[part 6 of 10: package /E40_Platform_System_SystemPackage/Components]
AUTOSAR XML (schema 4-2-1)
package /E40_Platform_System_SystemPackage/Components  (continued)
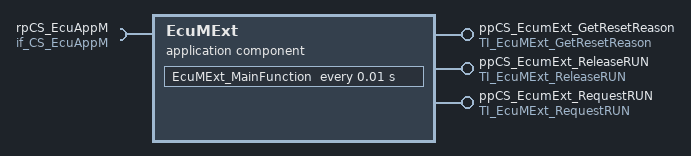
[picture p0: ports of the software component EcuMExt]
  application sw component type EcuMExt
    provide port ppCS_EcumExt_GetResetReason: server-com-spec{operation=GetResetReason, queue-length=1}, provided-interface=TI_EcuMExt_GetResetReason
    provide port ppCS_EcumExt_ReleaseRUN: server-com-spec{operation=ReleaseRUN, queue-length=1}, provided-interface=TI_EcuMExt_ReleaseRUN
    provide port ppCS_EcumExt_RequestRUN: server-com-spec{operation=RequestRUN, queue-length=1}, provided-interface=TI_EcuMExt_RequestRUN
    require port rpCS_EcuAppM: required-interface=if_CS_EcuAppM
    behavior IB_EcuMExt
      operation invoked event OIE_ppCS_EcumExt_GetResetReason_EcuMExt_GetResetReasonTrigByGetResetReason: start-on-event=EcuMExt_GetResetReason, operation=ppCS_EcumExt_GetResetReason.GetResetReason
      timing event TEEcuMExt_MainFunction: start-on-event=EcuMExt_MainFunction, period=0.01
      operation invoked event OIE_ppCS_EcumExt_ReleaseRUN_EcuMExt_ReleaseRUNTrigByReleaseRUN: start-on-event=EcuMExt_ReleaseRUN, operation=ppCS_EcumExt_ReleaseRUN.ReleaseRUN
      operation invoked event OIE_ppCS_EcumExt_RequestRUN_EcuMExt_RequestRUNTrigByRequestRUN: start-on-event=EcuMExt_RequestRUN, operation=ppCS_EcumExt_RequestRUN.RequestRUN
      port-api-options:
        enable-take-address=false, indirect-api=false, port=ppCS_EcumExt_GetResetReason
        enable-take-address=false, indirect-api=false, port=ppCS_EcumExt_ReleaseRUN
        enable-take-address=false, indirect-api=false, port=ppCS_EcumExt_RequestRUN
        enable-take-address=false, indirect-api=false, port=rpCS_EcuAppM
      4 x runnable, all with can-be-invoked-concurrently=true:
        EcuMExt_GetResetReason
          sync call OA_rpCS_EcuAppM_Init: operation=rpCS_EcuAppM.Init, timeout=0.0
          sync call OA_rpCS_EcuAppM_EcuAppM_SetWakeupSources: operation=rpCS_EcuAppM.EcuAppM_SetWakeupSources, timeout=0.0
        EcuMExt_MainFunction
          sync call OA_rpCS_EcuAppM_Init: operation=rpCS_EcuAppM.Init, timeout=0.0
          sync call OA_rpCS_EcuAppM_EcuAppM_SetWakeupSources: operation=rpCS_EcuAppM.EcuAppM_SetWakeupSources, timeout=0.0
        EcuMExt_ReleaseRUN
          sync call OA_rpCS_EcuAppM_Init: operation=rpCS_EcuAppM.Init, timeout=0.0
          sync call OA_rpCS_EcuAppM_EcuAppM_SetWakeupSources: operation=rpCS_EcuAppM.EcuAppM_SetWakeupSources, timeout=0.0
        EcuMExt_RequestRUN
          sync call OA_rpCS_EcuAppM_Init: operation=rpCS_EcuAppM.Init, timeout=0.0
          sync call OA_rpCS_EcuAppM_EcuAppM_SetWakeupSources: operation=rpCS_EcuAppM.EcuAppM_SetWakeupSources, timeout=0.0
  swc implementation IMPL_EcuMExt: programming-language=C, behavior=IB_EcuMExt
    code-descriptors:
      code CodeDescriptor
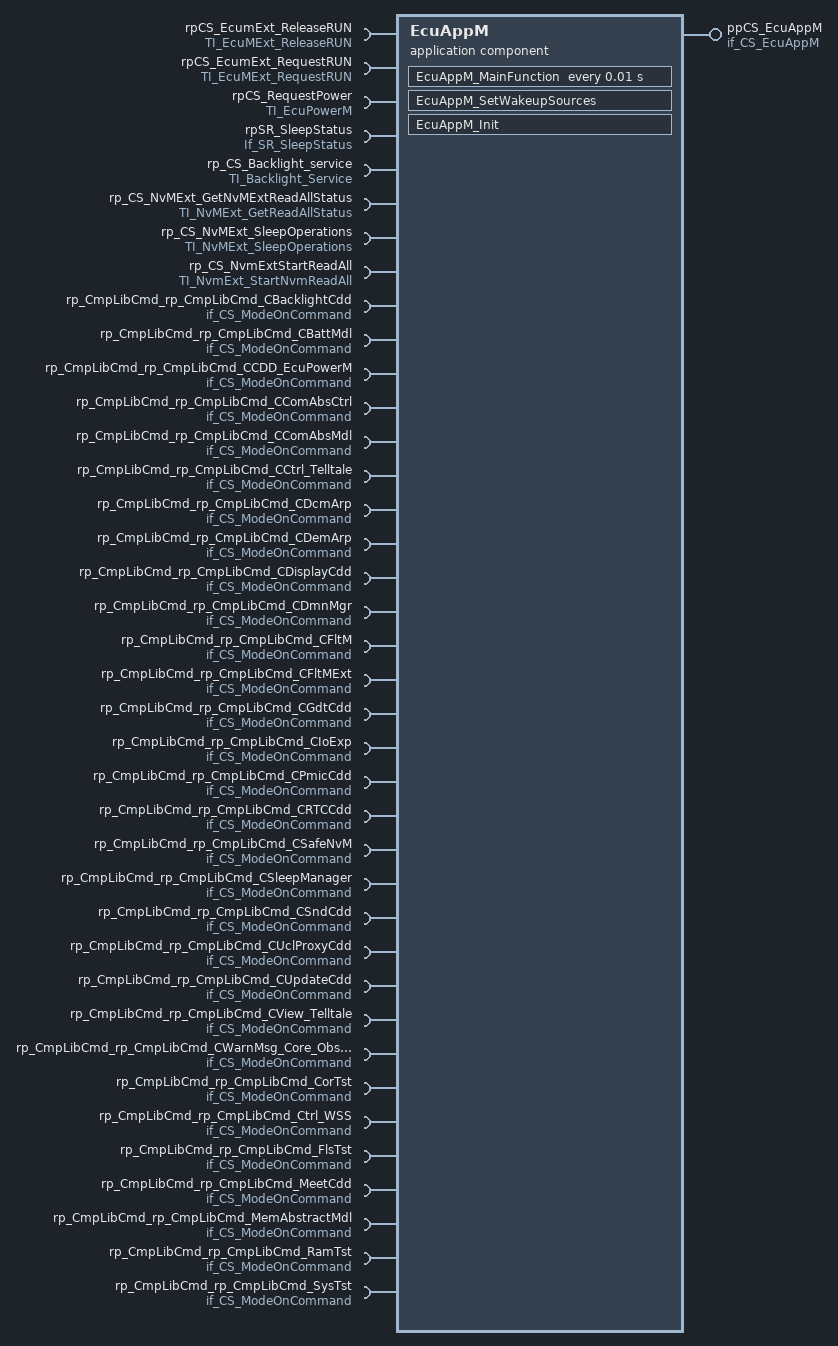
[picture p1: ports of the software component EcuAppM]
  application sw component type EcuAppM
    provide port ppCS_EcuAppM: provided-com-specs=[{operation=EcuAppM_SetWakeupSources, queue-length=1}, {operation=if_CS_EcuAppM/Init, queue-length=1}], provided-interface=if_CS_EcuAppM
    38 x require port:
      rpCS_EcumExt_ReleaseRUN: required-interface=TI_EcuMExt_ReleaseRUN
      rpCS_EcumExt_RequestRUN: required-interface=TI_EcuMExt_RequestRUN
      rpCS_RequestPower: required-interface=TI_EcuPowerM
      rpSR_SleepStatus: nonqueued-receiver-com-spec{data-element=SleepManager_SleepStatus, init-value=constant-reference=EcuAppMSleepManager_SleepStatusValue0}, required-interface=If_SR_SleepStatus
      rp_CS_Backlight_service: required-interface=TI_Backlight_Service
      rp_CS_NvMExt_GetNvMExtReadAllStatus: required-interface=TI_NvMExt_GetReadAllStatus
      rp_CS_NvMExt_SleepOperations: required-interface=TI_NvMExt_SleepOperations
      rp_CS_NvmExtStartReadAll: required-interface=TI_NvmExt_StartNvmReadAll
      rp_CmpLibCmd_rp_CmpLibCmd_CBacklightCdd: required-interface=if_CS_ModeOnCommand
      rp_CmpLibCmd_rp_CmpLibCmd_CBattMdl: required-interface=if_CS_ModeOnCommand
      rp_CmpLibCmd_rp_CmpLibCmd_CCDD_EcuPowerM: required-interface=if_CS_ModeOnCommand
      rp_CmpLibCmd_rp_CmpLibCmd_CComAbsCtrl: required-interface=if_CS_ModeOnCommand
      rp_CmpLibCmd_rp_CmpLibCmd_CComAbsMdl: required-interface=if_CS_ModeOnCommand
      rp_CmpLibCmd_rp_CmpLibCmd_CCtrl_Telltale: required-interface=if_CS_ModeOnCommand
      rp_CmpLibCmd_rp_CmpLibCmd_CDcmArp: required-interface=if_CS_ModeOnCommand
      rp_CmpLibCmd_rp_CmpLibCmd_CDemArp: required-interface=if_CS_ModeOnCommand
      rp_CmpLibCmd_rp_CmpLibCmd_CDisplayCdd: required-interface=if_CS_ModeOnCommand
      rp_CmpLibCmd_rp_CmpLibCmd_CDmnMgr: required-interface=if_CS_ModeOnCommand
      rp_CmpLibCmd_rp_CmpLibCmd_CFltM: required-interface=if_CS_ModeOnCommand
      rp_CmpLibCmd_rp_CmpLibCmd_CFltMExt: required-interface=if_CS_ModeOnCommand
      rp_CmpLibCmd_rp_CmpLibCmd_CGdtCdd: required-interface=if_CS_ModeOnCommand
      rp_CmpLibCmd_rp_CmpLibCmd_CIoExp: required-interface=if_CS_ModeOnCommand
      rp_CmpLibCmd_rp_CmpLibCmd_CPmicCdd: required-interface=if_CS_ModeOnCommand
      rp_CmpLibCmd_rp_CmpLibCmd_CRTCCdd: required-interface=if_CS_ModeOnCommand
      rp_CmpLibCmd_rp_CmpLibCmd_CSafeNvM: required-interface=if_CS_ModeOnCommand
      rp_CmpLibCmd_rp_CmpLibCmd_CSleepManager: required-interface=if_CS_ModeOnCommand
      rp_CmpLibCmd_rp_CmpLibCmd_CSndCdd: required-interface=if_CS_ModeOnCommand
      rp_CmpLibCmd_rp_CmpLibCmd_CUclProxyCdd: required-interface=if_CS_ModeOnCommand
      rp_CmpLibCmd_rp_CmpLibCmd_CUpdateCdd: required-interface=if_CS_ModeOnCommand
      rp_CmpLibCmd_rp_CmpLibCmd_CView_Telltale: required-interface=if_CS_ModeOnCommand
      rp_CmpLibCmd_rp_CmpLibCmd_CWarnMsg_Core_Observer: required-interface=if_CS_ModeOnCommand
      rp_CmpLibCmd_rp_CmpLibCmd_CorTst: required-interface=if_CS_ModeOnCommand
      rp_CmpLibCmd_rp_CmpLibCmd_Ctrl_WSS: required-interface=if_CS_ModeOnCommand
      rp_CmpLibCmd_rp_CmpLibCmd_FlsTst: required-interface=if_CS_ModeOnCommand
      rp_CmpLibCmd_rp_CmpLibCmd_MeetCdd: required-interface=if_CS_ModeOnCommand
      rp_CmpLibCmd_rp_CmpLibCmd_MemAbstractMdl: required-interface=if_CS_ModeOnCommand
      rp_CmpLibCmd_rp_CmpLibCmd_RamTst: required-interface=if_CS_ModeOnCommand
      rp_CmpLibCmd_rp_CmpLibCmd_SysTst: required-interface=if_CS_ModeOnCommand
    behavior IB_EcuAppM
      operation invoked event OIE_ppCS_EcuAppM_EcuAppM_SetWakeupSourcesTrigByEcuAppM_SetWakeupSources: start-on-event=EcuAppM_SetWakeupSources, operation=ppCS_EcuAppM.EcuAppM_SetWakeupSources
      operation invoked event OIE_ppCS_EcuAppM_EcuAppM_InitTrigByInit: start-on-event=EcuAppM_Init, operation=ppCS_EcuAppM.Init
      timing event TEEcuAppM_MainFunction: start-on-event=EcuAppM_MainFunction, period=0.01
      port-api-options:
        enable-take-address=false, indirect-api=false, port=ppCS_EcuAppM
        enable-take-address=false, indirect-api=false, port=rpCS_EcumExt_ReleaseRUN
        enable-take-address=false, indirect-api=false, port=rpCS_EcumExt_RequestRUN
        enable-take-address=false, indirect-api=false, port=rpCS_RequestPower
        enable-take-address=false, indirect-api=false, port=EcuAppM/rpSR_SleepStatus
        enable-take-address=false, indirect-api=false, port=rp_CS_Backlight_service
        enable-take-address=false, indirect-api=false, port=EcuAppM/rp_CS_NvMExt_GetNvMExtReadAllStatus
        enable-take-address=false, indirect-api=false, port=EcuAppM/rp_CS_NvMExt_SleepOperations
        enable-take-address=false, indirect-api=false, port=rp_CS_NvmExtStartReadAll
        enable-take-address=false, indirect-api=false, port=rp_CmpLibCmd_rp_CmpLibCmd_CBacklightCdd
        enable-take-address=false, indirect-api=false, port=rp_CmpLibCmd_rp_CmpLibCmd_CBattMdl
        enable-take-address=false, indirect-api=false, port=rp_CmpLibCmd_rp_CmpLibCmd_CCDD_EcuPowerM
        enable-take-address=false, indirect-api=false, port=rp_CmpLibCmd_rp_CmpLibCmd_CComAbsCtrl
        enable-take-address=false, indirect-api=false, port=rp_CmpLibCmd_rp_CmpLibCmd_CComAbsMdl
        enable-take-address=false, indirect-api=false, port=rp_CmpLibCmd_rp_CmpLibCmd_CCtrl_Telltale
        enable-take-address=false, indirect-api=false, port=rp_CmpLibCmd_rp_CmpLibCmd_CDcmArp
        enable-take-address=false, indirect-api=false, port=rp_CmpLibCmd_rp_CmpLibCmd_CDemArp
        enable-take-address=false, indirect-api=false, port=rp_CmpLibCmd_rp_CmpLibCmd_CDisplayCdd
        enable-take-address=false, indirect-api=false, port=rp_CmpLibCmd_rp_CmpLibCmd_CDmnMgr
        enable-take-address=false, indirect-api=false, port=rp_CmpLibCmd_rp_CmpLibCmd_CFltM
        enable-take-address=false, indirect-api=false, port=rp_CmpLibCmd_rp_CmpLibCmd_CFltMExt
        enable-take-address=false, indirect-api=false, port=rp_CmpLibCmd_rp_CmpLibCmd_CGdtCdd
        enable-take-address=false, indirect-api=false, port=rp_CmpLibCmd_rp_CmpLibCmd_CIoExp
        enable-take-address=false, indirect-api=false, port=rp_CmpLibCmd_rp_CmpLibCmd_CPmicCdd
        enable-take-address=false, indirect-api=false, port=rp_CmpLibCmd_rp_CmpLibCmd_CRTCCdd
        enable-take-address=false, indirect-api=false, port=rp_CmpLibCmd_rp_CmpLibCmd_CSafeNvM
        enable-take-address=false, indirect-api=false, port=rp_CmpLibCmd_rp_CmpLibCmd_CSleepManager
        enable-take-address=false, indirect-api=false, port=rp_CmpLibCmd_rp_CmpLibCmd_CSndCdd
        enable-take-address=false, indirect-api=false, port=rp_CmpLibCmd_rp_CmpLibCmd_CUclProxyCdd
        enable-take-address=false, indirect-api=false, port=rp_CmpLibCmd_rp_CmpLibCmd_CUpdateCdd
        enable-take-address=false, indirect-api=false, port=rp_CmpLibCmd_rp_CmpLibCmd_CView_Telltale
        enable-take-address=false, indirect-api=false, port=rp_CmpLibCmd_rp_CmpLibCmd_CWarnMsg_Core_Observer
        enable-take-address=false, indirect-api=false, port=rp_CmpLibCmd_rp_CmpLibCmd_CorTst
        enable-take-address=false, indirect-api=false, port=rp_CmpLibCmd_rp_CmpLibCmd_Ctrl_WSS
        enable-take-address=false, indirect-api=false, port=rp_CmpLibCmd_rp_CmpLibCmd_FlsTst
        enable-take-address=false, indirect-api=false, port=rp_CmpLibCmd_rp_CmpLibCmd_MeetCdd
        enable-take-address=false, indirect-api=false, port=rp_CmpLibCmd_rp_CmpLibCmd_MemAbstractMdl
        enable-take-address=false, indirect-api=false, port=rp_CmpLibCmd_rp_CmpLibCmd_RamTst
        enable-take-address=false, indirect-api=false, port=rp_CmpLibCmd_rp_CmpLibCmd_SysTst
      runnable EcuAppM_SetWakeupSources: can-be-invoked-concurrently=true
        data-receive-point-by-arguments:
          access DRA_rpSR_SleepStatus_SleepManager_SleepStatus: accessed-variable=rpSR_SleepStatus.SleepManager_SleepStatus
        42 x sync call, all with timeout=0.0:
          OA_rpCS_EcumExt_ReleaseRUN_ReleaseRUN: operation=rpCS_EcumExt_ReleaseRUN.ReleaseRUN
          OA_rpCS_EcumExt_RequestRUN_RequestRUN: operation=rpCS_EcumExt_RequestRUN.RequestRUN
          OA_rpCS_RequestPower_EcuPowerM_RequestPower: operation=rpCS_RequestPower.EcuPowerM_RequestPower
          OA_rpCS_RequestPower_EcuPowerM_GetDeviceStatus: operation=rpCS_RequestPower.EcuPowerM_GetDeviceStatus
          OA_rp_CS_Backlight_service_SetBrightnessValue: operation=rp_CS_Backlight_service.SetBrightnessValue
          OA_rp_CS_Backlight_service_GetBrightnessValue: operation=rp_CS_Backlight_service.GetBrightnessValue
          OA_rp_CS_Backlight_service_GetThermalValue: operation=rp_CS_Backlight_service.GetThermalValue
          OA_rp_CS_NvMExt_GetNvMExtReadAllStatus_NvmExt_GetNvMReadAllStatus: operation=rp_CS_NvMExt_GetNvMExtReadAllStatus.NvmExt_GetNvMReadAllStatus
          OA_rp_CS_NvMExt_SleepOperations_NvMExt_ReadytoSleep: operation=rp_CS_NvMExt_SleepOperations.NvMExt_ReadytoSleep
          OA_rp_CS_NvMExt_SleepOperations_NvMExt_RequestSleep: operation=rp_CS_NvMExt_SleepOperations.NvMExt_RequestSleep
          OA_rp_CS_NvMExt_SleepOperations_NvMExt_CancelSleep: operation=rp_CS_NvMExt_SleepOperations.NvMExt_CancelSleep
          OA_rp_CS_NvmExtStartReadAll_NvMExt_ReadAll: operation=rp_CS_NvmExtStartReadAll.NvMExt_ReadAll
          OA_rp_CmpLibCmd_rp_CmpLibCmd_CBacklightCdd_Impl_OnCommand: operation=rp_CmpLibCmd_rp_CmpLibCmd_CBacklightCdd.Impl_OnCommand
          OA_rp_CmpLibCmd_rp_CmpLibCmd_CBattMdl_Impl_OnCommand: operation=rp_CmpLibCmd_rp_CmpLibCmd_CBattMdl.Impl_OnCommand
          OA_rp_CmpLibCmd_rp_CmpLibCmd_CCDD_EcuPowerM_Impl_OnCommand: operation=rp_CmpLibCmd_rp_CmpLibCmd_CCDD_EcuPowerM.Impl_OnCommand
          OA_rp_CmpLibCmd_rp_CmpLibCmd_CComAbsCtrl_Impl_OnCommand: operation=rp_CmpLibCmd_rp_CmpLibCmd_CComAbsCtrl.Impl_OnCommand
          OA_rp_CmpLibCmd_rp_CmpLibCmd_CComAbsMdl_Impl_OnCommand: operation=rp_CmpLibCmd_rp_CmpLibCmd_CComAbsMdl.Impl_OnCommand
          OA_rp_CmpLibCmd_rp_CmpLibCmd_CCtrl_Telltale_Impl_OnCommand: operation=rp_CmpLibCmd_rp_CmpLibCmd_CCtrl_Telltale.Impl_OnCommand
          OA_rp_CmpLibCmd_rp_CmpLibCmd_CDcmArp_Impl_OnCommand: operation=rp_CmpLibCmd_rp_CmpLibCmd_CDcmArp.Impl_OnCommand
          OA_rp_CmpLibCmd_rp_CmpLibCmd_CDemArp_Impl_OnCommand: operation=rp_CmpLibCmd_rp_CmpLibCmd_CDemArp.Impl_OnCommand
          OA_rp_CmpLibCmd_rp_CmpLibCmd_CDisplayCdd_Impl_OnCommand: operation=rp_CmpLibCmd_rp_CmpLibCmd_CDisplayCdd.Impl_OnCommand
          OA_rp_CmpLibCmd_rp_CmpLibCmd_CDmnMgr_Impl_OnCommand: operation=rp_CmpLibCmd_rp_CmpLibCmd_CDmnMgr.Impl_OnCommand
          OA_rp_CmpLibCmd_rp_CmpLibCmd_CFltM_Impl_OnCommand: operation=rp_CmpLibCmd_rp_CmpLibCmd_CFltM.Impl_OnCommand
          OA_rp_CmpLibCmd_rp_CmpLibCmd_CFltMExt_Impl_OnCommand: operation=rp_CmpLibCmd_rp_CmpLibCmd_CFltMExt.Impl_OnCommand
          OA_rp_CmpLibCmd_rp_CmpLibCmd_CGdtCdd_Impl_OnCommand: operation=rp_CmpLibCmd_rp_CmpLibCmd_CGdtCdd.Impl_OnCommand
          OA_rp_CmpLibCmd_rp_CmpLibCmd_CIoExp_Impl_OnCommand: operation=rp_CmpLibCmd_rp_CmpLibCmd_CIoExp.Impl_OnCommand
          OA_rp_CmpLibCmd_rp_CmpLibCmd_CPmicCdd_Impl_OnCommand: operation=rp_CmpLibCmd_rp_CmpLibCmd_CPmicCdd.Impl_OnCommand
          OA_rp_CmpLibCmd_rp_CmpLibCmd_CRTCCdd_Impl_OnCommand: operation=rp_CmpLibCmd_rp_CmpLibCmd_CRTCCdd.Impl_OnCommand
          OA_rp_CmpLibCmd_rp_CmpLibCmd_CSafeNvM_Impl_OnCommand: operation=rp_CmpLibCmd_rp_CmpLibCmd_CSafeNvM.Impl_OnCommand
          OA_rp_CmpLibCmd_rp_CmpLibCmd_CSleepManager_Impl_OnCommand: operation=rp_CmpLibCmd_rp_CmpLibCmd_CSleepManager.Impl_OnCommand
          OA_rp_CmpLibCmd_rp_CmpLibCmd_CSndCdd_Impl_OnCommand: operation=rp_CmpLibCmd_rp_CmpLibCmd_CSndCdd.Impl_OnCommand
          OA_rp_CmpLibCmd_rp_CmpLibCmd_CUclProxyCdd_Impl_OnCommand: operation=rp_CmpLibCmd_rp_CmpLibCmd_CUclProxyCdd.Impl_OnCommand
          OA_rp_CmpLibCmd_rp_CmpLibCmd_CUpdateCdd_Impl_OnCommand: operation=rp_CmpLibCmd_rp_CmpLibCmd_CUpdateCdd.Impl_OnCommand
          OA_rp_CmpLibCmd_rp_CmpLibCmd_CView_Telltale_Impl_OnCommand: operation=rp_CmpLibCmd_rp_CmpLibCmd_CView_Telltale.Impl_OnCommand
          OA_rp_CmpLibCmd_rp_CmpLibCmd_CWarnMsg_Core_Observer_Impl_OnCommand: operation=rp_CmpLibCmd_rp_CmpLibCmd_CWarnMsg_Core_Observer.Impl_OnCommand
          OA_rp_CmpLibCmd_rp_CmpLibCmd_CorTst_Impl_OnCommand: operation=rp_CmpLibCmd_rp_CmpLibCmd_CorTst.Impl_OnCommand
          OA_rp_CmpLibCmd_rp_CmpLibCmd_Ctrl_WSS_Impl_OnCommand: operation=rp_CmpLibCmd_rp_CmpLibCmd_Ctrl_WSS.Impl_OnCommand
          OA_rp_CmpLibCmd_rp_CmpLibCmd_FlsTst_Impl_OnCommand: operation=rp_CmpLibCmd_rp_CmpLibCmd_FlsTst.Impl_OnCommand
          OA_rp_CmpLibCmd_rp_CmpLibCmd_MeetCdd_Impl_OnCommand: operation=rp_CmpLibCmd_rp_CmpLibCmd_MeetCdd.Impl_OnCommand
          OA_rp_CmpLibCmd_rp_CmpLibCmd_MemAbstractMdl_Impl_OnCommand: operation=rp_CmpLibCmd_rp_CmpLibCmd_MemAbstractMdl.Impl_OnCommand
          OA_rp_CmpLibCmd_rp_CmpLibCmd_RamTst_Impl_OnCommand: operation=rp_CmpLibCmd_rp_CmpLibCmd_RamTst.Impl_OnCommand
          OA_rp_CmpLibCmd_rp_CmpLibCmd_SysTst_Impl_OnCommand: operation=rp_CmpLibCmd_rp_CmpLibCmd_SysTst.Impl_OnCommand
      runnable EcuAppM_Init: can-be-invoked-concurrently=true
        data-receive-point-by-arguments:
          access DRA_rpSR_SleepStatus_SleepManager_SleepStatus: accessed-variable=rpSR_SleepStatus.SleepManager_SleepStatus
        42 x sync call, all with timeout=0.0:
          OA_rpCS_EcumExt_ReleaseRUN_ReleaseRUN: operation=rpCS_EcumExt_ReleaseRUN.ReleaseRUN
          OA_rpCS_EcumExt_RequestRUN_RequestRUN: operation=rpCS_EcumExt_RequestRUN.RequestRUN
          OA_rpCS_RequestPower_EcuPowerM_RequestPower: operation=rpCS_RequestPower.EcuPowerM_RequestPower
          OA_rpCS_RequestPower_EcuPowerM_GetDeviceStatus: operation=rpCS_RequestPower.EcuPowerM_GetDeviceStatus
          OA_rp_CS_Backlight_service_SetBrightnessValue: operation=rp_CS_Backlight_service.SetBrightnessValue
          OA_rp_CS_Backlight_service_GetBrightnessValue: operation=rp_CS_Backlight_service.GetBrightnessValue
          OA_rp_CS_Backlight_service_GetThermalValue: operation=rp_CS_Backlight_service.GetThermalValue
          OA_rp_CS_NvMExt_GetNvMExtReadAllStatus_NvmExt_GetNvMReadAllStatus: operation=rp_CS_NvMExt_GetNvMExtReadAllStatus.NvmExt_GetNvMReadAllStatus
          OA_rp_CS_NvMExt_SleepOperations_NvMExt_ReadytoSleep: operation=rp_CS_NvMExt_SleepOperations.NvMExt_ReadytoSleep
          OA_rp_CS_NvMExt_SleepOperations_NvMExt_RequestSleep: operation=rp_CS_NvMExt_SleepOperations.NvMExt_RequestSleep
          OA_rp_CS_NvMExt_SleepOperations_NvMExt_CancelSleep: operation=rp_CS_NvMExt_SleepOperations.NvMExt_CancelSleep
          OA_rp_CS_NvmExtStartReadAll_NvMExt_ReadAll: operation=rp_CS_NvmExtStartReadAll.NvMExt_ReadAll
          OA_rp_CmpLibCmd_rp_CmpLibCmd_CBacklightCdd_Impl_OnCommand: operation=rp_CmpLibCmd_rp_CmpLibCmd_CBacklightCdd.Impl_OnCommand
          OA_rp_CmpLibCmd_rp_CmpLibCmd_CBattMdl_Impl_OnCommand: operation=rp_CmpLibCmd_rp_CmpLibCmd_CBattMdl.Impl_OnCommand
          OA_rp_CmpLibCmd_rp_CmpLibCmd_CCDD_EcuPowerM_Impl_OnCommand: operation=rp_CmpLibCmd_rp_CmpLibCmd_CCDD_EcuPowerM.Impl_OnCommand
          OA_rp_CmpLibCmd_rp_CmpLibCmd_CComAbsCtrl_Impl_OnCommand: operation=rp_CmpLibCmd_rp_CmpLibCmd_CComAbsCtrl.Impl_OnCommand
          OA_rp_CmpLibCmd_rp_CmpLibCmd_CComAbsMdl_Impl_OnCommand: operation=rp_CmpLibCmd_rp_CmpLibCmd_CComAbsMdl.Impl_OnCommand
          OA_rp_CmpLibCmd_rp_CmpLibCmd_CCtrl_Telltale_Impl_OnCommand: operation=rp_CmpLibCmd_rp_CmpLibCmd_CCtrl_Telltale.Impl_OnCommand
          OA_rp_CmpLibCmd_rp_CmpLibCmd_CDcmArp_Impl_OnCommand: operation=rp_CmpLibCmd_rp_CmpLibCmd_CDcmArp.Impl_OnCommand
          OA_rp_CmpLibCmd_rp_CmpLibCmd_CDemArp_Impl_OnCommand: operation=rp_CmpLibCmd_rp_CmpLibCmd_CDemArp.Impl_OnCommand
          OA_rp_CmpLibCmd_rp_CmpLibCmd_CDisplayCdd_Impl_OnCommand: operation=rp_CmpLibCmd_rp_CmpLibCmd_CDisplayCdd.Impl_OnCommand
          OA_rp_CmpLibCmd_rp_CmpLibCmd_CDmnMgr_Impl_OnCommand: operation=rp_CmpLibCmd_rp_CmpLibCmd_CDmnMgr.Impl_OnCommand
          OA_rp_CmpLibCmd_rp_CmpLibCmd_CFltM_Impl_OnCommand: operation=rp_CmpLibCmd_rp_CmpLibCmd_CFltM.Impl_OnCommand
          OA_rp_CmpLibCmd_rp_CmpLibCmd_CFltMExt_Impl_OnCommand: operation=rp_CmpLibCmd_rp_CmpLibCmd_CFltMExt.Impl_OnCommand
          OA_rp_CmpLibCmd_rp_CmpLibCmd_CGdtCdd_Impl_OnCommand: operation=rp_CmpLibCmd_rp_CmpLibCmd_CGdtCdd.Impl_OnCommand
          OA_rp_CmpLibCmd_rp_CmpLibCmd_CIoExp_Impl_OnCommand: operation=rp_CmpLibCmd_rp_CmpLibCmd_CIoExp.Impl_OnCommand
          OA_rp_CmpLibCmd_rp_CmpLibCmd_CPmicCdd_Impl_OnCommand: operation=rp_CmpLibCmd_rp_CmpLibCmd_CPmicCdd.Impl_OnCommand
          OA_rp_CmpLibCmd_rp_CmpLibCmd_CRTCCdd_Impl_OnCommand: operation=rp_CmpLibCmd_rp_CmpLibCmd_CRTCCdd.Impl_OnCommand
          OA_rp_CmpLibCmd_rp_CmpLibCmd_CSafeNvM_Impl_OnCommand: operation=rp_CmpLibCmd_rp_CmpLibCmd_CSafeNvM.Impl_OnCommand
          OA_rp_CmpLibCmd_rp_CmpLibCmd_CSleepManager_Impl_OnCommand: operation=rp_CmpLibCmd_rp_CmpLibCmd_CSleepManager.Impl_OnCommand
          OA_rp_CmpLibCmd_rp_CmpLibCmd_CSndCdd_Impl_OnCommand: operation=rp_CmpLibCmd_rp_CmpLibCmd_CSndCdd.Impl_OnCommand
          OA_rp_CmpLibCmd_rp_CmpLibCmd_CUclProxyCdd_Impl_OnCommand: operation=rp_CmpLibCmd_rp_CmpLibCmd_CUclProxyCdd.Impl_OnCommand
          OA_rp_CmpLibCmd_rp_CmpLibCmd_CUpdateCdd_Impl_OnCommand: operation=rp_CmpLibCmd_rp_CmpLibCmd_CUpdateCdd.Impl_OnCommand
          OA_rp_CmpLibCmd_rp_CmpLibCmd_CView_Telltale_Impl_OnCommand: operation=rp_CmpLibCmd_rp_CmpLibCmd_CView_Telltale.Impl_OnCommand
          OA_rp_CmpLibCmd_rp_CmpLibCmd_CWarnMsg_Core_Observer_Impl_OnCommand: operation=rp_CmpLibCmd_rp_CmpLibCmd_CWarnMsg_Core_Observer.Impl_OnCommand
          OA_rp_CmpLibCmd_rp_CmpLibCmd_CorTst_Impl_OnCommand: operation=rp_CmpLibCmd_rp_CmpLibCmd_CorTst.Impl_OnCommand
          OA_rp_CmpLibCmd_rp_CmpLibCmd_Ctrl_WSS_Impl_OnCommand: operation=rp_CmpLibCmd_rp_CmpLibCmd_Ctrl_WSS.Impl_OnCommand
          OA_rp_CmpLibCmd_rp_CmpLibCmd_FlsTst_Impl_OnCommand: operation=rp_CmpLibCmd_rp_CmpLibCmd_FlsTst.Impl_OnCommand
          OA_rp_CmpLibCmd_rp_CmpLibCmd_MeetCdd_Impl_OnCommand: operation=rp_CmpLibCmd_rp_CmpLibCmd_MeetCdd.Impl_OnCommand
          OA_rp_CmpLibCmd_rp_CmpLibCmd_MemAbstractMdl_Impl_OnCommand: operation=rp_CmpLibCmd_rp_CmpLibCmd_MemAbstractMdl.Impl_OnCommand
          OA_rp_CmpLibCmd_rp_CmpLibCmd_RamTst_Impl_OnCommand: operation=rp_CmpLibCmd_rp_CmpLibCmd_RamTst.Impl_OnCommand
          OA_rp_CmpLibCmd_rp_CmpLibCmd_SysTst_Impl_OnCommand: operation=rp_CmpLibCmd_rp_CmpLibCmd_SysTst.Impl_OnCommand
      runnable EcuAppM_MainFunction: can-be-invoked-concurrently=true
        data-receive-point-by-arguments:
          access DRA_rpSR_SleepStatus_SleepManager_SleepStatus: accessed-variable=rpSR_SleepStatus.SleepManager_SleepStatus
        42 x sync call, all with timeout=0.0:
          OA_rpCS_EcumExt_ReleaseRUN_ReleaseRUN: operation=rpCS_EcumExt_ReleaseRUN.ReleaseRUN
          OA_rpCS_EcumExt_RequestRUN_RequestRUN: operation=rpCS_EcumExt_RequestRUN.RequestRUN
          OA_rpCS_RequestPower_EcuPowerM_RequestPower: operation=rpCS_RequestPower.EcuPowerM_RequestPower
          OA_rpCS_RequestPower_EcuPowerM_GetDeviceStatus: operation=rpCS_RequestPower.EcuPowerM_GetDeviceStatus
          OA_rp_CS_Backlight_service_SetBrightnessValue: operation=rp_CS_Backlight_service.SetBrightnessValue
          OA_rp_CS_Backlight_service_GetBrightnessValue: operation=rp_CS_Backlight_service.GetBrightnessValue
          OA_rp_CS_Backlight_service_GetThermalValue: operation=rp_CS_Backlight_service.GetThermalValue
          OA_rp_CS_NvMExt_GetNvMExtReadAllStatus_NvmExt_GetNvMReadAllStatus: operation=rp_CS_NvMExt_GetNvMExtReadAllStatus.NvmExt_GetNvMReadAllStatus
          OA_rp_CS_NvMExt_SleepOperations_NvMExt_ReadytoSleep: operation=rp_CS_NvMExt_SleepOperations.NvMExt_ReadytoSleep
          OA_rp_CS_NvMExt_SleepOperations_NvMExt_RequestSleep: operation=rp_CS_NvMExt_SleepOperations.NvMExt_RequestSleep
          OA_rp_CS_NvMExt_SleepOperations_NvMExt_CancelSleep: operation=rp_CS_NvMExt_SleepOperations.NvMExt_CancelSleep
          OA_rp_CS_NvmExtStartReadAll_NvMExt_ReadAll: operation=rp_CS_NvmExtStartReadAll.NvMExt_ReadAll
          OA_rp_CmpLibCmd_rp_CmpLibCmd_CBacklightCdd_Impl_OnCommand: operation=rp_CmpLibCmd_rp_CmpLibCmd_CBacklightCdd.Impl_OnCommand
          OA_rp_CmpLibCmd_rp_CmpLibCmd_CBattMdl_Impl_OnCommand: operation=rp_CmpLibCmd_rp_CmpLibCmd_CBattMdl.Impl_OnCommand
          OA_rp_CmpLibCmd_rp_CmpLibCmd_CCDD_EcuPowerM_Impl_OnCommand: operation=rp_CmpLibCmd_rp_CmpLibCmd_CCDD_EcuPowerM.Impl_OnCommand
          OA_rp_CmpLibCmd_rp_CmpLibCmd_CComAbsCtrl_Impl_OnCommand: operation=rp_CmpLibCmd_rp_CmpLibCmd_CComAbsCtrl.Impl_OnCommand
          OA_rp_CmpLibCmd_rp_CmpLibCmd_CComAbsMdl_Impl_OnCommand: operation=rp_CmpLibCmd_rp_CmpLibCmd_CComAbsMdl.Impl_OnCommand
          OA_rp_CmpLibCmd_rp_CmpLibCmd_CCtrl_Telltale_Impl_OnCommand: operation=rp_CmpLibCmd_rp_CmpLibCmd_CCtrl_Telltale.Impl_OnCommand
          OA_rp_CmpLibCmd_rp_CmpLibCmd_CDcmArp_Impl_OnCommand: operation=rp_CmpLibCmd_rp_CmpLibCmd_CDcmArp.Impl_OnCommand
          OA_rp_CmpLibCmd_rp_CmpLibCmd_CDemArp_Impl_OnCommand: operation=rp_CmpLibCmd_rp_CmpLibCmd_CDemArp.Impl_OnCommand
          OA_rp_CmpLibCmd_rp_CmpLibCmd_CDisplayCdd_Impl_OnCommand: operation=rp_CmpLibCmd_rp_CmpLibCmd_CDisplayCdd.Impl_OnCommand
          OA_rp_CmpLibCmd_rp_CmpLibCmd_CDmnMgr_Impl_OnCommand: operation=rp_CmpLibCmd_rp_CmpLibCmd_CDmnMgr.Impl_OnCommand
          OA_rp_CmpLibCmd_rp_CmpLibCmd_CFltM_Impl_OnCommand: operation=rp_CmpLibCmd_rp_CmpLibCmd_CFltM.Impl_OnCommand
          OA_rp_CmpLibCmd_rp_CmpLibCmd_CFltMExt_Impl_OnCommand: operation=rp_CmpLibCmd_rp_CmpLibCmd_CFltMExt.Impl_OnCommand
          OA_rp_CmpLibCmd_rp_CmpLibCmd_CGdtCdd_Impl_OnCommand: operation=rp_CmpLibCmd_rp_CmpLibCmd_CGdtCdd.Impl_OnCommand
          OA_rp_CmpLibCmd_rp_CmpLibCmd_CIoExp_Impl_OnCommand: operation=rp_CmpLibCmd_rp_CmpLibCmd_CIoExp.Impl_OnCommand
          OA_rp_CmpLibCmd_rp_CmpLibCmd_CPmicCdd_Impl_OnCommand: operation=rp_CmpLibCmd_rp_CmpLibCmd_CPmicCdd.Impl_OnCommand
          OA_rp_CmpLibCmd_rp_CmpLibCmd_CRTCCdd_Impl_OnCommand: operation=rp_CmpLibCmd_rp_CmpLibCmd_CRTCCdd.Impl_OnCommand
          OA_rp_CmpLibCmd_rp_CmpLibCmd_CSafeNvM_Impl_OnCommand: operation=rp_CmpLibCmd_rp_CmpLibCmd_CSafeNvM.Impl_OnCommand
          OA_rp_CmpLibCmd_rp_CmpLibCmd_CSleepManager_Impl_OnCommand: operation=rp_CmpLibCmd_rp_CmpLibCmd_CSleepManager.Impl_OnCommand
          OA_rp_CmpLibCmd_rp_CmpLibCmd_CSndCdd_Impl_OnCommand: operation=rp_CmpLibCmd_rp_CmpLibCmd_CSndCdd.Impl_OnCommand
          OA_rp_CmpLibCmd_rp_CmpLibCmd_CUclProxyCdd_Impl_OnCommand: operation=rp_CmpLibCmd_rp_CmpLibCmd_CUclProxyCdd.Impl_OnCommand
          OA_rp_CmpLibCmd_rp_CmpLibCmd_CUpdateCdd_Impl_OnCommand: operation=rp_CmpLibCmd_rp_CmpLibCmd_CUpdateCdd.Impl_OnCommand
          OA_rp_CmpLibCmd_rp_CmpLibCmd_CView_Telltale_Impl_OnCommand: operation=rp_CmpLibCmd_rp_CmpLibCmd_CView_Telltale.Impl_OnCommand
          OA_rp_CmpLibCmd_rp_CmpLibCmd_CWarnMsg_Core_Observer_Impl_OnCommand: operation=rp_CmpLibCmd_rp_CmpLibCmd_CWarnMsg_Core_Observer.Impl_OnCommand
          OA_rp_CmpLibCmd_rp_CmpLibCmd_CorTst_Impl_OnCommand: operation=rp_CmpLibCmd_rp_CmpLibCmd_CorTst.Impl_OnCommand
          OA_rp_CmpLibCmd_rp_CmpLibCmd_Ctrl_WSS_Impl_OnCommand: operation=rp_CmpLibCmd_rp_CmpLibCmd_Ctrl_WSS.Impl_OnCommand
          OA_rp_CmpLibCmd_rp_CmpLibCmd_FlsTst_Impl_OnCommand: operation=rp_CmpLibCmd_rp_CmpLibCmd_FlsTst.Impl_OnCommand
          OA_rp_CmpLibCmd_rp_CmpLibCmd_MeetCdd_Impl_OnCommand: operation=rp_CmpLibCmd_rp_CmpLibCmd_MeetCdd.Impl_OnCommand
          OA_rp_CmpLibCmd_rp_CmpLibCmd_MemAbstractMdl_Impl_OnCommand: operation=rp_CmpLibCmd_rp_CmpLibCmd_MemAbstractMdl.Impl_OnCommand
          OA_rp_CmpLibCmd_rp_CmpLibCmd_RamTst_Impl_OnCommand: operation=rp_CmpLibCmd_rp_CmpLibCmd_RamTst.Impl_OnCommand
          OA_rp_CmpLibCmd_rp_CmpLibCmd_SysTst_Impl_OnCommand: operation=rp_CmpLibCmd_rp_CmpLibCmd_SysTst.Impl_OnCommand
  constant specification EcuAppMSleepManager_SleepStatusValue0: value-spec=EcuAppMSleepManager_SleepStatusValue0:0
  swc implementation IMPL_EcuAppM: programming-language=C, behavior=IB_EcuAppM
    code-descriptors:
      code CodeDescriptor
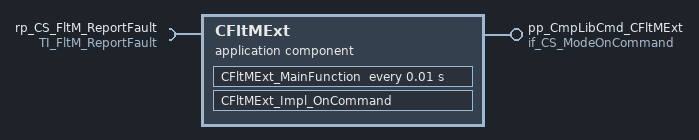
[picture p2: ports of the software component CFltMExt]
  application sw component type CFltMExt
    provide port pp_CmpLibCmd_CFltMExt: server-com-spec{operation=Impl_OnCommand, queue-length=1}, provided-interface=if_CS_ModeOnCommand
    require port rp_CS_FltM_ReportFault: required-interface=TI_FltM_ReportFault
    behavior IB_CFltMExt
      operation invoked event OIE_pp_CmpLibCmd_CFltMExt_CFltMExt_Impl_OnCommandTrigByImpl_OnCommand: start-on-event=CFltMExt_Impl_OnCommand, operation=pp_CmpLibCmd_CFltMExt.Impl_OnCommand
      timing event TECFltMExt_MainFunction: start-on-event=CFltMExt_MainFunction, period=0.01
      port-api-options:
        enable-take-address=false, indirect-api=false, port=pp_CmpLibCmd_CFltMExt
        enable-take-address=false, indirect-api=false, port=rp_CS_FltM_ReportFault
      runnable CFltMExt_Impl_OnCommand: can-be-invoked-concurrently=true
        sync call OA_rp_CS_FltM_ReportFault_FltM_ReportFault: operation=rp_CS_FltM_ReportFault.FltM_ReportFault, timeout=0.0
      runnable CFltMExt_MainFunction: can-be-invoked-concurrently=true
        sync call OA_rp_CS_FltM_ReportFault_FltM_ReportFault: operation=rp_CS_FltM_ReportFault.FltM_ReportFault, timeout=0.0
  swc implementation IMPL_CFltMExt: programming-language=C, behavior=IB_CFltMExt
    code-descriptors:
      code CodeDescriptor
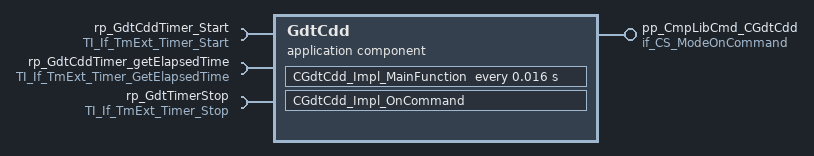
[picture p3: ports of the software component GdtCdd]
  application sw component type GdtCdd
    provide port pp_CmpLibCmd_CGdtCdd: server-com-spec{operation=Impl_OnCommand, queue-length=1}, provided-interface=if_CS_ModeOnCommand
    require port rp_GdtCddTimer_Start: required-interface=TI_If_TmExt_Timer_Start
    require port rp_GdtCddTimer_getElapsedTime: required-interface=TI_If_TmExt_Timer_GetElapsedTime
    require port rp_GdtTimerStop: required-interface=TI_If_TmExt_Timer_Stop
    behavior IB_GdtCdd
      timing event TECGdtCdd_Impl_MainFunction: start-on-event=CGdtCdd_Impl_MainFunction, period=0.016
      operation invoked event OIE_pp_CmpLibCmd_CGdtCdd_CGdtCdd_Impl_OnCommandTrigByImpl_OnCommand: start-on-event=CGdtCdd_Impl_OnCommand, operation=pp_CmpLibCmd_CGdtCdd.Impl_OnCommand
      port-api-options:
        enable-take-address=false, indirect-api=false, port=pp_CmpLibCmd_CGdtCdd
        enable-take-address=false, indirect-api=false, port=rp_GdtCddTimer_Start
        enable-take-address=false, indirect-api=false, port=rp_GdtCddTimer_getElapsedTime
        enable-take-address=false, indirect-api=false, port=rp_GdtTimerStop
      runnable CGdtCdd_Impl_MainFunction: can-be-invoked-concurrently=true
        sync call OA_rp_GdtCddTimer_Start_Timer_Start: operation=rp_GdtCddTimer_Start.Timer_Start, timeout=0.0
        sync call OA_rp_GdtCddTimer_getElapsedTime_Timer_GetElapsedTime: operation=rp_GdtCddTimer_getElapsedTime.Timer_GetElapsedTime, timeout=0.0
        sync call OA_rp_GdtTimerStop_Timer_Stop: operation=rp_GdtTimerStop.Timer_Stop, timeout=0.0
      runnable CGdtCdd_Impl_OnCommand: can-be-invoked-concurrently=true
  swc implementation IMPL_GdtCdd: programming-language=C, behavior=IB_GdtCdd
    code-descriptors:
      code CodeDescriptor
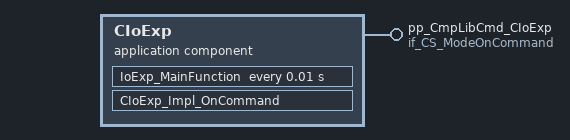
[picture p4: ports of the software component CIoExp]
  application sw component type CIoExp
    provide port pp_CmpLibCmd_CIoExp: server-com-spec{operation=Impl_OnCommand, queue-length=1}, provided-interface=if_CS_ModeOnCommand
    behavior IB_CIoExp: port-api-option{enable-take-address=false, indirect-api=false, port=pp_CmpLibCmd_CIoExp}
      operation invoked event OIE_pp_CmpLibCmd_CIoExp_CIoExp_Impl_OnCommandTrigByImpl_OnCommand: start-on-event=CIoExp_Impl_OnCommand, operation=pp_CmpLibCmd_CIoExp.Impl_OnCommand
      timing event TEIoExp_MainFunction: start-on-event=IoExp_MainFunction, period=0.01
      runnable CIoExp_Impl_OnCommand: can-be-invoked-concurrently=true
      runnable IoExp_MainFunction: can-be-invoked-concurrently=true
  swc implementation IMPL_CIoExp: programming-language=C, behavior=IB_CIoExp
    code-descriptors:
      code CodeDescriptor
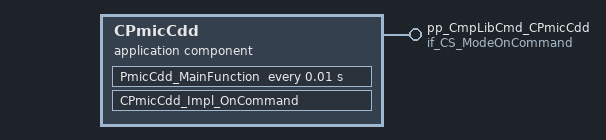
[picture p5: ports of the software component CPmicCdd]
  application sw component type CPmicCdd
    provide port pp_CmpLibCmd_CPmicCdd: server-com-spec{operation=Impl_OnCommand, queue-length=1}, provided-interface=if_CS_ModeOnCommand
    behavior IB_CPmicCdd: port-api-option{enable-take-address=false, indirect-api=false, port=pp_CmpLibCmd_CPmicCdd}
      operation invoked event OIE_pp_CmpLibCmd_CPmicCdd_CPmicCdd_Impl_OnCommandTrigByImpl_OnCommand: start-on-event=CPmicCdd_Impl_OnCommand, operation=pp_CmpLibCmd_CPmicCdd.Impl_OnCommand
      timing event TEPmicCdd_MainFunction: start-on-event=PmicCdd_MainFunction, period=0.01
      runnable CPmicCdd_Impl_OnCommand: can-be-invoked-concurrently=true
      runnable PmicCdd_MainFunction: can-be-invoked-concurrently=true
  swc implementation IMPL_CPmicCdd: programming-language=C, behavior=IB_CPmicCdd
    code-descriptors:
      code CodeDescriptor
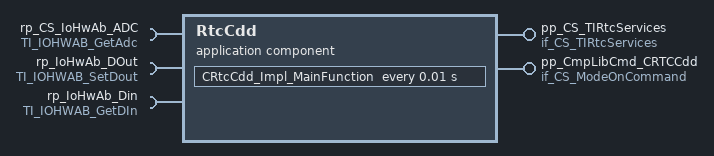
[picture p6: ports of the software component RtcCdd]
  application sw component type RtcCdd
    provide port pp_CS_TIRtcServices: provided-interface=if_CS_TIRtcServices
      provided-com-specs:
        operation=RtcCdd_ClearAlarm, queue-length=1
        operation=RtcCdd_GetTime, queue-length=1
        operation=RtcCdd_SetAlarm, queue-length=1
        operation=RtcCdd_SetTime, queue-length=1
    provide port pp_CmpLibCmd_CRTCCdd: server-com-spec{operation=Impl_OnCommand, queue-length=1}, provided-interface=if_CS_ModeOnCommand
    require port rp_CS_IoHwAb_ADC: required-interface=TI_IOHWAB_GetAdc
    require port rp_IoHwAb_DOut: required-interface=TI_IOHWAB_SetDout
    require port rp_IoHwAb_Din: required-interface=TI_IOHWAB_GetDIn
    behavior IB_RtcCdd
      timing event TECRtcCdd_Impl_MainFunction: start-on-event=CRtcCdd_Impl_MainFunction, period=0.01
      5 x operation invoked event:
        OIE_pp_CmpLibCmd_CRTCCdd_CRtcCdd_Impl_OnCommandTrigByImpl_OnCommand: start-on-event=CRtcCdd_Impl_OnCommand, operation=pp_CmpLibCmd_CRTCCdd.Impl_OnCommand
        OIE_pp_CS_TIRtcServices_RtcCdd_ClearAlarmTrigByRtcCdd_ClearAlarm: start-on-event=RtcCdd_ClearAlarm, operation=pp_CS_TIRtcServices.RtcCdd_ClearAlarm
        OIE_pp_CS_TIRtcServices_RtcCdd_GetTimeTrigByRtcCdd_GetTime: start-on-event=RtcCdd_GetTime, operation=pp_CS_TIRtcServices.RtcCdd_GetTime
        OIE_pp_CS_TIRtcServices_RtcCdd_SetAlarmTrigByRtcCdd_SetAlarm: start-on-event=RtcCdd_SetAlarm, operation=pp_CS_TIRtcServices.RtcCdd_SetAlarm
        OIE_pp_CS_TIRtcServices_RtcCdd_SetTimeTrigByRtcCdd_SetTime: start-on-event=RtcCdd_SetTime, operation=pp_CS_TIRtcServices.RtcCdd_SetTime
      port-api-options:
        enable-take-address=false, indirect-api=false, port=pp_CS_TIRtcServices
        enable-take-address=false, indirect-api=false, port=pp_CmpLibCmd_CRTCCdd
        enable-take-address=false, indirect-api=false, port=rp_CS_IoHwAb_ADC
        enable-take-address=false, indirect-api=false, port=rp_IoHwAb_DOut
        enable-take-address=false, indirect-api=false, port=rp_IoHwAb_Din
      6 x runnable, all with can-be-invoked-concurrently=true:
        CRtcCdd_Impl_MainFunction
          9 x sync call, all with timeout=0.0:
            OA_rp_CS_IoHwAb_ADC_GetAsyncRawAdc: operation=rp_CS_IoHwAb_ADC.GetAsyncRawAdc
            OA_rp_CS_IoHwAb_ADC_GetSyncRawAdc: operation=rp_CS_IoHwAb_ADC.GetSyncRawAdc
            OA_rp_CS_IoHwAb_ADC_GetProcessedAdc: operation=rp_CS_IoHwAb_ADC.GetProcessedAdc
            OA_rp_IoHwAb_DOut_SetOutputGroup: operation=rp_IoHwAb_DOut.SetOutputGroup
            OA_rp_IoHwAb_DOut_SetOutputPin: operation=rp_IoHwAb_DOut.SetOutputPin
            OA_rp_IoHwAb_Din_GetAsyncRawInput: operation=rp_IoHwAb_Din.GetAsyncRawInput
            OA_rp_IoHwAb_Din_GetProcessedInput: operation=rp_IoHwAb_Din.GetProcessedInput
            OA_rp_IoHwAb_Din_GetSyncRawInput: operation=rp_IoHwAb_Din.GetSyncRawInput
            OA_rp_IoHwAb_Din_GetInputGroup: operation=rp_IoHwAb_Din.GetInputGroup
        CRtcCdd_Impl_OnCommand
        RtcCdd_ClearAlarm
        RtcCdd_GetTime
        RtcCdd_SetAlarm
        RtcCdd_SetTime
  swc implementation IMPL_RtcCdd: programming-language=C, behavior=IB_RtcCdd
    code-descriptors:
      code CodeDescriptor
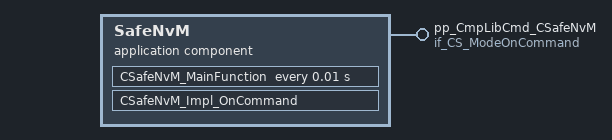
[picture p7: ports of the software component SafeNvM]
  application sw component type SafeNvM
    provide port pp_CmpLibCmd_CSafeNvM: server-com-spec{operation=Impl_OnCommand, queue-length=1}, provided-interface=if_CS_ModeOnCommand
    behavior IB_SafeNvM: port-api-option{enable-take-address=false, indirect-api=false, port=pp_CmpLibCmd_CSafeNvM}
      operation invoked event OIE_pp_CmpLibCmd_CSafeNvM_CSafeNvM_Impl_OnCommandTrigByImpl_OnCommand: start-on-event=CSafeNvM_Impl_OnCommand, operation=pp_CmpLibCmd_CSafeNvM.Impl_OnCommand
      timing event TECSafeNvM_MainFunction: start-on-event=CSafeNvM_MainFunction, period=0.01
      runnable CSafeNvM_Impl_OnCommand: can-be-invoked-concurrently=true
      runnable CSafeNvM_MainFunction: can-be-invoked-concurrently=true
  swc implementation IMPL_SafeNvM: programming-language=C, behavior=IB_SafeNvM
    code-descriptors:
      code CodeDescriptor
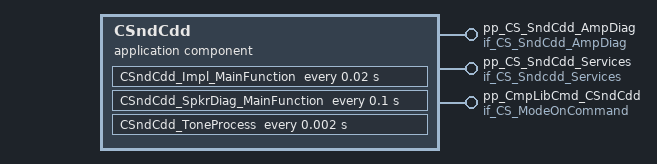
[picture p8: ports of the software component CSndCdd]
  application sw component type CSndCdd
    provide port pp_CS_SndCdd_AmpDiag: provided-com-specs=[{operation=GetSpeaker_status, queue-length=1}, {operation=SpkrAmp_Recovery, queue-length=1}], provided-interface=if_CS_SndCdd_AmpDiag
    provide port pp_CS_SndCdd_Services: provided-interface=if_CS_Sndcdd_Services
      provided-com-specs:
        operation=CheckChimeStatus, queue-length=1
        operation=CheckLastToneStatus, queue-length=1
        operation=ClearChimeResumeInfoBuffer, queue-length=1
        operation=GetChimeResumeInfoBuffer, queue-length=1
        operation=RequestCustomChime, queue-length=1
        operation=RequestToClear_SafetyChimeErrorStatus, queue-length=1
        operation=RequestToStart, queue-length=1
        operation=RequestToStop, queue-length=1
        operation=SetChimeResumeInfoBuffer, queue-length=1
        operation=SetDynamicDeadTime, queue-length=1
        operation=SetUserPersonalizationVolume, queue-length=1
        operation=StopCustomChime, queue-length=1
        operation=UpdateChannelVolume, queue-length=1
        operation=UpdateChimeInfoBuffer, queue-length=1
        operation=UpdateChimeVolume, queue-length=1
        operation=ischannelavailable, queue-length=1
    provide port pp_CmpLibCmd_CSndCdd: server-com-spec{operation=Impl_OnCommand, queue-length=1}, provided-interface=if_CS_ModeOnCommand
    behavior IB_CSndCdd
      5 x operation invoked event:
        OIE_pp_CS_SndCdd_Services_CSndCdd_CheckChimeStatusTrigByCheckChimeStatus: start-on-event=CSndCdd_CheckChimeStatus, operation=pp_CS_SndCdd_Services.CheckChimeStatus
        OIE_pp_CS_SndCdd_Services_CSndCdd_CheckLastToneStatusTrigByCheckLastToneStatus: start-on-event=CSndCdd_CheckLastToneStatus, operation=pp_CS_SndCdd_Services.CheckLastToneStatus
        OIE_pp_CS_SndCdd_Services_CSndCdd_ClearChimeResumeInfoBufferTrigByClearChimeResumeInfoBuffer: start-on-event=CSndCdd_ClearChimeResumeInfoBuffer, operation=pp_CS_SndCdd_Services.ClearChimeResumeInfoBuffer
        OIE_pp_CS_SndCdd_Services_CSndCdd_GetChimeResumeInfoBufferTrigByGetChimeResumeInfoBuffer: start-on-event=CSndCdd_GetChimeResumeInfoBuffer, operation=pp_CS_SndCdd_Services.GetChimeResumeInfoBuffer
        OIE_pp_CS_SndCdd_AmpDiag_CSndCdd_GetSpeaker_statusTrigByGetSpeaker_status: start-on-event=CSndCdd_GetSpeaker_status, operation=pp_CS_SndCdd_AmpDiag.GetSpeaker_status
      timing event TECSndCdd_Impl_MainFunction: start-on-event=CSndCdd_Impl_MainFunction, period=0.02
      9 x operation invoked event:
        OIE_pp_CmpLibCmd_CSndCdd_CSndCdd_Impl_OnCommandTrigByImpl_OnCommand: start-on-event=CSndCdd_Impl_OnCommand, operation=pp_CmpLibCmd_CSndCdd.Impl_OnCommand
        OIE_pp_CS_SndCdd_Services_CSndCdd_RequestCustomChimeTrigByRequestCustomChime: start-on-event=CSndCdd_RequestCustomChime, operation=pp_CS_SndCdd_Services.RequestCustomChime
        OIE_pp_CS_SndCdd_Services_CSndCdd_RequestToClear_SafetyChimeErrorStatusTrigByRequestToClear_SafetyChimeErrorStatus: start-on-event=CSndCdd_RequestToClear_SafetyChimeErrorStatus, operation=pp_CS_SndCdd_Services.RequestToClear_SafetyChimeErrorStatus
        OIE_pp_CS_SndCdd_Services_CSndCdd_RequestToStartTrigByRequestToStart: start-on-event=CSndCdd_RequestToStart, operation=pp_CS_SndCdd_Services.RequestToStart
        OIE_pp_CS_SndCdd_Services_CSndCdd_RequestToStopTrigByRequestToStop: start-on-event=CSndCdd_RequestToStop, operation=pp_CS_SndCdd_Services.RequestToStop
        OIE_pp_CS_SndCdd_Services_CSndCdd_SetChimeResumeInfoBufferTrigBySetChimeResumeInfoBuffer: start-on-event=CSndCdd_SetChimeResumeInfoBuffer, operation=pp_CS_SndCdd_Services.SetChimeResumeInfoBuffer
        OIE_pp_CS_SndCdd_Services_CSndCdd_SetDynamicDeadTimeTrigBySetDynamicDeadTime: start-on-event=CSndCdd_SetDynamicDeadTime, operation=pp_CS_SndCdd_Services.SetDynamicDeadTime
        OIE_pp_CS_SndCdd_Services_CSndCdd_SetUserPersonalizationVolumeTrigBySetUserPersonalizationVolume: start-on-event=CSndCdd_SetUserPersonalizationVolume, operation=pp_CS_SndCdd_Services.SetUserPersonalizationVolume
        OIE_pp_CS_SndCdd_AmpDiag_CSndCdd_SpkrAmp_RecoveryTrigBySpkrAmp_Recovery: start-on-event=CSndCdd_SpkrAmp_Recovery, operation=pp_CS_SndCdd_AmpDiag.SpkrAmp_Recovery
      timing event TECSndCdd_SpkrDiag_MainFunction: start-on-event=CSndCdd_SpkrDiag_MainFunction, period=0.1
      operation invoked event OIE_pp_CS_SndCdd_Services_CSndCdd_StopCustomChimeTrigByStopCustomChime: start-on-event=CSndCdd_StopCustomChime, operation=pp_CS_SndCdd_Services.StopCustomChime
      timing event TECSndCdd_ToneProcess: start-on-event=CSndCdd_ToneProcess, period=0.002
      4 x operation invoked event:
        OIE_pp_CS_SndCdd_Services_CSndCdd_UpdateChannelVolumeTrigByUpdateChannelVolume: start-on-event=CSndCdd_UpdateChannelVolume, operation=pp_CS_SndCdd_Services.UpdateChannelVolume
        OIE_pp_CS_SndCdd_Services_CSndCdd_UpdateChimeInfoBufferTrigByUpdateChimeInfoBuffer: start-on-event=CSndCdd_UpdateChimeInfoBuffer, operation=pp_CS_SndCdd_Services.UpdateChimeInfoBuffer
        OIE_pp_CS_SndCdd_Services_CSndCdd_UpdateChimeVolumeTrigByUpdateChimeVolume: start-on-event=CSndCdd_UpdateChimeVolume, operation=pp_CS_SndCdd_Services.UpdateChimeVolume
        OIE_pp_CS_SndCdd_Services_CSndCdd_ischannelavailableTrigByischannelavailable: start-on-event=CSndCdd_ischannelavailable, operation=pp_CS_SndCdd_Services.ischannelavailable
      port-api-options:
        enable-take-address=false, indirect-api=false, port=pp_CS_SndCdd_AmpDiag
        enable-take-address=false, indirect-api=false, port=pp_CS_SndCdd_Services
        enable-take-address=false, indirect-api=false, port=pp_CmpLibCmd_CSndCdd
      22 x runnable, all with can-be-invoked-concurrently=true:
        CSndCdd_CheckChimeStatus
        CSndCdd_CheckLastToneStatus
        CSndCdd_ClearChimeResumeInfoBuffer
        CSndCdd_GetChimeResumeInfoBuffer
        CSndCdd_GetSpeaker_status
        CSndCdd_Impl_MainFunction
        CSndCdd_Impl_OnCommand
        CSndCdd_RequestCustomChime
        CSndCdd_RequestToClear_SafetyChimeErrorStatus
        CSndCdd_RequestToStart
        CSndCdd_RequestToStop
        CSndCdd_SetChimeResumeInfoBuffer
        CSndCdd_SetDynamicDeadTime
        CSndCdd_SetUserPersonalizationVolume
        CSndCdd_SpkrAmp_Recovery
        CSndCdd_SpkrDiag_MainFunction
        CSndCdd_StopCustomChime
        CSndCdd_ToneProcess
        CSndCdd_UpdateChannelVolume
        CSndCdd_UpdateChimeInfoBuffer
        CSndCdd_UpdateChimeVolume
        CSndCdd_ischannelavailable
  swc implementation IMPL_CSndCdd: programming-language=C, behavior=IB_CSndCdd
    code-descriptors:
      code CodeDescriptor
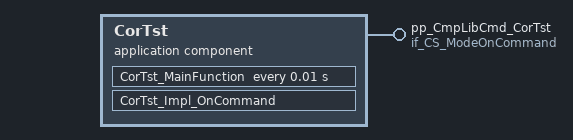
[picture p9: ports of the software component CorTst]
  application sw component type CorTst
    provide port pp_CmpLibCmd_CorTst: server-com-spec{operation=Impl_OnCommand, queue-length=1}, provided-interface=if_CS_ModeOnCommand
    behavior IB_CorTst: port-api-option{enable-take-address=false, indirect-api=false, port=pp_CmpLibCmd_CorTst}
      operation invoked event OIE_pp_CmpLibCmd_CorTst_CorTst_Impl_OnCommandTrigByImpl_OnCommand: start-on-event=CorTst_Impl_OnCommand, operation=pp_CmpLibCmd_CorTst.Impl_OnCommand
      timing event TECorTst_MainFunction: start-on-event=CorTst_MainFunction, period=0.01
      runnable CorTst_Impl_OnCommand: can-be-invoked-concurrently=true
      runnable CorTst_MainFunction: can-be-invoked-concurrently=true
  swc implementation IMPL_CorTst: programming-language=C, behavior=IB_CorTst
    code-descriptors:
      code CodeDescriptor
  application sw component type FlsTst
    provide port pp_CmpLibCmd_FlsTst: server-com-spec{operation=Impl_OnCommand, queue-length=1}, provided-interface=if_CS_ModeOnCommand
    behavior IB_FlsTst: port-api-option{enable-take-address=false, indirect-api=false, port=pp_CmpLibCmd_FlsTst}
      operation invoked event OIE_pp_CmpLibCmd_FlsTst_FlsTst_Impl_OnCommandTrigByImpl_OnCommand: start-on-event=FlsTst_Impl_OnCommand, operation=pp_CmpLibCmd_FlsTst.Impl_OnCommand
      timing event TEFlsTst_MainFunction: start-on-event=FlsTst_MainFunction, period=0.01
      runnable FlsTst_Impl_OnCommand: can-be-invoked-concurrently=true
      runnable FlsTst_MainFunction: can-be-invoked-concurrently=true
  swc implementation IMPL_FlsTst: programming-language=C, behavior=IB_FlsTst
    code-descriptors:
      code CodeDescriptor
  application sw component type CMeetCdd
    7 x provide port:
      pp_CS_DID_DiagAction: server-com-spec{operation=TI_DID_DiagAction/DID_DiagAction, queue-length=1}, provided-interface=TI_DID_DiagAction
      pp_CS_Meet_Mgrdiagcdd_Action: server-com-spec{operation=Meet_Mgrdiagcdd_Action, queue-length=1}, provided-interface=TI_Meet_Mgrdiagcdd_Action
      pp_CS_RID_DiagAction: server-com-spec{operation=TI_RID_DiagAction/RID_DiagAction, queue-length=1}, provided-interface=TI_RID_DiagAction
      pp_CS_Read_ManufModeStatus: server-com-spec{operation=Read_ManufModeStatus, queue-length=1}, provided-interface=TI_Read_ManufModeStatus
      pp_CS_Write_Mfg_Flag: server-com-spec{operation=Write_Mfg_Flag, queue-length=1}, provided-interface=TI_Write_Mfg_Flag
      pp_CmpLibCmd_MeetCdd: server-com-spec{operation=Impl_OnCommand, queue-length=1}, provided-interface=if_CS_ModeOnCommand
      pp_SR_SleepReq: nonqueued-sender-com-spec{data-element=SleepReqData, uses-end-to-end-protection=0, init-value=constant-reference=CMeetCddSleepReqDataValue0}, provided-interface=TI_SleepReq
    7 x require port:
      rpIoHwAb_ADC: required-interface=TI_IOHWAB_GetAdc
      rpIoHwAb_DOut: required-interface=TI_IOHWAB_SetDout
      rpIoHwAb_Din: required-interface=TI_IOHWAB_GetDIn
      rpIoHwAb_PWM: required-interface=TI_IOHWAB_PWM
      rp_CS_MemAbsGet: required-interface=if_CS_MemAbsGet
      rp_CS_MemAbsSet: required-interface=if_CS_MemAbsSet
      rp_SR_JobStatus: required-interface=if_SR_JobStatus
        required-com-specs:
          data-element=JobStatus_BsConst_Audio_Element, init-value=constant-reference=CMeetCddJobStatus_BsConst_Audio_ElementValue0
          data-element=JobStatus_BsConst_BsConst_Illumination_ReservedByte, init-value=constant-reference=CMeetCddJobStatus_BsConst_BsConst_Illumination_ReservedByteValue0
          data-element=JobStatus_BsConst_BsConst_Illumination_ReservedByte_SafeCopy1, init-value=constant-reference=CMeetCddJobStatus_BsConst_BsConst_Illumination_ReservedByte_SafeCopy1Value0
          data-element=JobStatus_BsConst_BsConst_Illumination_ReservedByte_SafeCopy2, init-value=constant-reference=CMeetCddJobStatus_BsConst_BsConst_Illumination_ReservedByte_SafeCopy2Value0
          data-element=JobStatus_BsConst_Communication_Element, init-value=constant-reference=CMeetCddJobStatus_BsConst_Communication_ElementValue0
          data-element=JobStatus_BsConst_Compensation_Line_Shift_b, init-value=constant-reference=CMeetCddJobStatus_BsConst_Compensation_Line_Shift_bValue0
          data-element=JobStatus_BsConst_Compensation_Line_Shift_b_SafeCopy1, init-value=constant-reference=CMeetCddJobStatus_BsConst_Compensation_Line_Shift_b_SafeCopy1Value0
          data-element=JobStatus_BsConst_Compensation_Line_Shift_b_SafeCopy2, init-value=constant-reference=CMeetCddJobStatus_BsConst_Compensation_Line_Shift_b_SafeCopy2Value0
          data-element=JobStatus_BsConst_Compensation_Line_Slope_m, init-value=constant-reference=CMeetCddJobStatus_BsConst_Compensation_Line_Slope_mValue0
          data-element=JobStatus_BsConst_Compensation_Line_Slope_m_SafeCopy1, init-value=constant-reference=CMeetCddJobStatus_BsConst_Compensation_Line_Slope_m_SafeCopy1Value0
          data-element=JobStatus_BsConst_Compensation_Line_Slope_m_SafeCopy2, init-value=constant-reference=CMeetCddJobStatus_BsConst_Compensation_Line_Slope_m_SafeCopy2Value0
          data-element=JobStatus_BsConst_Derating_Backlight_Disable, init-value=constant-reference=CMeetCddJobStatus_BsConst_Derating_Backlight_DisableValue0
          data-element=JobStatus_BsConst_Derating_Backlight_Disable_SafeCopy1, init-value=constant-reference=CMeetCddJobStatus_BsConst_Derating_Backlight_Disable_SafeCopy1Value0
          data-element=JobStatus_BsConst_Derating_Backlight_Disable_SafeCopy2, init-value=constant-reference=CMeetCddJobStatus_BsConst_Derating_Backlight_Disable_SafeCopy2Value0
          data-element=JobStatus_BsConst_Display_Illum_Max_Level, init-value=constant-reference=CMeetCddJobStatus_BsConst_Display_Illum_Max_LevelValue0
          data-element=JobStatus_BsConst_Display_Illum_Max_Level_SafeCopy1, init-value=constant-reference=CMeetCddJobStatus_BsConst_Display_Illum_Max_Level_SafeCopy1Value0
          data-element=JobStatus_BsConst_Display_Illum_Max_Level_SafeCopy2, init-value=constant-reference=CMeetCddJobStatus_BsConst_Display_Illum_Max_Level_SafeCopy2Value0
          data-element=JobStatus_BsConst_EngOffTimer_Element, init-value=constant-reference=CMeetCddJobStatus_BsConst_EngOffTimer_ElementValue0
          data-element=JobStatus_BsConst_FuelGauge_Element, init-value=constant-reference=CMeetCddJobStatus_BsConst_FuelGauge_ElementValue0
          data-element=JobStatus_BsConst_Lookup_Curve_HotSpot_Coef_X, init-value=constant-reference=CMeetCddJobStatus_BsConst_Lookup_Curve_HotSpot_Coef_XValue0
          data-element=JobStatus_BsConst_Lookup_Curve_HotSpot_Coef_X_SafeCopy1, init-value=constant-reference=CMeetCddJobStatus_BsConst_Lookup_Curve_HotSpot_Coef_X_SafeCopy1Value0
          data-element=JobStatus_BsConst_Lookup_Curve_HotSpot_Coef_X_SafeCopy2, init-value=constant-reference=CMeetCddJobStatus_BsConst_Lookup_Curve_HotSpot_Coef_X_SafeCopy2Value0
          data-element=JobStatus_BsConst_Lookup_Curve_HotSpot_Coef_Y, init-value=constant-reference=CMeetCddJobStatus_BsConst_Lookup_Curve_HotSpot_Coef_YValue0
          data-element=JobStatus_BsConst_Lookup_Curve_HotSpot_Coef_Y_SafeCopy1, init-value=constant-reference=CMeetCddJobStatus_BsConst_Lookup_Curve_HotSpot_Coef_Y_SafeCopy1Value0
          data-element=JobStatus_BsConst_Lookup_Curve_HotSpot_Coef_Y_SafeCopy2, init-value=constant-reference=CMeetCddJobStatus_BsConst_Lookup_Curve_HotSpot_Coef_Y_SafeCopy2Value0
          data-element=JobStatus_BsConst_OilGauge_Element, init-value=constant-reference=CMeetCddJobStatus_BsConst_OilGauge_ElementValue0
          data-element=JobStatus_BsConst_PCB_Temperature_Sensor_Conv, init-value=constant-reference=CMeetCddJobStatus_BsConst_PCB_Temperature_Sensor_ConvValue0
          data-element=JobStatus_BsConst_PCB_Temperature_Sensor_Conv_SafeCopy1, init-value=constant-reference=CMeetCddJobStatus_BsConst_PCB_Temperature_Sensor_Conv_SafeCopy1Value0
          data-element=JobStatus_BsConst_PCB_Temperature_Sensor_Conv_SafeCopy2, init-value=constant-reference=CMeetCddJobStatus_BsConst_PCB_Temperature_Sensor_Conv_SafeCopy2Value0
          data-element=JobStatus_BsConst_PWM_boost_bypass_duty, init-value=constant-reference=CMeetCddJobStatus_BsConst_PWM_boost_bypass_dutyValue0
          data-element=JobStatus_BsConst_PWM_boost_bypass_duty_SafeCopy1, init-value=constant-reference=CMeetCddJobStatus_BsConst_PWM_boost_bypass_duty_SafeCopy1Value0
          data-element=JobStatus_BsConst_PWM_boost_bypass_duty_SafeCopy2, init-value=constant-reference=CMeetCddJobStatus_BsConst_PWM_boost_bypass_duty_SafeCopy2Value0
          data-element=JobStatus_BsConst_PowerGauge_Element, init-value=constant-reference=CMeetCddJobStatus_BsConst_PowerGauge_ElementValue0
          data-element=JobStatus_BsConst_Power_Element, init-value=constant-reference=CMeetCddJobStatus_BsConst_Power_ElementValue0
          data-element=JobStatus_BsConst_RealTimeClock_Element, init-value=constant-reference=CMeetCddJobStatus_BsConst_RealTimeClock_ElementValue0
          data-element=JobStatus_BsConst_ServiceReminder_Element, init-value=constant-reference=CMeetCddJobStatus_BsConst_ServiceReminder_ElementValue0
          data-element=JobStatus_BsConst_SpeedoGauge_Element, init-value=constant-reference=CMeetCddJobStatus_BsConst_SpeedoGauge_ElementValue0
          data-element=JobStatus_BsConst_TachoGauge_Element, init-value=constant-reference=CMeetCddJobStatus_BsConst_TachoGauge_ElementValue0
          data-element=JobStatus_BsConst_TempGauge_Element, init-value=constant-reference=CMeetCddJobStatus_BsConst_TempGauge_ElementValue0
          data-element=JobStatus_BsConst_Temp_Threshold_Hysteresis_Derating, init-value=constant-reference=CMeetCddJobStatus_BsConst_Temp_Threshold_Hysteresis_DeratingValue0
          data-element=JobStatus_BsConst_Temp_Threshold_Hysteresis_Derating_SafeCopy1, init-value=constant-reference=CMeetCddJobStatus_BsConst_Temp_Threshold_Hysteresis_Derating_SafeCopy1Value0
          data-element=JobStatus_BsConst_Temp_Threshold_Hysteresis_Derating_SafeCopy2, init-value=constant-reference=CMeetCddJobStatus_BsConst_Temp_Threshold_Hysteresis_Derating_SafeCopy2Value0
          data-element=JobStatus_BsConst_Temperature_Sensor_Conv, init-value=constant-reference=CMeetCddJobStatus_BsConst_Temperature_Sensor_ConvValue0
          data-element=JobStatus_BsConst_Temperature_Sensor_Conv_SafeCopy1, init-value=constant-reference=CMeetCddJobStatus_BsConst_Temperature_Sensor_Conv_SafeCopy1Value0
          data-element=JobStatus_BsConst_Temperature_Sensor_Conv_SafeCopy2, init-value=constant-reference=CMeetCddJobStatus_BsConst_Temperature_Sensor_Conv_SafeCopy2Value0
          data-element=JobStatus_BsConst_TripComputer_Element, init-value=constant-reference=CMeetCddJobStatus_BsConst_TripComputer_ElementValue0
          data-element=JobStatus_BsConst_Warning_Element, init-value=constant-reference=CMeetCddJobStatus_BsConst_Warning_ElementValue0
          data-element=JobStatus_BsCys_Certicificate_Element, init-value=constant-reference=CMeetCddJobStatus_BsCys_Certicificate_ElementValue0
          data-element=JobStatus_BsDiag_Dtc_Element, init-value=constant-reference=CMeetCddJobStatus_BsDiag_Dtc_ElementValue0
          data-element=JobStatus_BsDiag_ErrorRecord_Element, init-value=constant-reference=CMeetCddJobStatus_BsDiag_ErrorRecord_ElementValue0
          data-element=JobStatus_BsReten_Audio_Element, init-value=constant-reference=CMeetCddJobStatus_BsReten_Audio_ElementValue0
          data-element=JobStatus_BsReten_Communication_Element, init-value=constant-reference=CMeetCddJobStatus_BsReten_Communication_ElementValue0
          data-element=JobStatus_BsReten_Display_Element, init-value=constant-reference=CMeetCddJobStatus_BsReten_Display_ElementValue0
          data-element=JobStatus_BsReten_Gauges_Element, init-value=constant-reference=CMeetCddJobStatus_BsReten_Gauges_ElementValue0
          data-element=JobStatus_BsReten_Illumination_Element, init-value=constant-reference=CMeetCddJobStatus_BsReten_Illumination_ElementValue0
          data-element=JobStatus_BsReten_Odometer_Element, init-value=constant-reference=CMeetCddJobStatus_BsReten_Odometer_ElementValue0
          data-element=JobStatus_BsReten_Personalization_Element, init-value=constant-reference=CMeetCddJobStatus_BsReten_Personalization_ElementValue0
          data-element=JobStatus_BsReten_Power_Element, init-value=constant-reference=CMeetCddJobStatus_BsReten_Power_ElementValue0
          data-element=JobStatus_BsReten_RealTimeClock_Element, init-value=constant-reference=CMeetCddJobStatus_BsReten_RealTimeClock_ElementValue0
          data-element=JobStatus_BsReten_Tripcomputer_Element, init-value=constant-reference=CMeetCddJobStatus_BsReten_Tripcomputer_ElementValue0
          data-element=JobStatus_BsReten_VisDlt_Element, init-value=constant-reference=CMeetCddJobStatus_BsReten_VisDlt_ElementValue0
          data-element=JobStatus_BsReten_Warning_Element, init-value=constant-reference=CMeetCddJobStatus_BsReten_Warning_ElementValue0
          data-element=JobStatus_BsRt_CusDlt_Element, init-value=constant-reference=CMeetCddJobStatus_BsRt_CusDlt_ElementValue0
          data-element=JobStatus_BsRt_FuelGauge_Element, init-value=constant-reference=CMeetCddJobStatus_BsRt_FuelGauge_ElementValue0
          data-element=JobStatus_BsRt_Illumination_Element, init-value=constant-reference=CMeetCddJobStatus_BsRt_Illumination_ElementValue0
          data-element=JobStatus_BsRt_Odometer_Element, init-value=constant-reference=CMeetCddJobStatus_BsRt_Odometer_ElementValue0
          data-element=JobStatus_BsRt_OilGauge_Element, init-value=constant-reference=CMeetCddJobStatus_BsRt_OilGauge_ElementValue0
          data-element=JobStatus_BsRt_Personalization_Element, init-value=constant-reference=CMeetCddJobStatus_BsRt_Personalization_ElementValue0
          data-element=JobStatus_BsRt_PowerGauge_Element, init-value=constant-reference=CMeetCddJobStatus_BsRt_PowerGauge_ElementValue0
          data-element=JobStatus_BsRt_RealTimeClock_Element, init-value=constant-reference=CMeetCddJobStatus_BsRt_RealTimeClock_ElementValue0
          data-element=JobStatus_BsRt_SpeedoGauge_Element, init-value=constant-reference=CMeetCddJobStatus_BsRt_SpeedoGauge_ElementValue0
          data-element=JobStatus_BsRt_TachoGauge_Element, init-value=constant-reference=CMeetCddJobStatus_BsRt_TachoGauge_ElementValue0
          data-element=JobStatus_BsRt_TempGauge_Element, init-value=constant-reference=CMeetCddJobStatus_BsRt_TempGauge_ElementValue0
          data-element=JobStatus_BsRt_TripComputer_Element, init-value=constant-reference=CMeetCddJobStatus_BsRt_TripComputer_ElementValue0
          data-element=JobStatus_BsRt_Warning_Element, init-value=constant-reference=CMeetCddJobStatus_BsRt_Warning_ElementValue0
          data-element=JobStatus_BsShare_AssemblyManufacturingDate, init-value=constant-reference=CMeetCddJobStatus_BsShare_AssemblyManufacturingDateValue0
          data-element=JobStatus_BsShare_AssemblyPlantNumber, init-value=constant-reference=CMeetCddJobStatus_BsShare_AssemblyPlantNumberValue0
          data-element=JobStatus_BsShare_EcuPartNumber_Element, init-value=constant-reference=CMeetCddJobStatus_BsShare_EcuPartNumber_ElementValue0
          data-element=JobStatus_BsShare_HWModification, init-value=constant-reference=CMeetCddJobStatus_BsShare_HWModificationValue0
          data-element=JobStatus_BsShare_PCBSerialNumber, init-value=constant-reference=CMeetCddJobStatus_BsShare_PCBSerialNumberValue0
          data-element=JobStatus_BsShare_ProductSerialNumber, init-value=constant-reference=CMeetCddJobStatus_BsShare_ProductSerialNumberValue0
          data-element=JobStatus_BsShare_SMTManufacturingDate, init-value=constant-reference=CMeetCddJobStatus_BsShare_SMTManufacturingDateValue0
          data-element=JobStatus_BsShare_SMTPlantNumber, init-value=constant-reference=CMeetCddJobStatus_BsShare_SMTPlantNumberValue0
          data-element=JobStatus_BsShare_SwUpdFotaFinPrint_Element, init-value=constant-reference=CMeetCddJobStatus_BsShare_SwUpdFotaFinPrint_ElementValue0
          data-element=JobStatus_BsShare_SwUpdFotaMode_Element, init-value=constant-reference=CMeetCddJobStatus_BsShare_SwUpdFotaMode_ElementValue0
          data-element=JobStatus_BsShare_SwUpdFotaStatus_Element, init-value=constant-reference=CMeetCddJobStatus_BsShare_SwUpdFotaStatus_ElementValue0
          data-element=JobStatus_BsShare_SwUpdFotadecrypt_Element, init-value=constant-reference=CMeetCddJobStatus_BsShare_SwUpdFotadecrypt_ElementValue0
          data-element=JobStatus_BsShare_SwUpdReflash_Element, init-value=constant-reference=CMeetCddJobStatus_BsShare_SwUpdReflash_ElementValue0
          data-element=JobStatus_BsShare_VehicleConfig_Element, init-value=constant-reference=CMeetCddJobStatus_BsShare_VehicleConfig_ElementValue0
          data-element=JobStatus_BsShare_VisMeet_EOLEntry_Element, init-value=constant-reference=CMeetCddJobStatus_BsShare_VisMeet_EOLEntry_ElementValue0
          data-element=JobStatus_BsShare_VisMeet_Element, init-value=constant-reference=CMeetCddJobStatus_BsShare_VisMeet_ElementValue0
          data-element=JobStatus_BsShare_VisteonPCBPartNumber, init-value=constant-reference=CMeetCddJobStatus_BsShare_VisteonPCBPartNumberValue0
          data-element=JobStatus_BsShare_VisteonPartNumber, init-value=constant-reference=CMeetCddJobStatus_BsShare_VisteonPartNumberValue0
          data-element=JobStatus_RefCys_Certicificate1_Element, init-value=constant-reference=CMeetCddJobStatus_RefCys_Certicificate1_ElementValue0
          data-element=JobStatus_RefCys_Certicificate_Element, init-value=constant-reference=CMeetCddJobStatus_RefCys_Certicificate_ElementValue0
    behavior IB_CMeetCdd
      operation invoked event OIE_pp_CS_DID_DiagAction_CMeetCdd_DID_DiagActionTrigByDID_DiagAction: start-on-event=CMeetCdd_DID_DiagAction, operation=pp_CS_DID_DiagAction.DID_DiagAction
      timing event TECMeetCdd_Impl_MainFunction: start-on-event=CMeetCdd_Impl_MainFunction, period=0.01
      5 x operation invoked event:
        OIE_pp_CmpLibCmd_MeetCdd_CMeetCdd_Impl_OnCommandTrigByImpl_OnCommand: start-on-event=CMeetCdd_Impl_OnCommand, operation=pp_CmpLibCmd_MeetCdd.Impl_OnCommand
        OIE_pp_CS_Meet_Mgrdiagcdd_Action_CMeetCdd_Meet_Mgrdiagcdd_ActionTrigByMeet_Mgrdiagcdd_Action: start-on-event=CMeetCdd_Meet_Mgrdiagcdd_Action, operation=pp_CS_Meet_Mgrdiagcdd_Action.Meet_Mgrdiagcdd_Action
        OIE_pp_CS_RID_DiagAction_CMeetCdd_RID_DiagActionTrigByRID_DiagAction: start-on-event=CMeetCdd_RID_DiagAction, operation=pp_CS_RID_DiagAction.RID_DiagAction
        OIE_pp_CS_Read_ManufModeStatus_CMeetCdd_Read_ManufModeStatusTrigByRead_ManufModeStatus: start-on-event=CMeetCdd_Read_ManufModeStatus, operation=pp_CS_Read_ManufModeStatus.Read_ManufModeStatus
        OIE_pp_CS_Write_Mfg_Flag_CMeetCdd_Write_Mfg_FlagTrigByWrite_Mfg_Flag: start-on-event=CMeetCdd_Write_Mfg_Flag, operation=pp_CS_Write_Mfg_Flag.Write_Mfg_Flag
      port-api-options:
        enable-take-address=false, indirect-api=false, port=pp_CS_DID_DiagAction
        enable-take-address=false, indirect-api=false, port=pp_CS_Meet_Mgrdiagcdd_Action
        enable-take-address=false, indirect-api=false, port=pp_CS_RID_DiagAction
        enable-take-address=false, indirect-api=false, port=pp_CS_Read_ManufModeStatus
        enable-take-address=false, indirect-api=false, port=pp_CS_Write_Mfg_Flag
        enable-take-address=false, indirect-api=false, port=pp_CmpLibCmd_MeetCdd
        enable-take-address=false, indirect-api=false, port=pp_SR_SleepReq
        enable-take-address=false, indirect-api=false, port=CMeetCdd/rpIoHwAb_ADC
        enable-take-address=false, indirect-api=false, port=CMeetCdd/rpIoHwAb_DOut
        enable-take-address=false, indirect-api=false, port=CMeetCdd/rpIoHwAb_Din
        enable-take-address=false, indirect-api=false, port=CMeetCdd/rpIoHwAb_PWM
        enable-take-address=false, indirect-api=false, port=CMeetCdd/rp_CS_MemAbsGet
        enable-take-address=false, indirect-api=false, port=CMeetCdd/rp_CS_MemAbsSet
        enable-take-address=false, indirect-api=false, port=CMeetCdd/rp_SR_JobStatus
      7 x runnable, all with can-be-invoked-concurrently=true:
        CMeetCdd_DID_DiagAction
        CMeetCdd_Impl_MainFunction
          data-receive-point-by-arguments:
            95 x access:
              DRA_rp_SR_JobStatus_JobStatus_BsConst_Audio_Element: accessed-variable=rp_SR_JobStatus.JobStatus_BsConst_Audio_Element
              DRA_rp_SR_JobStatus_JobStatus_BsConst_BsConst_Illumination_ReservedByte: accessed-variable=rp_SR_JobStatus.JobStatus_BsConst_BsConst_Illumination_ReservedByte
              DRA_rp_SR_JobStatus_JobStatus_BsConst_BsConst_Illumination_ReservedByte_SafeCopy1: accessed-variable=rp_SR_JobStatus.JobStatus_BsConst_BsConst_Illumination_ReservedByte_SafeCopy1
              DRA_rp_SR_JobStatus_JobStatus_BsConst_BsConst_Illumination_ReservedByte_SafeCopy2: accessed-variable=rp_SR_JobStatus.JobStatus_BsConst_BsConst_Illumination_ReservedByte_SafeCopy2
              DRA_rp_SR_JobStatus_JobStatus_BsConst_Communication_Element: accessed-variable=rp_SR_JobStatus.JobStatus_BsConst_Communication_Element
              DRA_rp_SR_JobStatus_JobStatus_BsConst_Compensation_Line_Shift_b: accessed-variable=rp_SR_JobStatus.JobStatus_BsConst_Compensation_Line_Shift_b
              DRA_rp_SR_JobStatus_JobStatus_BsConst_Compensation_Line_Shift_b_SafeCopy1: accessed-variable=rp_SR_JobStatus.JobStatus_BsConst_Compensation_Line_Shift_b_SafeCopy1
              DRA_rp_SR_JobStatus_JobStatus_BsConst_Compensation_Line_Shift_b_SafeCopy2: accessed-variable=rp_SR_JobStatus.JobStatus_BsConst_Compensation_Line_Shift_b_SafeCopy2
              DRA_rp_SR_JobStatus_JobStatus_BsConst_Compensation_Line_Slope_m: accessed-variable=rp_SR_JobStatus.JobStatus_BsConst_Compensation_Line_Slope_m
              DRA_rp_SR_JobStatus_JobStatus_BsConst_Compensation_Line_Slope_m_SafeCopy1: accessed-variable=rp_SR_JobStatus.JobStatus_BsConst_Compensation_Line_Slope_m_SafeCopy1
              DRA_rp_SR_JobStatus_JobStatus_BsConst_Compensation_Line_Slope_m_SafeCopy2: accessed-variable=rp_SR_JobStatus.JobStatus_BsConst_Compensation_Line_Slope_m_SafeCopy2
              DRA_rp_SR_JobStatus_JobStatus_BsConst_Derating_Backlight_Disable: accessed-variable=rp_SR_JobStatus.JobStatus_BsConst_Derating_Backlight_Disable
              DRA_rp_SR_JobStatus_JobStatus_BsConst_Derating_Backlight_Disable_SafeCopy1: accessed-variable=rp_SR_JobStatus.JobStatus_BsConst_Derating_Backlight_Disable_SafeCopy1
              DRA_rp_SR_JobStatus_JobStatus_BsConst_Derating_Backlight_Disable_SafeCopy2: accessed-variable=rp_SR_JobStatus.JobStatus_BsConst_Derating_Backlight_Disable_SafeCopy2
              DRA_rp_SR_JobStatus_JobStatus_BsConst_Display_Illum_Max_Level: accessed-variable=rp_SR_JobStatus.JobStatus_BsConst_Display_Illum_Max_Level
              DRA_rp_SR_JobStatus_JobStatus_BsConst_Display_Illum_Max_Level_SafeCopy1: accessed-variable=rp_SR_JobStatus.JobStatus_BsConst_Display_Illum_Max_Level_SafeCopy1
              DRA_rp_SR_JobStatus_JobStatus_BsConst_Display_Illum_Max_Level_SafeCopy2: accessed-variable=rp_SR_JobStatus.JobStatus_BsConst_Display_Illum_Max_Level_SafeCopy2
              DRA_rp_SR_JobStatus_JobStatus_BsConst_EngOffTimer_Element: accessed-variable=rp_SR_JobStatus.JobStatus_BsConst_EngOffTimer_Element
              DRA_rp_SR_JobStatus_JobStatus_BsConst_FuelGauge_Element: accessed-variable=rp_SR_JobStatus.JobStatus_BsConst_FuelGauge_Element
              DRA_rp_SR_JobStatus_JobStatus_BsConst_Lookup_Curve_HotSpot_Coef_X: accessed-variable=rp_SR_JobStatus.JobStatus_BsConst_Lookup_Curve_HotSpot_Coef_X
              DRA_rp_SR_JobStatus_JobStatus_BsConst_Lookup_Curve_HotSpot_Coef_X_SafeCopy1: accessed-variable=rp_SR_JobStatus.JobStatus_BsConst_Lookup_Curve_HotSpot_Coef_X_SafeCopy1
              DRA_rp_SR_JobStatus_JobStatus_BsConst_Lookup_Curve_HotSpot_Coef_X_SafeCopy2: accessed-variable=rp_SR_JobStatus.JobStatus_BsConst_Lookup_Curve_HotSpot_Coef_X_SafeCopy2
              DRA_rp_SR_JobStatus_JobStatus_BsConst_Lookup_Curve_HotSpot_Coef_Y: accessed-variable=rp_SR_JobStatus.JobStatus_BsConst_Lookup_Curve_HotSpot_Coef_Y
              DRA_rp_SR_JobStatus_JobStatus_BsConst_Lookup_Curve_HotSpot_Coef_Y_SafeCopy1: accessed-variable=rp_SR_JobStatus.JobStatus_BsConst_Lookup_Curve_HotSpot_Coef_Y_SafeCopy1
              DRA_rp_SR_JobStatus_JobStatus_BsConst_Lookup_Curve_HotSpot_Coef_Y_SafeCopy2: accessed-variable=rp_SR_JobStatus.JobStatus_BsConst_Lookup_Curve_HotSpot_Coef_Y_SafeCopy2
              DRA_rp_SR_JobStatus_JobStatus_BsConst_OilGauge_Element: accessed-variable=rp_SR_JobStatus.JobStatus_BsConst_OilGauge_Element
              DRA_rp_SR_JobStatus_JobStatus_BsConst_PCB_Temperature_Sensor_Conv: accessed-variable=rp_SR_JobStatus.JobStatus_BsConst_PCB_Temperature_Sensor_Conv
              DRA_rp_SR_JobStatus_JobStatus_BsConst_PCB_Temperature_Sensor_Conv_SafeCopy1: accessed-variable=rp_SR_JobStatus.JobStatus_BsConst_PCB_Temperature_Sensor_Conv_SafeCopy1
              DRA_rp_SR_JobStatus_JobStatus_BsConst_PCB_Temperature_Sensor_Conv_SafeCopy2: accessed-variable=rp_SR_JobStatus.JobStatus_BsConst_PCB_Temperature_Sensor_Conv_SafeCopy2
              DRA_rp_SR_JobStatus_JobStatus_BsConst_PWM_boost_bypass_duty: accessed-variable=rp_SR_JobStatus.JobStatus_BsConst_PWM_boost_bypass_duty
              DRA_rp_SR_JobStatus_JobStatus_BsConst_PWM_boost_bypass_duty_SafeCopy1: accessed-variable=rp_SR_JobStatus.JobStatus_BsConst_PWM_boost_bypass_duty_SafeCopy1
              DRA_rp_SR_JobStatus_JobStatus_BsConst_PWM_boost_bypass_duty_SafeCopy2: accessed-variable=rp_SR_JobStatus.JobStatus_BsConst_PWM_boost_bypass_duty_SafeCopy2
              DRA_rp_SR_JobStatus_JobStatus_BsConst_PowerGauge_Element: accessed-variable=rp_SR_JobStatus.JobStatus_BsConst_PowerGauge_Element
              DRA_rp_SR_JobStatus_JobStatus_BsConst_Power_Element: accessed-variable=rp_SR_JobStatus.JobStatus_BsConst_Power_Element
              DRA_rp_SR_JobStatus_JobStatus_BsConst_RealTimeClock_Element: accessed-variable=rp_SR_JobStatus.JobStatus_BsConst_RealTimeClock_Element
              DRA_rp_SR_JobStatus_JobStatus_BsConst_ServiceReminder_Element: accessed-variable=rp_SR_JobStatus.JobStatus_BsConst_ServiceReminder_Element
              DRA_rp_SR_JobStatus_JobStatus_BsConst_SpeedoGauge_Element: accessed-variable=rp_SR_JobStatus.JobStatus_BsConst_SpeedoGauge_Element
              DRA_rp_SR_JobStatus_JobStatus_BsConst_TachoGauge_Element: accessed-variable=rp_SR_JobStatus.JobStatus_BsConst_TachoGauge_Element
              DRA_rp_SR_JobStatus_JobStatus_BsConst_TempGauge_Element: accessed-variable=rp_SR_JobStatus.JobStatus_BsConst_TempGauge_Element
              DRA_rp_SR_JobStatus_JobStatus_BsConst_Temp_Threshold_Hysteresis_Derating: accessed-variable=rp_SR_JobStatus.JobStatus_BsConst_Temp_Threshold_Hysteresis_Derating
              DRA_rp_SR_JobStatus_JobStatus_BsConst_Temp_Threshold_Hysteresis_Derating_SafeCopy1: accessed-variable=rp_SR_JobStatus.JobStatus_BsConst_Temp_Threshold_Hysteresis_Derating_SafeCopy1
              DRA_rp_SR_JobStatus_JobStatus_BsConst_Temp_Threshold_Hysteresis_Derating_SafeCopy2: accessed-variable=rp_SR_JobStatus.JobStatus_BsConst_Temp_Threshold_Hysteresis_Derating_SafeCopy2
              DRA_rp_SR_JobStatus_JobStatus_BsConst_Temperature_Sensor_Conv: accessed-variable=rp_SR_JobStatus.JobStatus_BsConst_Temperature_Sensor_Conv
              DRA_rp_SR_JobStatus_JobStatus_BsConst_Temperature_Sensor_Conv_SafeCopy1: accessed-variable=rp_SR_JobStatus.JobStatus_BsConst_Temperature_Sensor_Conv_SafeCopy1
              DRA_rp_SR_JobStatus_JobStatus_BsConst_Temperature_Sensor_Conv_SafeCopy2: accessed-variable=rp_SR_JobStatus.JobStatus_BsConst_Temperature_Sensor_Conv_SafeCopy2
              DRA_rp_SR_JobStatus_JobStatus_BsConst_TripComputer_Element: accessed-variable=rp_SR_JobStatus.JobStatus_BsConst_TripComputer_Element
              DRA_rp_SR_JobStatus_JobStatus_BsConst_Warning_Element: accessed-variable=rp_SR_JobStatus.JobStatus_BsConst_Warning_Element
              DRA_rp_SR_JobStatus_JobStatus_BsCys_Certicificate_Element: accessed-variable=rp_SR_JobStatus.JobStatus_BsCys_Certicificate_Element
              DRA_rp_SR_JobStatus_JobStatus_BsDiag_Dtc_Element: accessed-variable=rp_SR_JobStatus.JobStatus_BsDiag_Dtc_Element
              DRA_rp_SR_JobStatus_JobStatus_BsDiag_ErrorRecord_Element: accessed-variable=rp_SR_JobStatus.JobStatus_BsDiag_ErrorRecord_Element
              DRA_rp_SR_JobStatus_JobStatus_BsReten_Audio_Element: accessed-variable=rp_SR_JobStatus.JobStatus_BsReten_Audio_Element
              DRA_rp_SR_JobStatus_JobStatus_BsReten_Communication_Element: accessed-variable=rp_SR_JobStatus.JobStatus_BsReten_Communication_Element
              DRA_rp_SR_JobStatus_JobStatus_BsReten_Display_Element: accessed-variable=rp_SR_JobStatus.JobStatus_BsReten_Display_Element
              DRA_rp_SR_JobStatus_JobStatus_BsReten_Gauges_Element: accessed-variable=rp_SR_JobStatus.JobStatus_BsReten_Gauges_Element
              DRA_rp_SR_JobStatus_JobStatus_BsReten_Illumination_Element: accessed-variable=rp_SR_JobStatus.JobStatus_BsReten_Illumination_Element
              DRA_rp_SR_JobStatus_JobStatus_BsReten_Odometer_Element: accessed-variable=rp_SR_JobStatus.JobStatus_BsReten_Odometer_Element
              DRA_rp_SR_JobStatus_JobStatus_BsReten_Personalization_Element: accessed-variable=rp_SR_JobStatus.JobStatus_BsReten_Personalization_Element
              DRA_rp_SR_JobStatus_JobStatus_BsReten_Power_Element: accessed-variable=rp_SR_JobStatus.JobStatus_BsReten_Power_Element
              DRA_rp_SR_JobStatus_JobStatus_BsReten_RealTimeClock_Element: accessed-variable=rp_SR_JobStatus.JobStatus_BsReten_RealTimeClock_Element
              DRA_rp_SR_JobStatus_JobStatus_BsReten_Tripcomputer_Element: accessed-variable=rp_SR_JobStatus.JobStatus_BsReten_Tripcomputer_Element
              DRA_rp_SR_JobStatus_JobStatus_BsReten_VisDlt_Element: accessed-variable=rp_SR_JobStatus.JobStatus_BsReten_VisDlt_Element
              DRA_rp_SR_JobStatus_JobStatus_BsReten_Warning_Element: accessed-variable=rp_SR_JobStatus.JobStatus_BsReten_Warning_Element
              DRA_rp_SR_JobStatus_JobStatus_BsRt_CusDlt_Element: accessed-variable=rp_SR_JobStatus.JobStatus_BsRt_CusDlt_Element
              DRA_rp_SR_JobStatus_JobStatus_BsRt_FuelGauge_Element: accessed-variable=rp_SR_JobStatus.JobStatus_BsRt_FuelGauge_Element
              DRA_rp_SR_JobStatus_JobStatus_BsRt_Illumination_Element: accessed-variable=rp_SR_JobStatus.JobStatus_BsRt_Illumination_Element
              DRA_rp_SR_JobStatus_JobStatus_BsRt_Odometer_Element: accessed-variable=rp_SR_JobStatus.JobStatus_BsRt_Odometer_Element
              DRA_rp_SR_JobStatus_JobStatus_BsRt_OilGauge_Element: accessed-variable=rp_SR_JobStatus.JobStatus_BsRt_OilGauge_Element
              DRA_rp_SR_JobStatus_JobStatus_BsRt_Personalization_Element: accessed-variable=rp_SR_JobStatus.JobStatus_BsRt_Personalization_Element
              DRA_rp_SR_JobStatus_JobStatus_BsRt_PowerGauge_Element: accessed-variable=rp_SR_JobStatus.JobStatus_BsRt_PowerGauge_Element
              DRA_rp_SR_JobStatus_JobStatus_BsRt_RealTimeClock_Element: accessed-variable=rp_SR_JobStatus.JobStatus_BsRt_RealTimeClock_Element
              DRA_rp_SR_JobStatus_JobStatus_BsRt_SpeedoGauge_Element: accessed-variable=rp_SR_JobStatus.JobStatus_BsRt_SpeedoGauge_Element
              DRA_rp_SR_JobStatus_JobStatus_BsRt_TachoGauge_Element: accessed-variable=rp_SR_JobStatus.JobStatus_BsRt_TachoGauge_Element
              DRA_rp_SR_JobStatus_JobStatus_BsRt_TempGauge_Element: accessed-variable=rp_SR_JobStatus.JobStatus_BsRt_TempGauge_Element
              DRA_rp_SR_JobStatus_JobStatus_BsRt_TripComputer_Element: accessed-variable=rp_SR_JobStatus.JobStatus_BsRt_TripComputer_Element
              DRA_rp_SR_JobStatus_JobStatus_BsRt_Warning_Element: accessed-variable=rp_SR_JobStatus.JobStatus_BsRt_Warning_Element
              DRA_rp_SR_JobStatus_JobStatus_BsShare_AssemblyManufacturingDate: accessed-variable=rp_SR_JobStatus.JobStatus_BsShare_AssemblyManufacturingDate
              DRA_rp_SR_JobStatus_JobStatus_BsShare_AssemblyPlantNumber: accessed-variable=rp_SR_JobStatus.JobStatus_BsShare_AssemblyPlantNumber
              DRA_rp_SR_JobStatus_JobStatus_BsShare_EcuPartNumber_Element: accessed-variable=rp_SR_JobStatus.JobStatus_BsShare_EcuPartNumber_Element
              DRA_rp_SR_JobStatus_JobStatus_BsShare_HWModification: accessed-variable=rp_SR_JobStatus.JobStatus_BsShare_HWModification
              DRA_rp_SR_JobStatus_JobStatus_BsShare_PCBSerialNumber: accessed-variable=rp_SR_JobStatus.JobStatus_BsShare_PCBSerialNumber
              DRA_rp_SR_JobStatus_JobStatus_BsShare_ProductSerialNumber: accessed-variable=rp_SR_JobStatus.JobStatus_BsShare_ProductSerialNumber
              DRA_rp_SR_JobStatus_JobStatus_BsShare_SMTManufacturingDate: accessed-variable=rp_SR_JobStatus.JobStatus_BsShare_SMTManufacturingDate
              DRA_rp_SR_JobStatus_JobStatus_BsShare_SMTPlantNumber: accessed-variable=rp_SR_JobStatus.JobStatus_BsShare_SMTPlantNumber
              DRA_rp_SR_JobStatus_JobStatus_BsShare_SwUpdFotaFinPrint_Element: accessed-variable=rp_SR_JobStatus.JobStatus_BsShare_SwUpdFotaFinPrint_Element
              DRA_rp_SR_JobStatus_JobStatus_BsShare_SwUpdFotaMode_Element: accessed-variable=rp_SR_JobStatus.JobStatus_BsShare_SwUpdFotaMode_Element
              DRA_rp_SR_JobStatus_JobStatus_BsShare_SwUpdFotaStatus_Element: accessed-variable=rp_SR_JobStatus.JobStatus_BsShare_SwUpdFotaStatus_Element
              DRA_rp_SR_JobStatus_JobStatus_BsShare_SwUpdFotadecrypt_Element: accessed-variable=rp_SR_JobStatus.JobStatus_BsShare_SwUpdFotadecrypt_Element
              DRA_rp_SR_JobStatus_JobStatus_BsShare_SwUpdReflash_Element: accessed-variable=rp_SR_JobStatus.JobStatus_BsShare_SwUpdReflash_Element
              DRA_rp_SR_JobStatus_JobStatus_BsShare_VehicleConfig_Element: accessed-variable=rp_SR_JobStatus.JobStatus_BsShare_VehicleConfig_Element
              DRA_rp_SR_JobStatus_JobStatus_BsShare_VisMeet_EOLEntry_Element: accessed-variable=rp_SR_JobStatus.JobStatus_BsShare_VisMeet_EOLEntry_Element
              DRA_rp_SR_JobStatus_JobStatus_BsShare_VisMeet_Element: accessed-variable=rp_SR_JobStatus.JobStatus_BsShare_VisMeet_Element
              DRA_rp_SR_JobStatus_JobStatus_BsShare_VisteonPCBPartNumber: accessed-variable=rp_SR_JobStatus.JobStatus_BsShare_VisteonPCBPartNumber
              DRA_rp_SR_JobStatus_JobStatus_BsShare_VisteonPartNumber: accessed-variable=rp_SR_JobStatus.JobStatus_BsShare_VisteonPartNumber
              DRA_rp_SR_JobStatus_JobStatus_RefCys_Certicificate1_Element: accessed-variable=rp_SR_JobStatus.JobStatus_RefCys_Certicificate1_Element
              DRA_rp_SR_JobStatus_JobStatus_RefCys_Certicificate_Element: accessed-variable=rp_SR_JobStatus.JobStatus_RefCys_Certicificate_Element
          data-send-points:
            access DWA_pp_SR_SleepReq_SleepReqData: accessed-variable=pp_SR_SleepReq.SleepReqData
          202 x sync call, all with timeout=0.0:
            OA_rpIoHwAb_ADC_GetAsyncRawAdc: operation=rpIoHwAb_ADC.GetAsyncRawAdc
            OA_rpIoHwAb_ADC_GetSyncRawAdc: operation=rpIoHwAb_ADC.GetSyncRawAdc
            OA_rpIoHwAb_ADC_GetProcessedAdc: operation=rpIoHwAb_ADC.GetProcessedAdc
            OA_rpIoHwAb_DOut_SetOutputGroup: operation=rpIoHwAb_DOut.SetOutputGroup
            OA_rpIoHwAb_DOut_SetOutputPin: operation=rpIoHwAb_DOut.SetOutputPin
            OA_rpIoHwAb_Din_GetAsyncRawInput: operation=rpIoHwAb_Din.GetAsyncRawInput
            OA_rpIoHwAb_Din_GetProcessedInput: operation=rpIoHwAb_Din.GetProcessedInput
            OA_rpIoHwAb_Din_GetSyncRawInput: operation=rpIoHwAb_Din.GetSyncRawInput
            OA_rpIoHwAb_Din_GetInputGroup: operation=rpIoHwAb_Din.GetInputGroup
            OA_rpIoHwAb_PWM_PwmSetDuty: operation=rpIoHwAb_PWM.PwmSetDuty
            OA_rpIoHwAb_PWM_PwmSetDutyAndPeriod: operation=rpIoHwAb_PWM.PwmSetDutyAndPeriod
            OA_rpIoHwAb_PWM_PwmSetIdeal: operation=rpIoHwAb_PWM.PwmSetIdeal
            OA_rp_CS_MemAbsGet_Get_BsShare_SwUpdReflash_Element: operation=rp_CS_MemAbsGet.Get_BsShare_SwUpdReflash_Element
            OA_rp_CS_MemAbsGet_Get_BsShare_SwUpdFotaMode_Element: operation=rp_CS_MemAbsGet.Get_BsShare_SwUpdFotaMode_Element
            OA_rp_CS_MemAbsGet_Get_BsShare_SwUpdFotaFinPrint_Element: operation=rp_CS_MemAbsGet.Get_BsShare_SwUpdFotaFinPrint_Element
            OA_rp_CS_MemAbsGet_Get_BsShare_SwUpdFotaStatus_Element: operation=rp_CS_MemAbsGet.Get_BsShare_SwUpdFotaStatus_Element
            OA_rp_CS_MemAbsGet_Get_BsShare_SwUpdFotadecrypt_Element: operation=rp_CS_MemAbsGet.Get_BsShare_SwUpdFotadecrypt_Element
            OA_rp_CS_MemAbsGet_Get_BsShare_EcuPartNumber_Element: operation=rp_CS_MemAbsGet.Get_BsShare_EcuPartNumber_Element
            OA_rp_CS_MemAbsGet_Get_BsShare_VisteonPartNumber: operation=rp_CS_MemAbsGet.Get_BsShare_VisteonPartNumber
            OA_rp_CS_MemAbsGet_Get_BsShare_VisteonPCBPartNumber: operation=rp_CS_MemAbsGet.Get_BsShare_VisteonPCBPartNumber
            OA_rp_CS_MemAbsGet_Get_BsShare_ProductSerialNumber: operation=rp_CS_MemAbsGet.Get_BsShare_ProductSerialNumber
            OA_rp_CS_MemAbsGet_Get_BsShare_PCBSerialNumber: operation=rp_CS_MemAbsGet.Get_BsShare_PCBSerialNumber
            OA_rp_CS_MemAbsGet_Get_BsShare_SMTManufacturingDate: operation=rp_CS_MemAbsGet.Get_BsShare_SMTManufacturingDate
            OA_rp_CS_MemAbsGet_Get_BsShare_AssemblyManufacturingDate: operation=rp_CS_MemAbsGet.Get_BsShare_AssemblyManufacturingDate
            OA_rp_CS_MemAbsGet_Get_BsShare_SMTPlantNumber: operation=rp_CS_MemAbsGet.Get_BsShare_SMTPlantNumber
            OA_rp_CS_MemAbsGet_Get_BsShare_AssemblyPlantNumber: operation=rp_CS_MemAbsGet.Get_BsShare_AssemblyPlantNumber
            OA_rp_CS_MemAbsGet_Get_BsShare_HWModification: operation=rp_CS_MemAbsGet.Get_BsShare_HWModification
            OA_rp_CS_MemAbsGet_Get_BsShare_VisMeet_Element: operation=rp_CS_MemAbsGet.Get_BsShare_VisMeet_Element
            OA_rp_CS_MemAbsGet_Get_BsShare_VisMeet_EOLEntry_Element: operation=rp_CS_MemAbsGet.Get_BsShare_VisMeet_EOLEntry_Element
            OA_rp_CS_MemAbsGet_Get_BsShare_VehicleConfig_Element: operation=rp_CS_MemAbsGet.Get_BsShare_VehicleConfig_Element
            OA_rp_CS_MemAbsGet_Get_BsConst_SpeedoGauge_Element: operation=rp_CS_MemAbsGet.Get_BsConst_SpeedoGauge_Element
            OA_rp_CS_MemAbsGet_Get_BsConst_TachoGauge_Element: operation=rp_CS_MemAbsGet.Get_BsConst_TachoGauge_Element
            OA_rp_CS_MemAbsGet_Get_BsConst_FuelGauge_Element: operation=rp_CS_MemAbsGet.Get_BsConst_FuelGauge_Element
            OA_rp_CS_MemAbsGet_Get_BsConst_TempGauge_Element: operation=rp_CS_MemAbsGet.Get_BsConst_TempGauge_Element
            OA_rp_CS_MemAbsGet_Get_BsConst_PowerGauge_Element: operation=rp_CS_MemAbsGet.Get_BsConst_PowerGauge_Element
            OA_rp_CS_MemAbsGet_Get_BsConst_OilGauge_Element: operation=rp_CS_MemAbsGet.Get_BsConst_OilGauge_Element
            OA_rp_CS_MemAbsGet_Get_BsConst_TripComputer_Element: operation=rp_CS_MemAbsGet.Get_BsConst_TripComputer_Element
            OA_rp_CS_MemAbsGet_Get_BsConst_Compensation_Line_Slope_m: operation=rp_CS_MemAbsGet.Get_BsConst_Compensation_Line_Slope_m
            OA_rp_CS_MemAbsGet_Get_BsConst_Compensation_Line_Shift_b: operation=rp_CS_MemAbsGet.Get_BsConst_Compensation_Line_Shift_b
            OA_rp_CS_MemAbsGet_Get_BsConst_Lookup_Curve_HotSpot_Coef_X: operation=rp_CS_MemAbsGet.Get_BsConst_Lookup_Curve_HotSpot_Coef_X
            OA_rp_CS_MemAbsGet_Get_BsConst_Lookup_Curve_HotSpot_Coef_Y: operation=rp_CS_MemAbsGet.Get_BsConst_Lookup_Curve_HotSpot_Coef_Y
            OA_rp_CS_MemAbsGet_Get_BsConst_Temp_Threshold_Hysteresis_Derating: operation=rp_CS_MemAbsGet.Get_BsConst_Temp_Threshold_Hysteresis_Derating
            OA_rp_CS_MemAbsGet_Get_BsConst_Derating_Backlight_Disable: operation=rp_CS_MemAbsGet.Get_BsConst_Derating_Backlight_Disable
            OA_rp_CS_MemAbsGet_Get_BsConst_Temperature_Sensor_Conv: operation=rp_CS_MemAbsGet.Get_BsConst_Temperature_Sensor_Conv
            OA_rp_CS_MemAbsGet_Get_BsConst_PCB_Temperature_Sensor_Conv: operation=rp_CS_MemAbsGet.Get_BsConst_PCB_Temperature_Sensor_Conv
            OA_rp_CS_MemAbsGet_Get_BsConst_Display_Illum_Max_Level: operation=rp_CS_MemAbsGet.Get_BsConst_Display_Illum_Max_Level
            OA_rp_CS_MemAbsGet_Get_BsConst_PWM_boost_bypass_duty: operation=rp_CS_MemAbsGet.Get_BsConst_PWM_boost_bypass_duty
            OA_rp_CS_MemAbsGet_Get_BsConst_BsConst_Illumination_ReservedByte: operation=rp_CS_MemAbsGet.Get_BsConst_BsConst_Illumination_ReservedByte
            OA_rp_CS_MemAbsGet_Get_BsConst_Compensation_Line_Slope_m_SafeCopy1: operation=rp_CS_MemAbsGet.Get_BsConst_Compensation_Line_Slope_m_SafeCopy1
            OA_rp_CS_MemAbsGet_Get_BsConst_Compensation_Line_Shift_b_SafeCopy1: operation=rp_CS_MemAbsGet.Get_BsConst_Compensation_Line_Shift_b_SafeCopy1
            OA_rp_CS_MemAbsGet_Get_BsConst_Lookup_Curve_HotSpot_Coef_X_SafeCopy1: operation=rp_CS_MemAbsGet.Get_BsConst_Lookup_Curve_HotSpot_Coef_X_SafeCopy1
            OA_rp_CS_MemAbsGet_Get_BsConst_Lookup_Curve_HotSpot_Coef_Y_SafeCopy1: operation=rp_CS_MemAbsGet.Get_BsConst_Lookup_Curve_HotSpot_Coef_Y_SafeCopy1
            OA_rp_CS_MemAbsGet_Get_BsConst_Temp_Threshold_Hysteresis_Derating_SafeCopy1: operation=rp_CS_MemAbsGet.Get_BsConst_Temp_Threshold_Hysteresis_Derating_SafeCopy1
            OA_rp_CS_MemAbsGet_Get_BsConst_Derating_Backlight_Disable_SafeCopy1: operation=rp_CS_MemAbsGet.Get_BsConst_Derating_Backlight_Disable_SafeCopy1
            OA_rp_CS_MemAbsGet_Get_BsConst_Temperature_Sensor_Conv_SafeCopy1: operation=rp_CS_MemAbsGet.Get_BsConst_Temperature_Sensor_Conv_SafeCopy1
            OA_rp_CS_MemAbsGet_Get_BsConst_PCB_Temperature_Sensor_Conv_SafeCopy1: operation=rp_CS_MemAbsGet.Get_BsConst_PCB_Temperature_Sensor_Conv_SafeCopy1
            OA_rp_CS_MemAbsGet_Get_BsConst_Display_Illum_Max_Level_SafeCopy1: operation=rp_CS_MemAbsGet.Get_BsConst_Display_Illum_Max_Level_SafeCopy1
            OA_rp_CS_MemAbsGet_Get_BsConst_PWM_boost_bypass_duty_SafeCopy1: operation=rp_CS_MemAbsGet.Get_BsConst_PWM_boost_bypass_duty_SafeCopy1
            OA_rp_CS_MemAbsGet_Get_BsConst_BsConst_Illumination_ReservedByte_SafeCopy1: operation=rp_CS_MemAbsGet.Get_BsConst_BsConst_Illumination_ReservedByte_SafeCopy1
            OA_rp_CS_MemAbsGet_Get_BsConst_Compensation_Line_Slope_m_SafeCopy2: operation=rp_CS_MemAbsGet.Get_BsConst_Compensation_Line_Slope_m_SafeCopy2
            OA_rp_CS_MemAbsGet_Get_BsConst_Compensation_Line_Shift_b_SafeCopy2: operation=rp_CS_MemAbsGet.Get_BsConst_Compensation_Line_Shift_b_SafeCopy2
            OA_rp_CS_MemAbsGet_Get_BsConst_Lookup_Curve_HotSpot_Coef_X_SafeCopy2: operation=rp_CS_MemAbsGet.Get_BsConst_Lookup_Curve_HotSpot_Coef_X_SafeCopy2
            OA_rp_CS_MemAbsGet_Get_BsConst_Lookup_Curve_HotSpot_Coef_Y_SafeCopy2: operation=rp_CS_MemAbsGet.Get_BsConst_Lookup_Curve_HotSpot_Coef_Y_SafeCopy2
            OA_rp_CS_MemAbsGet_Get_BsConst_Temp_Threshold_Hysteresis_Derating_SafeCopy2: operation=rp_CS_MemAbsGet.Get_BsConst_Temp_Threshold_Hysteresis_Derating_SafeCopy2
            OA_rp_CS_MemAbsGet_Get_BsConst_Derating_Backlight_Disable_SafeCopy2: operation=rp_CS_MemAbsGet.Get_BsConst_Derating_Backlight_Disable_SafeCopy2
            OA_rp_CS_MemAbsGet_Get_BsConst_Temperature_Sensor_Conv_SafeCopy2: operation=rp_CS_MemAbsGet.Get_BsConst_Temperature_Sensor_Conv_SafeCopy2
            OA_rp_CS_MemAbsGet_Get_BsConst_PCB_Temperature_Sensor_Conv_SafeCopy2: operation=rp_CS_MemAbsGet.Get_BsConst_PCB_Temperature_Sensor_Conv_SafeCopy2
            OA_rp_CS_MemAbsGet_Get_BsConst_Display_Illum_Max_Level_SafeCopy2: operation=rp_CS_MemAbsGet.Get_BsConst_Display_Illum_Max_Level_SafeCopy2
            OA_rp_CS_MemAbsGet_Get_BsConst_PWM_boost_bypass_duty_SafeCopy2: operation=rp_CS_MemAbsGet.Get_BsConst_PWM_boost_bypass_duty_SafeCopy2
            OA_rp_CS_MemAbsGet_Get_BsConst_BsConst_Illumination_ReservedByte_SafeCopy2: operation=rp_CS_MemAbsGet.Get_BsConst_BsConst_Illumination_ReservedByte_SafeCopy2
            OA_rp_CS_MemAbsGet_Get_BsConst_Audio_Element: operation=rp_CS_MemAbsGet.Get_BsConst_Audio_Element
            OA_rp_CS_MemAbsGet_Get_BsConst_Warning_Element: operation=rp_CS_MemAbsGet.Get_BsConst_Warning_Element
            OA_rp_CS_MemAbsGet_Get_BsConst_RealTimeClock_Element: operation=rp_CS_MemAbsGet.Get_BsConst_RealTimeClock_Element
            OA_rp_CS_MemAbsGet_Get_BsConst_Communication_Element: operation=rp_CS_MemAbsGet.Get_BsConst_Communication_Element
            OA_rp_CS_MemAbsGet_Get_BsConst_Power_Element: operation=rp_CS_MemAbsGet.Get_BsConst_Power_Element
            OA_rp_CS_MemAbsGet_Get_BsConst_ServiceReminder_Element: operation=rp_CS_MemAbsGet.Get_BsConst_ServiceReminder_Element
            OA_rp_CS_MemAbsGet_Get_BsConst_EngOffTimer_Element: operation=rp_CS_MemAbsGet.Get_BsConst_EngOffTimer_Element
            OA_rp_CS_MemAbsGet_Get_BsCys_Certicificate_Element: operation=rp_CS_MemAbsGet.Get_BsCys_Certicificate_Element
            OA_rp_CS_MemAbsGet_Get_RefCys_Certicificate_Element: operation=rp_CS_MemAbsGet.Get_RefCys_Certicificate_Element
            OA_rp_CS_MemAbsGet_Get_RefCys_Certicificate1_Element: operation=rp_CS_MemAbsGet.Get_RefCys_Certicificate1_Element
            OA_rp_CS_MemAbsGet_Get_BsRt_Odometer_Element: operation=rp_CS_MemAbsGet.Get_BsRt_Odometer_Element
            OA_rp_CS_MemAbsGet_Get_BsRt_SpeedoGauge_Element: operation=rp_CS_MemAbsGet.Get_BsRt_SpeedoGauge_Element
            OA_rp_CS_MemAbsGet_Get_BsRt_TachoGauge_Element: operation=rp_CS_MemAbsGet.Get_BsRt_TachoGauge_Element
            OA_rp_CS_MemAbsGet_Get_BsRt_FuelGauge_Element: operation=rp_CS_MemAbsGet.Get_BsRt_FuelGauge_Element
            OA_rp_CS_MemAbsGet_Get_BsRt_TempGauge_Element: operation=rp_CS_MemAbsGet.Get_BsRt_TempGauge_Element
            OA_rp_CS_MemAbsGet_Get_BsRt_PowerGauge_Element: operation=rp_CS_MemAbsGet.Get_BsRt_PowerGauge_Element
            OA_rp_CS_MemAbsGet_Get_BsRt_OilGauge_Element: operation=rp_CS_MemAbsGet.Get_BsRt_OilGauge_Element
            OA_rp_CS_MemAbsGet_Get_BsRt_TripComputer_Element: operation=rp_CS_MemAbsGet.Get_BsRt_TripComputer_Element
            OA_rp_CS_MemAbsGet_Get_BsRt_Warning_Element: operation=rp_CS_MemAbsGet.Get_BsRt_Warning_Element
            OA_rp_CS_MemAbsGet_Get_BsRt_RealTimeClock_Element: operation=rp_CS_MemAbsGet.Get_BsRt_RealTimeClock_Element
            OA_rp_CS_MemAbsGet_Get_BsRt_Personalization_Element: operation=rp_CS_MemAbsGet.Get_BsRt_Personalization_Element
            OA_rp_CS_MemAbsGet_Get_BsRt_Illumination_Element: operation=rp_CS_MemAbsGet.Get_BsRt_Illumination_Element
            OA_rp_CS_MemAbsGet_Get_BsRt_CusDlt_Element: operation=rp_CS_MemAbsGet.Get_BsRt_CusDlt_Element
            OA_rp_CS_MemAbsGet_Get_BsReten_Odometer_Element: operation=rp_CS_MemAbsGet.Get_BsReten_Odometer_Element
            OA_rp_CS_MemAbsGet_Get_BsReten_Gauges_Element: operation=rp_CS_MemAbsGet.Get_BsReten_Gauges_Element
            OA_rp_CS_MemAbsGet_Get_BsReten_Tripcomputer_Element: operation=rp_CS_MemAbsGet.Get_BsReten_Tripcomputer_Element
            OA_rp_CS_MemAbsGet_Get_BsReten_Illumination_Element: operation=rp_CS_MemAbsGet.Get_BsReten_Illumination_Element
            OA_rp_CS_MemAbsGet_Get_BsReten_Audio_Element: operation=rp_CS_MemAbsGet.Get_BsReten_Audio_Element
            OA_rp_CS_MemAbsGet_Get_BsReten_Warning_Element: operation=rp_CS_MemAbsGet.Get_BsReten_Warning_Element
            OA_rp_CS_MemAbsGet_Get_BsReten_RealTimeClock_Element: operation=rp_CS_MemAbsGet.Get_BsReten_RealTimeClock_Element
            OA_rp_CS_MemAbsGet_Get_BsReten_Communication_Element: operation=rp_CS_MemAbsGet.Get_BsReten_Communication_Element
            OA_rp_CS_MemAbsGet_Get_BsReten_Personalization_Element: operation=rp_CS_MemAbsGet.Get_BsReten_Personalization_Element
            OA_rp_CS_MemAbsGet_Get_BsReten_VisDlt_Element: operation=rp_CS_MemAbsGet.Get_BsReten_VisDlt_Element
            OA_rp_CS_MemAbsGet_Get_BsReten_Power_Element: operation=rp_CS_MemAbsGet.Get_BsReten_Power_Element
            OA_rp_CS_MemAbsGet_Get_BsReten_Display_Element: operation=rp_CS_MemAbsGet.Get_BsReten_Display_Element
            OA_rp_CS_MemAbsGet_Get_BsDiag_ErrorRecord_Element: operation=rp_CS_MemAbsGet.Get_BsDiag_ErrorRecord_Element
            OA_rp_CS_MemAbsGet_Get_BsDiag_Dtc_Element: operation=rp_CS_MemAbsGet.Get_BsDiag_Dtc_Element
            OA_rp_CS_MemAbsSet_Set_BsShare_SwUpdReflash_Element: operation=rp_CS_MemAbsSet.Set_BsShare_SwUpdReflash_Element
            OA_rp_CS_MemAbsSet_Set_BsShare_SwUpdFotaMode_Element: operation=rp_CS_MemAbsSet.Set_BsShare_SwUpdFotaMode_Element
            OA_rp_CS_MemAbsSet_Set_BsShare_SwUpdFotaFinPrint_Element: operation=rp_CS_MemAbsSet.Set_BsShare_SwUpdFotaFinPrint_Element
            OA_rp_CS_MemAbsSet_Set_BsShare_SwUpdFotaStatus_Element: operation=rp_CS_MemAbsSet.Set_BsShare_SwUpdFotaStatus_Element
            OA_rp_CS_MemAbsSet_Set_BsShare_SwUpdFotadecrypt_Element: operation=rp_CS_MemAbsSet.Set_BsShare_SwUpdFotadecrypt_Element
            OA_rp_CS_MemAbsSet_Set_BsShare_EcuPartNumber_Element: operation=rp_CS_MemAbsSet.Set_BsShare_EcuPartNumber_Element
            OA_rp_CS_MemAbsSet_Set_BsShare_VisteonPartNumber: operation=rp_CS_MemAbsSet.Set_BsShare_VisteonPartNumber
            OA_rp_CS_MemAbsSet_Set_BsShare_VisteonPCBPartNumber: operation=rp_CS_MemAbsSet.Set_BsShare_VisteonPCBPartNumber
            OA_rp_CS_MemAbsSet_Set_BsShare_ProductSerialNumber: operation=rp_CS_MemAbsSet.Set_BsShare_ProductSerialNumber
            OA_rp_CS_MemAbsSet_Set_BsShare_PCBSerialNumber: operation=rp_CS_MemAbsSet.Set_BsShare_PCBSerialNumber
            OA_rp_CS_MemAbsSet_Set_BsShare_SMTManufacturingDate: operation=rp_CS_MemAbsSet.Set_BsShare_SMTManufacturingDate
            OA_rp_CS_MemAbsSet_Set_BsShare_AssemblyManufacturingDate: operation=rp_CS_MemAbsSet.Set_BsShare_AssemblyManufacturingDate
            OA_rp_CS_MemAbsSet_Set_BsShare_SMTPlantNumber: operation=rp_CS_MemAbsSet.Set_BsShare_SMTPlantNumber
            OA_rp_CS_MemAbsSet_Set_BsShare_AssemblyPlantNumber: operation=rp_CS_MemAbsSet.Set_BsShare_AssemblyPlantNumber
            OA_rp_CS_MemAbsSet_Set_BsShare_HWModification: operation=rp_CS_MemAbsSet.Set_BsShare_HWModification
            OA_rp_CS_MemAbsSet_Set_BsShare_VisMeet_Element: operation=rp_CS_MemAbsSet.Set_BsShare_VisMeet_Element
            OA_rp_CS_MemAbsSet_Set_BsShare_VisMeet_EOLEntry_Element: operation=rp_CS_MemAbsSet.Set_BsShare_VisMeet_EOLEntry_Element
            OA_rp_CS_MemAbsSet_Set_BsShare_VehicleConfig_Element: operation=rp_CS_MemAbsSet.Set_BsShare_VehicleConfig_Element
            OA_rp_CS_MemAbsSet_Set_BsConst_SpeedoGauge_Element: operation=rp_CS_MemAbsSet.Set_BsConst_SpeedoGauge_Element
            OA_rp_CS_MemAbsSet_Set_BsConst_TachoGauge_Element: operation=rp_CS_MemAbsSet.Set_BsConst_TachoGauge_Element
            OA_rp_CS_MemAbsSet_Set_BsConst_FuelGauge_Element: operation=rp_CS_MemAbsSet.Set_BsConst_FuelGauge_Element
            OA_rp_CS_MemAbsSet_Set_BsConst_TempGauge_Element: operation=rp_CS_MemAbsSet.Set_BsConst_TempGauge_Element
            OA_rp_CS_MemAbsSet_Set_BsConst_PowerGauge_Element: operation=rp_CS_MemAbsSet.Set_BsConst_PowerGauge_Element
            OA_rp_CS_MemAbsSet_Set_BsConst_OilGauge_Element: operation=rp_CS_MemAbsSet.Set_BsConst_OilGauge_Element
            OA_rp_CS_MemAbsSet_Set_BsConst_TripComputer_Element: operation=rp_CS_MemAbsSet.Set_BsConst_TripComputer_Element
            OA_rp_CS_MemAbsSet_Set_BsConst_Compensation_Line_Slope_m: operation=rp_CS_MemAbsSet.Set_BsConst_Compensation_Line_Slope_m
            OA_rp_CS_MemAbsSet_Set_BsConst_Compensation_Line_Shift_b: operation=rp_CS_MemAbsSet.Set_BsConst_Compensation_Line_Shift_b
            OA_rp_CS_MemAbsSet_Set_BsConst_Lookup_Curve_HotSpot_Coef_X: operation=rp_CS_MemAbsSet.Set_BsConst_Lookup_Curve_HotSpot_Coef_X
            OA_rp_CS_MemAbsSet_Set_BsConst_Lookup_Curve_HotSpot_Coef_Y: operation=rp_CS_MemAbsSet.Set_BsConst_Lookup_Curve_HotSpot_Coef_Y
            OA_rp_CS_MemAbsSet_Set_BsConst_Temp_Threshold_Hysteresis_Derating: operation=rp_CS_MemAbsSet.Set_BsConst_Temp_Threshold_Hysteresis_Derating
            OA_rp_CS_MemAbsSet_Set_BsConst_Derating_Backlight_Disable: operation=rp_CS_MemAbsSet.Set_BsConst_Derating_Backlight_Disable
            OA_rp_CS_MemAbsSet_Set_BsConst_Temperature_Sensor_Conv: operation=rp_CS_MemAbsSet.Set_BsConst_Temperature_Sensor_Conv
            OA_rp_CS_MemAbsSet_Set_BsConst_PCB_Temperature_Sensor_Conv: operation=rp_CS_MemAbsSet.Set_BsConst_PCB_Temperature_Sensor_Conv
            OA_rp_CS_MemAbsSet_Set_BsConst_Display_Illum_Max_Level: operation=rp_CS_MemAbsSet.Set_BsConst_Display_Illum_Max_Level
            OA_rp_CS_MemAbsSet_Set_BsConst_PWM_boost_bypass_duty: operation=rp_CS_MemAbsSet.Set_BsConst_PWM_boost_bypass_duty
            OA_rp_CS_MemAbsSet_Set_BsConst_BsConst_Illumination_ReservedByte: operation=rp_CS_MemAbsSet.Set_BsConst_BsConst_Illumination_ReservedByte
            OA_rp_CS_MemAbsSet_Set_BsConst_Compensation_Line_Slope_m_SafeCopy1: operation=rp_CS_MemAbsSet.Set_BsConst_Compensation_Line_Slope_m_SafeCopy1
            OA_rp_CS_MemAbsSet_Set_BsConst_Compensation_Line_Shift_b_SafeCopy1: operation=rp_CS_MemAbsSet.Set_BsConst_Compensation_Line_Shift_b_SafeCopy1
            OA_rp_CS_MemAbsSet_Set_BsConst_Lookup_Curve_HotSpot_Coef_X_SafeCopy1: operation=rp_CS_MemAbsSet.Set_BsConst_Lookup_Curve_HotSpot_Coef_X_SafeCopy1
            OA_rp_CS_MemAbsSet_Set_BsConst_Lookup_Curve_HotSpot_Coef_Y_SafeCopy1: operation=rp_CS_MemAbsSet.Set_BsConst_Lookup_Curve_HotSpot_Coef_Y_SafeCopy1
            OA_rp_CS_MemAbsSet_Set_BsConst_Temp_Threshold_Hysteresis_Derating_SafeCopy1: operation=rp_CS_MemAbsSet.Set_BsConst_Temp_Threshold_Hysteresis_Derating_SafeCopy1
            OA_rp_CS_MemAbsSet_Set_BsConst_Derating_Backlight_Disable_SafeCopy1: operation=rp_CS_MemAbsSet.Set_BsConst_Derating_Backlight_Disable_SafeCopy1
            OA_rp_CS_MemAbsSet_Set_BsConst_Temperature_Sensor_Conv_SafeCopy1: operation=rp_CS_MemAbsSet.Set_BsConst_Temperature_Sensor_Conv_SafeCopy1
            OA_rp_CS_MemAbsSet_Set_BsConst_PCB_Temperature_Sensor_Conv_SafeCopy1: operation=rp_CS_MemAbsSet.Set_BsConst_PCB_Temperature_Sensor_Conv_SafeCopy1
            OA_rp_CS_MemAbsSet_Set_BsConst_Display_Illum_Max_Level_SafeCopy1: operation=rp_CS_MemAbsSet.Set_BsConst_Display_Illum_Max_Level_SafeCopy1
            OA_rp_CS_MemAbsSet_Set_BsConst_PWM_boost_bypass_duty_SafeCopy1: operation=rp_CS_MemAbsSet.Set_BsConst_PWM_boost_bypass_duty_SafeCopy1
            OA_rp_CS_MemAbsSet_Set_BsConst_BsConst_Illumination_ReservedByte_SafeCopy1: operation=rp_CS_MemAbsSet.Set_BsConst_BsConst_Illumination_ReservedByte_SafeCopy1
            OA_rp_CS_MemAbsSet_Set_BsConst_Compensation_Line_Slope_m_SafeCopy2: operation=rp_CS_MemAbsSet.Set_BsConst_Compensation_Line_Slope_m_SafeCopy2
            OA_rp_CS_MemAbsSet_Set_BsConst_Compensation_Line_Shift_b_SafeCopy2: operation=rp_CS_MemAbsSet.Set_BsConst_Compensation_Line_Shift_b_SafeCopy2
            OA_rp_CS_MemAbsSet_Set_BsConst_Lookup_Curve_HotSpot_Coef_X_SafeCopy2: operation=rp_CS_MemAbsSet.Set_BsConst_Lookup_Curve_HotSpot_Coef_X_SafeCopy2
            OA_rp_CS_MemAbsSet_Set_BsConst_Lookup_Curve_HotSpot_Coef_Y_SafeCopy2: operation=rp_CS_MemAbsSet.Set_BsConst_Lookup_Curve_HotSpot_Coef_Y_SafeCopy2
            OA_rp_CS_MemAbsSet_Set_BsConst_Temp_Threshold_Hysteresis_Derating_SafeCopy2: operation=rp_CS_MemAbsSet.Set_BsConst_Temp_Threshold_Hysteresis_Derating_SafeCopy2
            OA_rp_CS_MemAbsSet_Set_BsConst_Derating_Backlight_Disable_SafeCopy2: operation=rp_CS_MemAbsSet.Set_BsConst_Derating_Backlight_Disable_SafeCopy2
            OA_rp_CS_MemAbsSet_Set_BsConst_Temperature_Sensor_Conv_SafeCopy2: operation=rp_CS_MemAbsSet.Set_BsConst_Temperature_Sensor_Conv_SafeCopy2
            OA_rp_CS_MemAbsSet_Set_BsConst_PCB_Temperature_Sensor_Conv_SafeCopy2: operation=rp_CS_MemAbsSet.Set_BsConst_PCB_Temperature_Sensor_Conv_SafeCopy2
            OA_rp_CS_MemAbsSet_Set_BsConst_Display_Illum_Max_Level_SafeCopy2: operation=rp_CS_MemAbsSet.Set_BsConst_Display_Illum_Max_Level_SafeCopy2
            OA_rp_CS_MemAbsSet_Set_BsConst_PWM_boost_bypass_duty_SafeCopy2: operation=rp_CS_MemAbsSet.Set_BsConst_PWM_boost_bypass_duty_SafeCopy2
            OA_rp_CS_MemAbsSet_Set_BsConst_BsConst_Illumination_ReservedByte_SafeCopy2: operation=rp_CS_MemAbsSet.Set_BsConst_BsConst_Illumination_ReservedByte_SafeCopy2
            OA_rp_CS_MemAbsSet_Set_BsConst_Audio_Element: operation=rp_CS_MemAbsSet.Set_BsConst_Audio_Element
            OA_rp_CS_MemAbsSet_Set_BsConst_Warning_Element: operation=rp_CS_MemAbsSet.Set_BsConst_Warning_Element
            OA_rp_CS_MemAbsSet_Set_BsConst_RealTimeClock_Element: operation=rp_CS_MemAbsSet.Set_BsConst_RealTimeClock_Element
            OA_rp_CS_MemAbsSet_Set_BsConst_Communication_Element: operation=rp_CS_MemAbsSet.Set_BsConst_Communication_Element
            OA_rp_CS_MemAbsSet_Set_BsConst_Power_Element: operation=rp_CS_MemAbsSet.Set_BsConst_Power_Element
            OA_rp_CS_MemAbsSet_Set_BsConst_ServiceReminder_Element: operation=rp_CS_MemAbsSet.Set_BsConst_ServiceReminder_Element
            OA_rp_CS_MemAbsSet_Set_BsConst_EngOffTimer_Element: operation=rp_CS_MemAbsSet.Set_BsConst_EngOffTimer_Element
            OA_rp_CS_MemAbsSet_Set_BsCys_Certicificate_Element: operation=rp_CS_MemAbsSet.Set_BsCys_Certicificate_Element
            OA_rp_CS_MemAbsSet_Set_RefCys_Certicificate_Element: operation=rp_CS_MemAbsSet.Set_RefCys_Certicificate_Element
            OA_rp_CS_MemAbsSet_Set_RefCys_Certicificate1_Element: operation=rp_CS_MemAbsSet.Set_RefCys_Certicificate1_Element
            OA_rp_CS_MemAbsSet_Set_BsRt_Odometer_Element: operation=rp_CS_MemAbsSet.Set_BsRt_Odometer_Element
            OA_rp_CS_MemAbsSet_Set_BsRt_SpeedoGauge_Element: operation=rp_CS_MemAbsSet.Set_BsRt_SpeedoGauge_Element
            OA_rp_CS_MemAbsSet_Set_BsRt_TachoGauge_Element: operation=rp_CS_MemAbsSet.Set_BsRt_TachoGauge_Element
            OA_rp_CS_MemAbsSet_Set_BsRt_FuelGauge_Element: operation=rp_CS_MemAbsSet.Set_BsRt_FuelGauge_Element
            OA_rp_CS_MemAbsSet_Set_BsRt_TempGauge_Element: operation=rp_CS_MemAbsSet.Set_BsRt_TempGauge_Element
            OA_rp_CS_MemAbsSet_Set_BsRt_PowerGauge_Element: operation=rp_CS_MemAbsSet.Set_BsRt_PowerGauge_Element
            OA_rp_CS_MemAbsSet_Set_BsRt_OilGauge_Element: operation=rp_CS_MemAbsSet.Set_BsRt_OilGauge_Element
            OA_rp_CS_MemAbsSet_Set_BsRt_TripComputer_Element: operation=rp_CS_MemAbsSet.Set_BsRt_TripComputer_Element
            OA_rp_CS_MemAbsSet_Set_BsRt_Warning_Element: operation=rp_CS_MemAbsSet.Set_BsRt_Warning_Element
            OA_rp_CS_MemAbsSet_Set_BsRt_RealTimeClock_Element: operation=rp_CS_MemAbsSet.Set_BsRt_RealTimeClock_Element
            OA_rp_CS_MemAbsSet_Set_BsRt_Personalization_Element: operation=rp_CS_MemAbsSet.Set_BsRt_Personalization_Element
            OA_rp_CS_MemAbsSet_Set_BsRt_Illumination_Element: operation=rp_CS_MemAbsSet.Set_BsRt_Illumination_Element
            OA_rp_CS_MemAbsSet_Set_BsRt_CusDlt_Element: operation=rp_CS_MemAbsSet.Set_BsRt_CusDlt_Element
            OA_rp_CS_MemAbsSet_Set_BsReten_Odometer_Element: operation=rp_CS_MemAbsSet.Set_BsReten_Odometer_Element
            OA_rp_CS_MemAbsSet_Set_BsReten_Gauges_Element: operation=rp_CS_MemAbsSet.Set_BsReten_Gauges_Element
            OA_rp_CS_MemAbsSet_Set_BsReten_Tripcomputer_Element: operation=rp_CS_MemAbsSet.Set_BsReten_Tripcomputer_Element
            OA_rp_CS_MemAbsSet_Set_BsReten_Illumination_Element: operation=rp_CS_MemAbsSet.Set_BsReten_Illumination_Element
            OA_rp_CS_MemAbsSet_Set_BsReten_Audio_Element: operation=rp_CS_MemAbsSet.Set_BsReten_Audio_Element
            OA_rp_CS_MemAbsSet_Set_BsReten_Warning_Element: operation=rp_CS_MemAbsSet.Set_BsReten_Warning_Element
            OA_rp_CS_MemAbsSet_Set_BsReten_RealTimeClock_Element: operation=rp_CS_MemAbsSet.Set_BsReten_RealTimeClock_Element
            OA_rp_CS_MemAbsSet_Set_BsReten_Communication_Element: operation=rp_CS_MemAbsSet.Set_BsReten_Communication_Element
            OA_rp_CS_MemAbsSet_Set_BsReten_Personalization_Element: operation=rp_CS_MemAbsSet.Set_BsReten_Personalization_Element
            OA_rp_CS_MemAbsSet_Set_BsReten_VisDlt_Element: operation=rp_CS_MemAbsSet.Set_BsReten_VisDlt_Element
            OA_rp_CS_MemAbsSet_Set_BsReten_Power_Element: operation=rp_CS_MemAbsSet.Set_BsReten_Power_Element
            OA_rp_CS_MemAbsSet_Set_BsReten_Display_Element: operation=rp_CS_MemAbsSet.Set_BsReten_Display_Element
            OA_rp_CS_MemAbsSet_Set_BsDiag_ErrorRecord_Element: operation=rp_CS_MemAbsSet.Set_BsDiag_ErrorRecord_Element
            OA_rp_CS_MemAbsSet_Set_BsDiag_Dtc_Element: operation=rp_CS_MemAbsSet.Set_BsDiag_Dtc_Element
        CMeetCdd_Impl_OnCommand
        CMeetCdd_Meet_Mgrdiagcdd_Action
        CMeetCdd_RID_DiagAction
        CMeetCdd_Read_ManufModeStatus
        CMeetCdd_Write_Mfg_Flag
  96 x constant specification:
    CMeetCddSleepReqDataValue0: value-spec=CMeetCddSleepReqDataValue0:false
    CMeetCddJobStatus_BsConst_Audio_ElementValue0: value-spec=CMeetCddJobStatus_BsConst_Audio_ElementValue0:0
    CMeetCddJobStatus_BsConst_BsConst_Illumination_ReservedByteValue0: value-spec=CMeetCddJobStatus_BsConst_BsConst_Illumination_ReservedByteValue0:0
    CMeetCddJobStatus_BsConst_BsConst_Illumination_ReservedByte_SafeCopy1Value0: value-spec=CMeetCddJobStatus_BsConst_BsConst_Illumination_ReservedByte_SafeCopy1Value0:0
    CMeetCddJobStatus_BsConst_BsConst_Illumination_ReservedByte_SafeCopy2Value0: value-spec=CMeetCddJobStatus_BsConst_BsConst_Illumination_ReservedByte_SafeCopy2Value0:0
    CMeetCddJobStatus_BsConst_Communication_ElementValue0: value-spec=CMeetCddJobStatus_BsConst_Communication_ElementValue0:0
    CMeetCddJobStatus_BsConst_Compensation_Line_Shift_bValue0: value-spec=CMeetCddJobStatus_BsConst_Compensation_Line_Shift_bValue0:0
    CMeetCddJobStatus_BsConst_Compensation_Line_Shift_b_SafeCopy1Value0: value-spec=CMeetCddJobStatus_BsConst_Compensation_Line_Shift_b_SafeCopy1Value0:0
    CMeetCddJobStatus_BsConst_Compensation_Line_Shift_b_SafeCopy2Value0: value-spec=CMeetCddJobStatus_BsConst_Compensation_Line_Shift_b_SafeCopy2Value0:0
    CMeetCddJobStatus_BsConst_Compensation_Line_Slope_mValue0: value-spec=CMeetCddJobStatus_BsConst_Compensation_Line_Slope_mValue0:0
    CMeetCddJobStatus_BsConst_Compensation_Line_Slope_m_SafeCopy1Value0: value-spec=CMeetCddJobStatus_BsConst_Compensation_Line_Slope_m_SafeCopy1Value0:0
    CMeetCddJobStatus_BsConst_Compensation_Line_Slope_m_SafeCopy2Value0: value-spec=CMeetCddJobStatus_BsConst_Compensation_Line_Slope_m_SafeCopy2Value0:0
    CMeetCddJobStatus_BsConst_Derating_Backlight_DisableValue0: value-spec=CMeetCddJobStatus_BsConst_Derating_Backlight_DisableValue0:0
    CMeetCddJobStatus_BsConst_Derating_Backlight_Disable_SafeCopy1Value0: value-spec=CMeetCddJobStatus_BsConst_Derating_Backlight_Disable_SafeCopy1Value0:0
    CMeetCddJobStatus_BsConst_Derating_Backlight_Disable_SafeCopy2Value0: value-spec=CMeetCddJobStatus_BsConst_Derating_Backlight_Disable_SafeCopy2Value0:0
    CMeetCddJobStatus_BsConst_Display_Illum_Max_LevelValue0: value-spec=CMeetCddJobStatus_BsConst_Display_Illum_Max_LevelValue0:0
    CMeetCddJobStatus_BsConst_Display_Illum_Max_Level_SafeCopy1Value0: value-spec=CMeetCddJobStatus_BsConst_Display_Illum_Max_Level_SafeCopy1Value0:0
    CMeetCddJobStatus_BsConst_Display_Illum_Max_Level_SafeCopy2Value0: value-spec=CMeetCddJobStatus_BsConst_Display_Illum_Max_Level_SafeCopy2Value0:0
    CMeetCddJobStatus_BsConst_EngOffTimer_ElementValue0: value-spec=CMeetCddJobStatus_BsConst_EngOffTimer_ElementValue0:0
    CMeetCddJobStatus_BsConst_FuelGauge_ElementValue0: value-spec=CMeetCddJobStatus_BsConst_FuelGauge_ElementValue0:0
    CMeetCddJobStatus_BsConst_Lookup_Curve_HotSpot_Coef_XValue0: value-spec=CMeetCddJobStatus_BsConst_Lookup_Curve_HotSpot_Coef_XValue0:0
    CMeetCddJobStatus_BsConst_Lookup_Curve_HotSpot_Coef_X_SafeCopy1Value0: value-spec=CMeetCddJobStatus_BsConst_Lookup_Curve_HotSpot_Coef_X_SafeCopy1Value0:0
    CMeetCddJobStatus_BsConst_Lookup_Curve_HotSpot_Coef_X_SafeCopy2Value0: value-spec=CMeetCddJobStatus_BsConst_Lookup_Curve_HotSpot_Coef_X_SafeCopy2Value0:0
    CMeetCddJobStatus_BsConst_Lookup_Curve_HotSpot_Coef_YValue0: value-spec=CMeetCddJobStatus_BsConst_Lookup_Curve_HotSpot_Coef_YValue0:0
    CMeetCddJobStatus_BsConst_Lookup_Curve_HotSpot_Coef_Y_SafeCopy1Value0: value-spec=CMeetCddJobStatus_BsConst_Lookup_Curve_HotSpot_Coef_Y_SafeCopy1Value0:0
    CMeetCddJobStatus_BsConst_Lookup_Curve_HotSpot_Coef_Y_SafeCopy2Value0: value-spec=CMeetCddJobStatus_BsConst_Lookup_Curve_HotSpot_Coef_Y_SafeCopy2Value0:0
    CMeetCddJobStatus_BsConst_OilGauge_ElementValue0: value-spec=CMeetCddJobStatus_BsConst_OilGauge_ElementValue0:0
    CMeetCddJobStatus_BsConst_PCB_Temperature_Sensor_ConvValue0: value-spec=CMeetCddJobStatus_BsConst_PCB_Temperature_Sensor_ConvValue0:0
    CMeetCddJobStatus_BsConst_PCB_Temperature_Sensor_Conv_SafeCopy1Value0: value-spec=CMeetCddJobStatus_BsConst_PCB_Temperature_Sensor_Conv_SafeCopy1Value0:0
    CMeetCddJobStatus_BsConst_PCB_Temperature_Sensor_Conv_SafeCopy2Value0: value-spec=CMeetCddJobStatus_BsConst_PCB_Temperature_Sensor_Conv_SafeCopy2Value0:0
    CMeetCddJobStatus_BsConst_PWM_boost_bypass_dutyValue0: value-spec=CMeetCddJobStatus_BsConst_PWM_boost_bypass_dutyValue0:0
    CMeetCddJobStatus_BsConst_PWM_boost_bypass_duty_SafeCopy1Value0: value-spec=CMeetCddJobStatus_BsConst_PWM_boost_bypass_duty_SafeCopy1Value0:0
    CMeetCddJobStatus_BsConst_PWM_boost_bypass_duty_SafeCopy2Value0: value-spec=CMeetCddJobStatus_BsConst_PWM_boost_bypass_duty_SafeCopy2Value0:0
    CMeetCddJobStatus_BsConst_PowerGauge_ElementValue0: value-spec=CMeetCddJobStatus_BsConst_PowerGauge_ElementValue0:0
    CMeetCddJobStatus_BsConst_Power_ElementValue0: value-spec=CMeetCddJobStatus_BsConst_Power_ElementValue0:0
    CMeetCddJobStatus_BsConst_RealTimeClock_ElementValue0: value-spec=CMeetCddJobStatus_BsConst_RealTimeClock_ElementValue0:0
    CMeetCddJobStatus_BsConst_ServiceReminder_ElementValue0: value-spec=CMeetCddJobStatus_BsConst_ServiceReminder_ElementValue0:0
    CMeetCddJobStatus_BsConst_SpeedoGauge_ElementValue0: value-spec=CMeetCddJobStatus_BsConst_SpeedoGauge_ElementValue0:0
    CMeetCddJobStatus_BsConst_TachoGauge_ElementValue0: value-spec=CMeetCddJobStatus_BsConst_TachoGauge_ElementValue0:0
    CMeetCddJobStatus_BsConst_TempGauge_ElementValue0: value-spec=CMeetCddJobStatus_BsConst_TempGauge_ElementValue0:0
    CMeetCddJobStatus_BsConst_Temp_Threshold_Hysteresis_DeratingValue0: value-spec=CMeetCddJobStatus_BsConst_Temp_Threshold_Hysteresis_DeratingValue0:0
    CMeetCddJobStatus_BsConst_Temp_Threshold_Hysteresis_Derating_SafeCopy1Value0: value-spec=CMeetCddJobStatus_BsConst_Temp_Threshold_Hysteresis_Derating_SafeCopy1Value0:0
    CMeetCddJobStatus_BsConst_Temp_Threshold_Hysteresis_Derating_SafeCopy2Value0: value-spec=CMeetCddJobStatus_BsConst_Temp_Threshold_Hysteresis_Derating_SafeCopy2Value0:0
    CMeetCddJobStatus_BsConst_Temperature_Sensor_ConvValue0: value-spec=CMeetCddJobStatus_BsConst_Temperature_Sensor_ConvValue0:0
    CMeetCddJobStatus_BsConst_Temperature_Sensor_Conv_SafeCopy1Value0: value-spec=CMeetCddJobStatus_BsConst_Temperature_Sensor_Conv_SafeCopy1Value0:0
    CMeetCddJobStatus_BsConst_Temperature_Sensor_Conv_SafeCopy2Value0: value-spec=CMeetCddJobStatus_BsConst_Temperature_Sensor_Conv_SafeCopy2Value0:0
    CMeetCddJobStatus_BsConst_TripComputer_ElementValue0: value-spec=CMeetCddJobStatus_BsConst_TripComputer_ElementValue0:0
    CMeetCddJobStatus_BsConst_Warning_ElementValue0: value-spec=CMeetCddJobStatus_BsConst_Warning_ElementValue0:0
    CMeetCddJobStatus_BsCys_Certicificate_ElementValue0: value-spec=CMeetCddJobStatus_BsCys_Certicificate_ElementValue0:0
    CMeetCddJobStatus_BsDiag_Dtc_ElementValue0: value-spec=CMeetCddJobStatus_BsDiag_Dtc_ElementValue0:0
    CMeetCddJobStatus_BsDiag_ErrorRecord_ElementValue0: value-spec=CMeetCddJobStatus_BsDiag_ErrorRecord_ElementValue0:0
    CMeetCddJobStatus_BsReten_Audio_ElementValue0: value-spec=CMeetCddJobStatus_BsReten_Audio_ElementValue0:0
    CMeetCddJobStatus_BsReten_Communication_ElementValue0: value-spec=CMeetCddJobStatus_BsReten_Communication_ElementValue0:0
    CMeetCddJobStatus_BsReten_Display_ElementValue0: value-spec=CMeetCddJobStatus_BsReten_Display_ElementValue0:0
    CMeetCddJobStatus_BsReten_Gauges_ElementValue0: value-spec=CMeetCddJobStatus_BsReten_Gauges_ElementValue0:0
    CMeetCddJobStatus_BsReten_Illumination_ElementValue0: value-spec=CMeetCddJobStatus_BsReten_Illumination_ElementValue0:0
    CMeetCddJobStatus_BsReten_Odometer_ElementValue0: value-spec=CMeetCddJobStatus_BsReten_Odometer_ElementValue0:0
    CMeetCddJobStatus_BsReten_Personalization_ElementValue0: value-spec=CMeetCddJobStatus_BsReten_Personalization_ElementValue0:0
    CMeetCddJobStatus_BsReten_Power_ElementValue0: value-spec=CMeetCddJobStatus_BsReten_Power_ElementValue0:0
    CMeetCddJobStatus_BsReten_RealTimeClock_ElementValue0: value-spec=CMeetCddJobStatus_BsReten_RealTimeClock_ElementValue0:0
    CMeetCddJobStatus_BsReten_Tripcomputer_ElementValue0: value-spec=CMeetCddJobStatus_BsReten_Tripcomputer_ElementValue0:0
    CMeetCddJobStatus_BsReten_VisDlt_ElementValue0: value-spec=CMeetCddJobStatus_BsReten_VisDlt_ElementValue0:0
    CMeetCddJobStatus_BsReten_Warning_ElementValue0: value-spec=CMeetCddJobStatus_BsReten_Warning_ElementValue0:0
    CMeetCddJobStatus_BsRt_CusDlt_ElementValue0: value-spec=CMeetCddJobStatus_BsRt_CusDlt_ElementValue0:0
    CMeetCddJobStatus_BsRt_FuelGauge_ElementValue0: value-spec=CMeetCddJobStatus_BsRt_FuelGauge_ElementValue0:0
    CMeetCddJobStatus_BsRt_Illumination_ElementValue0: value-spec=CMeetCddJobStatus_BsRt_Illumination_ElementValue0:0
    CMeetCddJobStatus_BsRt_Odometer_ElementValue0: value-spec=CMeetCddJobStatus_BsRt_Odometer_ElementValue0:0
    CMeetCddJobStatus_BsRt_OilGauge_ElementValue0: value-spec=CMeetCddJobStatus_BsRt_OilGauge_ElementValue0:0
    CMeetCddJobStatus_BsRt_Personalization_ElementValue0: value-spec=CMeetCddJobStatus_BsRt_Personalization_ElementValue0:0
    CMeetCddJobStatus_BsRt_PowerGauge_ElementValue0: value-spec=CMeetCddJobStatus_BsRt_PowerGauge_ElementValue0:0
    CMeetCddJobStatus_BsRt_RealTimeClock_ElementValue0: value-spec=CMeetCddJobStatus_BsRt_RealTimeClock_ElementValue0:0
    CMeetCddJobStatus_BsRt_SpeedoGauge_ElementValue0: value-spec=CMeetCddJobStatus_BsRt_SpeedoGauge_ElementValue0:0
    CMeetCddJobStatus_BsRt_TachoGauge_ElementValue0: value-spec=CMeetCddJobStatus_BsRt_TachoGauge_ElementValue0:0
    CMeetCddJobStatus_BsRt_TempGauge_ElementValue0: value-spec=CMeetCddJobStatus_BsRt_TempGauge_ElementValue0:0
    CMeetCddJobStatus_BsRt_TripComputer_ElementValue0: value-spec=CMeetCddJobStatus_BsRt_TripComputer_ElementValue0:0
    CMeetCddJobStatus_BsRt_Warning_ElementValue0: value-spec=CMeetCddJobStatus_BsRt_Warning_ElementValue0:0
    CMeetCddJobStatus_BsShare_AssemblyManufacturingDateValue0: value-spec=CMeetCddJobStatus_BsShare_AssemblyManufacturingDateValue0:0
    CMeetCddJobStatus_BsShare_AssemblyPlantNumberValue0: value-spec=CMeetCddJobStatus_BsShare_AssemblyPlantNumberValue0:0
    CMeetCddJobStatus_BsShare_EcuPartNumber_ElementValue0: value-spec=CMeetCddJobStatus_BsShare_EcuPartNumber_ElementValue0:0
    CMeetCddJobStatus_BsShare_HWModificationValue0: value-spec=CMeetCddJobStatus_BsShare_HWModificationValue0:0
    CMeetCddJobStatus_BsShare_PCBSerialNumberValue0: value-spec=CMeetCddJobStatus_BsShare_PCBSerialNumberValue0:0
    CMeetCddJobStatus_BsShare_ProductSerialNumberValue0: value-spec=CMeetCddJobStatus_BsShare_ProductSerialNumberValue0:0
    CMeetCddJobStatus_BsShare_SMTManufacturingDateValue0: value-spec=CMeetCddJobStatus_BsShare_SMTManufacturingDateValue0:0
    CMeetCddJobStatus_BsShare_SMTPlantNumberValue0: value-spec=CMeetCddJobStatus_BsShare_SMTPlantNumberValue0:0
    CMeetCddJobStatus_BsShare_SwUpdFotaFinPrint_ElementValue0: value-spec=CMeetCddJobStatus_BsShare_SwUpdFotaFinPrint_ElementValue0:0
    CMeetCddJobStatus_BsShare_SwUpdFotaMode_ElementValue0: value-spec=CMeetCddJobStatus_BsShare_SwUpdFotaMode_ElementValue0:0
    CMeetCddJobStatus_BsShare_SwUpdFotaStatus_ElementValue0: value-spec=CMeetCddJobStatus_BsShare_SwUpdFotaStatus_ElementValue0:0
    CMeetCddJobStatus_BsShare_SwUpdFotadecrypt_ElementValue0: value-spec=CMeetCddJobStatus_BsShare_SwUpdFotadecrypt_ElementValue0:0
    CMeetCddJobStatus_BsShare_SwUpdReflash_ElementValue0: value-spec=CMeetCddJobStatus_BsShare_SwUpdReflash_ElementValue0:0
    CMeetCddJobStatus_BsShare_VehicleConfig_ElementValue0: value-spec=CMeetCddJobStatus_BsShare_VehicleConfig_ElementValue0:0
    CMeetCddJobStatus_BsShare_VisMeet_EOLEntry_ElementValue0: value-spec=CMeetCddJobStatus_BsShare_VisMeet_EOLEntry_ElementValue0:0
    CMeetCddJobStatus_BsShare_VisMeet_ElementValue0: value-spec=CMeetCddJobStatus_BsShare_VisMeet_ElementValue0:0
    CMeetCddJobStatus_BsShare_VisteonPCBPartNumberValue0: value-spec=CMeetCddJobStatus_BsShare_VisteonPCBPartNumberValue0:0
    CMeetCddJobStatus_BsShare_VisteonPartNumberValue0: value-spec=CMeetCddJobStatus_BsShare_VisteonPartNumberValue0:0
    CMeetCddJobStatus_RefCys_Certicificate1_ElementValue0: value-spec=CMeetCddJobStatus_RefCys_Certicificate1_ElementValue0:0
    CMeetCddJobStatus_RefCys_Certicificate_ElementValue0: value-spec=CMeetCddJobStatus_RefCys_Certicificate_ElementValue0:0
  swc implementation IMPL_CMeetCdd: programming-language=C, behavior=IB_CMeetCdd
    code-descriptors:
      code CodeDescriptor
  application sw component type RamTst
    provide port pp_CmpLibCmd_RamTst: server-com-spec{operation=Impl_OnCommand, queue-length=1}, provided-interface=if_CS_ModeOnCommand
    behavior IB_RamTst: port-api-option{enable-take-address=false, indirect-api=false, port=pp_CmpLibCmd_RamTst}
      operation invoked event OIE_pp_CmpLibCmd_RamTst_RamTst_Impl_OnCommandTrigByImpl_OnCommand: start-on-event=RamTst_Impl_OnCommand, operation=pp_CmpLibCmd_RamTst.Impl_OnCommand
      timing event TERamTst_MainFunction: start-on-event=RamTst_MainFunction, period=0.01
      runnable RamTst_Impl_OnCommand: can-be-invoked-concurrently=true
      runnable RamTst_MainFunction: can-be-invoked-concurrently=true
  swc implementation IMPL_RamTst: programming-language=C, behavior=IB_RamTst
    code-descriptors:
      code CodeDescriptor
  application sw component type SysTst
    provide port pp_CmpLibCmd_SysTst: server-com-spec{operation=Impl_OnCommand, queue-length=1}, provided-interface=if_CS_ModeOnCommand
    behavior IB_SysTst: port-api-option{enable-take-address=false, indirect-api=false, port=pp_CmpLibCmd_SysTst}
      operation invoked event OIE_pp_CmpLibCmd_SysTst_SysTst_Impl_OnCommandTrigByImpl_OnCommand: start-on-event=SysTst_Impl_OnCommand, operation=pp_CmpLibCmd_SysTst.Impl_OnCommand
      timing event TESysTst_MainFunction: start-on-event=SysTst_MainFunction, period=0.01
      runnable SysTst_Impl_OnCommand: can-be-invoked-concurrently=true
      runnable SysTst_MainFunction: can-be-invoked-concurrently=true
  swc implementation IMPL_SysTst: programming-language=C, behavior=IB_SysTst
    code-descriptors:
      code CodeDescriptor
  application sw component type DltExt
    4 x provide port:
      ppCS_DltExt_SendLogMessage: server-com-spec{operation=If_CS_DltExt_SendLogMessage/SendLogMessage, queue-length=1}, provided-interface=If_CS_DltExt_SendLogMessage
      ppCS_SetCounterToDefault: server-com-spec{operation=SetCounterToDefault, queue-length=1}, provided-interface=If_CS_SetCounterToDefault
      ppCS_SetLogsToDefault: server-com-spec{operation=SetLogsToDefault, queue-length=1}, provided-interface=If_CS_SetLogsToDefault
      ppCs_DltExt_GetResetInfo: server-com-spec{operation=GetResetInfo, queue-length=1}, provided-interface=if_CS_DltExt_GetResetInfo
    require port rp_CS_MemAbsGet: required-interface=if_CS_MemAbsGet
    require port rp_CS_MemAbsSet: required-interface=if_CS_MemAbsSet
    require port rp_CS_MemAbs_NvMWriteStatus: required-interface=if_CS_MemAbs_NvMWriteStatus
    behavior IB_DltExt
      operation invoked event OIE_ppCs_DltExt_GetResetInfo_DltExt_GetResetInfoTrigByGetResetInfo: start-on-event=DltExt_GetResetInfo, operation=ppCs_DltExt_GetResetInfo.GetResetInfo
      timing event TEDltExt_MainFunction: start-on-event=DltExt_MainFunction, period=0.1
      operation invoked event OIE_ppCS_DltExt_SendLogMessage_DltExt_SendLogMessageTrigBySendLogMessage: start-on-event=DltExt_SendLogMessage, operation=ppCS_DltExt_SendLogMessage.SendLogMessage
      operation invoked event OIE_ppCS_SetCounterToDefault_DltExt_SetCounterToDefaultTrigBySetCounterToDefault: start-on-event=DltExt_SetCounterToDefault, operation=ppCS_SetCounterToDefault.SetCounterToDefault
      operation invoked event OIE_ppCS_SetLogsToDefault_DltExt_SetLogsToDefaultTrigBySetLogsToDefault: start-on-event=DltExt_SetLogsToDefault, operation=ppCS_SetLogsToDefault.SetLogsToDefault
      port-api-options:
        enable-take-address=false, indirect-api=false, port=ppCS_DltExt_SendLogMessage
        enable-take-address=false, indirect-api=false, port=ppCS_SetCounterToDefault
        enable-take-address=false, indirect-api=false, port=ppCS_SetLogsToDefault
        enable-take-address=false, indirect-api=false, port=ppCs_DltExt_GetResetInfo
        enable-take-address=false, indirect-api=false, port=DltExt/rp_CS_MemAbsGet
        enable-take-address=false, indirect-api=false, port=DltExt/rp_CS_MemAbsSet
        enable-take-address=false, indirect-api=false, port=DltExt/rp_CS_MemAbs_NvMWriteStatus
      5 x runnable, all with can-be-invoked-concurrently=true:
        DltExt_GetResetInfo
        DltExt_MainFunction
          191 x sync call, all with timeout=0.0:
            OA_rp_CS_MemAbsGet_Get_BsShare_SwUpdReflash_Element: operation=rp_CS_MemAbsGet.Get_BsShare_SwUpdReflash_Element
            OA_rp_CS_MemAbsGet_Get_BsShare_SwUpdFotaMode_Element: operation=rp_CS_MemAbsGet.Get_BsShare_SwUpdFotaMode_Element
            OA_rp_CS_MemAbsGet_Get_BsShare_SwUpdFotaFinPrint_Element: operation=rp_CS_MemAbsGet.Get_BsShare_SwUpdFotaFinPrint_Element
            OA_rp_CS_MemAbsGet_Get_BsShare_SwUpdFotaStatus_Element: operation=rp_CS_MemAbsGet.Get_BsShare_SwUpdFotaStatus_Element
            OA_rp_CS_MemAbsGet_Get_BsShare_SwUpdFotadecrypt_Element: operation=rp_CS_MemAbsGet.Get_BsShare_SwUpdFotadecrypt_Element
            OA_rp_CS_MemAbsGet_Get_BsShare_EcuPartNumber_Element: operation=rp_CS_MemAbsGet.Get_BsShare_EcuPartNumber_Element
            OA_rp_CS_MemAbsGet_Get_BsShare_VisteonPartNumber: operation=rp_CS_MemAbsGet.Get_BsShare_VisteonPartNumber
            OA_rp_CS_MemAbsGet_Get_BsShare_VisteonPCBPartNumber: operation=rp_CS_MemAbsGet.Get_BsShare_VisteonPCBPartNumber
            OA_rp_CS_MemAbsGet_Get_BsShare_ProductSerialNumber: operation=rp_CS_MemAbsGet.Get_BsShare_ProductSerialNumber
            OA_rp_CS_MemAbsGet_Get_BsShare_PCBSerialNumber: operation=rp_CS_MemAbsGet.Get_BsShare_PCBSerialNumber
            OA_rp_CS_MemAbsGet_Get_BsShare_SMTManufacturingDate: operation=rp_CS_MemAbsGet.Get_BsShare_SMTManufacturingDate
            OA_rp_CS_MemAbsGet_Get_BsShare_AssemblyManufacturingDate: operation=rp_CS_MemAbsGet.Get_BsShare_AssemblyManufacturingDate
            OA_rp_CS_MemAbsGet_Get_BsShare_SMTPlantNumber: operation=rp_CS_MemAbsGet.Get_BsShare_SMTPlantNumber
            OA_rp_CS_MemAbsGet_Get_BsShare_AssemblyPlantNumber: operation=rp_CS_MemAbsGet.Get_BsShare_AssemblyPlantNumber
            OA_rp_CS_MemAbsGet_Get_BsShare_HWModification: operation=rp_CS_MemAbsGet.Get_BsShare_HWModification
            OA_rp_CS_MemAbsGet_Get_BsShare_VisMeet_Element: operation=rp_CS_MemAbsGet.Get_BsShare_VisMeet_Element
            OA_rp_CS_MemAbsGet_Get_BsShare_VisMeet_EOLEntry_Element: operation=rp_CS_MemAbsGet.Get_BsShare_VisMeet_EOLEntry_Element
            OA_rp_CS_MemAbsGet_Get_BsShare_VehicleConfig_Element: operation=rp_CS_MemAbsGet.Get_BsShare_VehicleConfig_Element
            OA_rp_CS_MemAbsGet_Get_BsConst_SpeedoGauge_Element: operation=rp_CS_MemAbsGet.Get_BsConst_SpeedoGauge_Element
            OA_rp_CS_MemAbsGet_Get_BsConst_TachoGauge_Element: operation=rp_CS_MemAbsGet.Get_BsConst_TachoGauge_Element
            OA_rp_CS_MemAbsGet_Get_BsConst_FuelGauge_Element: operation=rp_CS_MemAbsGet.Get_BsConst_FuelGauge_Element
            OA_rp_CS_MemAbsGet_Get_BsConst_TempGauge_Element: operation=rp_CS_MemAbsGet.Get_BsConst_TempGauge_Element
            OA_rp_CS_MemAbsGet_Get_BsConst_PowerGauge_Element: operation=rp_CS_MemAbsGet.Get_BsConst_PowerGauge_Element
            OA_rp_CS_MemAbsGet_Get_BsConst_OilGauge_Element: operation=rp_CS_MemAbsGet.Get_BsConst_OilGauge_Element
            OA_rp_CS_MemAbsGet_Get_BsConst_TripComputer_Element: operation=rp_CS_MemAbsGet.Get_BsConst_TripComputer_Element
            OA_rp_CS_MemAbsGet_Get_BsConst_Compensation_Line_Slope_m: operation=rp_CS_MemAbsGet.Get_BsConst_Compensation_Line_Slope_m
            OA_rp_CS_MemAbsGet_Get_BsConst_Compensation_Line_Shift_b: operation=rp_CS_MemAbsGet.Get_BsConst_Compensation_Line_Shift_b
            OA_rp_CS_MemAbsGet_Get_BsConst_Lookup_Curve_HotSpot_Coef_X: operation=rp_CS_MemAbsGet.Get_BsConst_Lookup_Curve_HotSpot_Coef_X
            OA_rp_CS_MemAbsGet_Get_BsConst_Lookup_Curve_HotSpot_Coef_Y: operation=rp_CS_MemAbsGet.Get_BsConst_Lookup_Curve_HotSpot_Coef_Y
            OA_rp_CS_MemAbsGet_Get_BsConst_Temp_Threshold_Hysteresis_Derating: operation=rp_CS_MemAbsGet.Get_BsConst_Temp_Threshold_Hysteresis_Derating
            OA_rp_CS_MemAbsGet_Get_BsConst_Derating_Backlight_Disable: operation=rp_CS_MemAbsGet.Get_BsConst_Derating_Backlight_Disable
            OA_rp_CS_MemAbsGet_Get_BsConst_Temperature_Sensor_Conv: operation=rp_CS_MemAbsGet.Get_BsConst_Temperature_Sensor_Conv
            OA_rp_CS_MemAbsGet_Get_BsConst_PCB_Temperature_Sensor_Conv: operation=rp_CS_MemAbsGet.Get_BsConst_PCB_Temperature_Sensor_Conv
            OA_rp_CS_MemAbsGet_Get_BsConst_Display_Illum_Max_Level: operation=rp_CS_MemAbsGet.Get_BsConst_Display_Illum_Max_Level
            OA_rp_CS_MemAbsGet_Get_BsConst_PWM_boost_bypass_duty: operation=rp_CS_MemAbsGet.Get_BsConst_PWM_boost_bypass_duty
            OA_rp_CS_MemAbsGet_Get_BsConst_BsConst_Illumination_ReservedByte: operation=rp_CS_MemAbsGet.Get_BsConst_BsConst_Illumination_ReservedByte
            OA_rp_CS_MemAbsGet_Get_BsConst_Compensation_Line_Slope_m_SafeCopy1: operation=rp_CS_MemAbsGet.Get_BsConst_Compensation_Line_Slope_m_SafeCopy1
            OA_rp_CS_MemAbsGet_Get_BsConst_Compensation_Line_Shift_b_SafeCopy1: operation=rp_CS_MemAbsGet.Get_BsConst_Compensation_Line_Shift_b_SafeCopy1
            OA_rp_CS_MemAbsGet_Get_BsConst_Lookup_Curve_HotSpot_Coef_X_SafeCopy1: operation=rp_CS_MemAbsGet.Get_BsConst_Lookup_Curve_HotSpot_Coef_X_SafeCopy1
            OA_rp_CS_MemAbsGet_Get_BsConst_Lookup_Curve_HotSpot_Coef_Y_SafeCopy1: operation=rp_CS_MemAbsGet.Get_BsConst_Lookup_Curve_HotSpot_Coef_Y_SafeCopy1
            OA_rp_CS_MemAbsGet_Get_BsConst_Temp_Threshold_Hysteresis_Derating_SafeCopy1: operation=rp_CS_MemAbsGet.Get_BsConst_Temp_Threshold_Hysteresis_Derating_SafeCopy1
            OA_rp_CS_MemAbsGet_Get_BsConst_Derating_Backlight_Disable_SafeCopy1: operation=rp_CS_MemAbsGet.Get_BsConst_Derating_Backlight_Disable_SafeCopy1
            OA_rp_CS_MemAbsGet_Get_BsConst_Temperature_Sensor_Conv_SafeCopy1: operation=rp_CS_MemAbsGet.Get_BsConst_Temperature_Sensor_Conv_SafeCopy1
            OA_rp_CS_MemAbsGet_Get_BsConst_PCB_Temperature_Sensor_Conv_SafeCopy1: operation=rp_CS_MemAbsGet.Get_BsConst_PCB_Temperature_Sensor_Conv_SafeCopy1
            OA_rp_CS_MemAbsGet_Get_BsConst_Display_Illum_Max_Level_SafeCopy1: operation=rp_CS_MemAbsGet.Get_BsConst_Display_Illum_Max_Level_SafeCopy1
            OA_rp_CS_MemAbsGet_Get_BsConst_PWM_boost_bypass_duty_SafeCopy1: operation=rp_CS_MemAbsGet.Get_BsConst_PWM_boost_bypass_duty_SafeCopy1
            OA_rp_CS_MemAbsGet_Get_BsConst_BsConst_Illumination_ReservedByte_SafeCopy1: operation=rp_CS_MemAbsGet.Get_BsConst_BsConst_Illumination_ReservedByte_SafeCopy1
            OA_rp_CS_MemAbsGet_Get_BsConst_Compensation_Line_Slope_m_SafeCopy2: operation=rp_CS_MemAbsGet.Get_BsConst_Compensation_Line_Slope_m_SafeCopy2
            OA_rp_CS_MemAbsGet_Get_BsConst_Compensation_Line_Shift_b_SafeCopy2: operation=rp_CS_MemAbsGet.Get_BsConst_Compensation_Line_Shift_b_SafeCopy2
            OA_rp_CS_MemAbsGet_Get_BsConst_Lookup_Curve_HotSpot_Coef_X_SafeCopy2: operation=rp_CS_MemAbsGet.Get_BsConst_Lookup_Curve_HotSpot_Coef_X_SafeCopy2
            OA_rp_CS_MemAbsGet_Get_BsConst_Lookup_Curve_HotSpot_Coef_Y_SafeCopy2: operation=rp_CS_MemAbsGet.Get_BsConst_Lookup_Curve_HotSpot_Coef_Y_SafeCopy2
            OA_rp_CS_MemAbsGet_Get_BsConst_Temp_Threshold_Hysteresis_Derating_SafeCopy2: operation=rp_CS_MemAbsGet.Get_BsConst_Temp_Threshold_Hysteresis_Derating_SafeCopy2
            OA_rp_CS_MemAbsGet_Get_BsConst_Derating_Backlight_Disable_SafeCopy2: operation=rp_CS_MemAbsGet.Get_BsConst_Derating_Backlight_Disable_SafeCopy2
            OA_rp_CS_MemAbsGet_Get_BsConst_Temperature_Sensor_Conv_SafeCopy2: operation=rp_CS_MemAbsGet.Get_BsConst_Temperature_Sensor_Conv_SafeCopy2
            OA_rp_CS_MemAbsGet_Get_BsConst_PCB_Temperature_Sensor_Conv_SafeCopy2: operation=rp_CS_MemAbsGet.Get_BsConst_PCB_Temperature_Sensor_Conv_SafeCopy2
            OA_rp_CS_MemAbsGet_Get_BsConst_Display_Illum_Max_Level_SafeCopy2: operation=rp_CS_MemAbsGet.Get_BsConst_Display_Illum_Max_Level_SafeCopy2
            OA_rp_CS_MemAbsGet_Get_BsConst_PWM_boost_bypass_duty_SafeCopy2: operation=rp_CS_MemAbsGet.Get_BsConst_PWM_boost_bypass_duty_SafeCopy2
            OA_rp_CS_MemAbsGet_Get_BsConst_BsConst_Illumination_ReservedByte_SafeCopy2: operation=rp_CS_MemAbsGet.Get_BsConst_BsConst_Illumination_ReservedByte_SafeCopy2
            OA_rp_CS_MemAbsGet_Get_BsConst_Audio_Element: operation=rp_CS_MemAbsGet.Get_BsConst_Audio_Element
            OA_rp_CS_MemAbsGet_Get_BsConst_Warning_Element: operation=rp_CS_MemAbsGet.Get_BsConst_Warning_Element
            OA_rp_CS_MemAbsGet_Get_BsConst_RealTimeClock_Element: operation=rp_CS_MemAbsGet.Get_BsConst_RealTimeClock_Element
            OA_rp_CS_MemAbsGet_Get_BsConst_Communication_Element: operation=rp_CS_MemAbsGet.Get_BsConst_Communication_Element
            OA_rp_CS_MemAbsGet_Get_BsConst_Power_Element: operation=rp_CS_MemAbsGet.Get_BsConst_Power_Element
            OA_rp_CS_MemAbsGet_Get_BsConst_ServiceReminder_Element: operation=rp_CS_MemAbsGet.Get_BsConst_ServiceReminder_Element
            OA_rp_CS_MemAbsGet_Get_BsConst_EngOffTimer_Element: operation=rp_CS_MemAbsGet.Get_BsConst_EngOffTimer_Element
            OA_rp_CS_MemAbsGet_Get_BsCys_Certicificate_Element: operation=rp_CS_MemAbsGet.Get_BsCys_Certicificate_Element
            OA_rp_CS_MemAbsGet_Get_RefCys_Certicificate_Element: operation=rp_CS_MemAbsGet.Get_RefCys_Certicificate_Element
            OA_rp_CS_MemAbsGet_Get_RefCys_Certicificate1_Element: operation=rp_CS_MemAbsGet.Get_RefCys_Certicificate1_Element
            OA_rp_CS_MemAbsGet_Get_BsRt_Odometer_Element: operation=rp_CS_MemAbsGet.Get_BsRt_Odometer_Element
            OA_rp_CS_MemAbsGet_Get_BsRt_SpeedoGauge_Element: operation=rp_CS_MemAbsGet.Get_BsRt_SpeedoGauge_Element
            OA_rp_CS_MemAbsGet_Get_BsRt_TachoGauge_Element: operation=rp_CS_MemAbsGet.Get_BsRt_TachoGauge_Element
            OA_rp_CS_MemAbsGet_Get_BsRt_FuelGauge_Element: operation=rp_CS_MemAbsGet.Get_BsRt_FuelGauge_Element
            OA_rp_CS_MemAbsGet_Get_BsRt_TempGauge_Element: operation=rp_CS_MemAbsGet.Get_BsRt_TempGauge_Element
            OA_rp_CS_MemAbsGet_Get_BsRt_PowerGauge_Element: operation=rp_CS_MemAbsGet.Get_BsRt_PowerGauge_Element
            OA_rp_CS_MemAbsGet_Get_BsRt_OilGauge_Element: operation=rp_CS_MemAbsGet.Get_BsRt_OilGauge_Element
            OA_rp_CS_MemAbsGet_Get_BsRt_TripComputer_Element: operation=rp_CS_MemAbsGet.Get_BsRt_TripComputer_Element
            OA_rp_CS_MemAbsGet_Get_BsRt_Warning_Element: operation=rp_CS_MemAbsGet.Get_BsRt_Warning_Element
            OA_rp_CS_MemAbsGet_Get_BsRt_RealTimeClock_Element: operation=rp_CS_MemAbsGet.Get_BsRt_RealTimeClock_Element
            OA_rp_CS_MemAbsGet_Get_BsRt_Personalization_Element: operation=rp_CS_MemAbsGet.Get_BsRt_Personalization_Element
            OA_rp_CS_MemAbsGet_Get_BsRt_Illumination_Element: operation=rp_CS_MemAbsGet.Get_BsRt_Illumination_Element
            OA_rp_CS_MemAbsGet_Get_BsRt_CusDlt_Element: operation=rp_CS_MemAbsGet.Get_BsRt_CusDlt_Element
            OA_rp_CS_MemAbsGet_Get_BsReten_Odometer_Element: operation=rp_CS_MemAbsGet.Get_BsReten_Odometer_Element
            OA_rp_CS_MemAbsGet_Get_BsReten_Gauges_Element: operation=rp_CS_MemAbsGet.Get_BsReten_Gauges_Element
            OA_rp_CS_MemAbsGet_Get_BsReten_Tripcomputer_Element: operation=rp_CS_MemAbsGet.Get_BsReten_Tripcomputer_Element
            OA_rp_CS_MemAbsGet_Get_BsReten_Illumination_Element: operation=rp_CS_MemAbsGet.Get_BsReten_Illumination_Element
            OA_rp_CS_MemAbsGet_Get_BsReten_Audio_Element: operation=rp_CS_MemAbsGet.Get_BsReten_Audio_Element
            OA_rp_CS_MemAbsGet_Get_BsReten_Warning_Element: operation=rp_CS_MemAbsGet.Get_BsReten_Warning_Element
            OA_rp_CS_MemAbsGet_Get_BsReten_RealTimeClock_Element: operation=rp_CS_MemAbsGet.Get_BsReten_RealTimeClock_Element
            OA_rp_CS_MemAbsGet_Get_BsReten_Communication_Element: operation=rp_CS_MemAbsGet.Get_BsReten_Communication_Element
            OA_rp_CS_MemAbsGet_Get_BsReten_Personalization_Element: operation=rp_CS_MemAbsGet.Get_BsReten_Personalization_Element
            OA_rp_CS_MemAbsGet_Get_BsReten_VisDlt_Element: operation=rp_CS_MemAbsGet.Get_BsReten_VisDlt_Element
            OA_rp_CS_MemAbsGet_Get_BsReten_Power_Element: operation=rp_CS_MemAbsGet.Get_BsReten_Power_Element
            OA_rp_CS_MemAbsGet_Get_BsReten_Display_Element: operation=rp_CS_MemAbsGet.Get_BsReten_Display_Element
            OA_rp_CS_MemAbsGet_Get_BsDiag_ErrorRecord_Element: operation=rp_CS_MemAbsGet.Get_BsDiag_ErrorRecord_Element
            OA_rp_CS_MemAbsGet_Get_BsDiag_Dtc_Element: operation=rp_CS_MemAbsGet.Get_BsDiag_Dtc_Element
            OA_rp_CS_MemAbsSet_Set_BsShare_SwUpdReflash_Element: operation=rp_CS_MemAbsSet.Set_BsShare_SwUpdReflash_Element
            OA_rp_CS_MemAbsSet_Set_BsShare_SwUpdFotaMode_Element: operation=rp_CS_MemAbsSet.Set_BsShare_SwUpdFotaMode_Element
            OA_rp_CS_MemAbsSet_Set_BsShare_SwUpdFotaFinPrint_Element: operation=rp_CS_MemAbsSet.Set_BsShare_SwUpdFotaFinPrint_Element
            OA_rp_CS_MemAbsSet_Set_BsShare_SwUpdFotaStatus_Element: operation=rp_CS_MemAbsSet.Set_BsShare_SwUpdFotaStatus_Element
            OA_rp_CS_MemAbsSet_Set_BsShare_SwUpdFotadecrypt_Element: operation=rp_CS_MemAbsSet.Set_BsShare_SwUpdFotadecrypt_Element
            OA_rp_CS_MemAbsSet_Set_BsShare_EcuPartNumber_Element: operation=rp_CS_MemAbsSet.Set_BsShare_EcuPartNumber_Element
            OA_rp_CS_MemAbsSet_Set_BsShare_VisteonPartNumber: operation=rp_CS_MemAbsSet.Set_BsShare_VisteonPartNumber
            OA_rp_CS_MemAbsSet_Set_BsShare_VisteonPCBPartNumber: operation=rp_CS_MemAbsSet.Set_BsShare_VisteonPCBPartNumber
            OA_rp_CS_MemAbsSet_Set_BsShare_ProductSerialNumber: operation=rp_CS_MemAbsSet.Set_BsShare_ProductSerialNumber
            OA_rp_CS_MemAbsSet_Set_BsShare_PCBSerialNumber: operation=rp_CS_MemAbsSet.Set_BsShare_PCBSerialNumber
            OA_rp_CS_MemAbsSet_Set_BsShare_SMTManufacturingDate: operation=rp_CS_MemAbsSet.Set_BsShare_SMTManufacturingDate
            OA_rp_CS_MemAbsSet_Set_BsShare_AssemblyManufacturingDate: operation=rp_CS_MemAbsSet.Set_BsShare_AssemblyManufacturingDate
            OA_rp_CS_MemAbsSet_Set_BsShare_SMTPlantNumber: operation=rp_CS_MemAbsSet.Set_BsShare_SMTPlantNumber
            OA_rp_CS_MemAbsSet_Set_BsShare_AssemblyPlantNumber: operation=rp_CS_MemAbsSet.Set_BsShare_AssemblyPlantNumber
            OA_rp_CS_MemAbsSet_Set_BsShare_HWModification: operation=rp_CS_MemAbsSet.Set_BsShare_HWModification
            OA_rp_CS_MemAbsSet_Set_BsShare_VisMeet_Element: operation=rp_CS_MemAbsSet.Set_BsShare_VisMeet_Element
            OA_rp_CS_MemAbsSet_Set_BsShare_VisMeet_EOLEntry_Element: operation=rp_CS_MemAbsSet.Set_BsShare_VisMeet_EOLEntry_Element
            OA_rp_CS_MemAbsSet_Set_BsShare_VehicleConfig_Element: operation=rp_CS_MemAbsSet.Set_BsShare_VehicleConfig_Element
            OA_rp_CS_MemAbsSet_Set_BsConst_SpeedoGauge_Element: operation=rp_CS_MemAbsSet.Set_BsConst_SpeedoGauge_Element
            OA_rp_CS_MemAbsSet_Set_BsConst_TachoGauge_Element: operation=rp_CS_MemAbsSet.Set_BsConst_TachoGauge_Element
            OA_rp_CS_MemAbsSet_Set_BsConst_FuelGauge_Element: operation=rp_CS_MemAbsSet.Set_BsConst_FuelGauge_Element
            OA_rp_CS_MemAbsSet_Set_BsConst_TempGauge_Element: operation=rp_CS_MemAbsSet.Set_BsConst_TempGauge_Element
            OA_rp_CS_MemAbsSet_Set_BsConst_PowerGauge_Element: operation=rp_CS_MemAbsSet.Set_BsConst_PowerGauge_Element
            OA_rp_CS_MemAbsSet_Set_BsConst_OilGauge_Element: operation=rp_CS_MemAbsSet.Set_BsConst_OilGauge_Element
            OA_rp_CS_MemAbsSet_Set_BsConst_TripComputer_Element: operation=rp_CS_MemAbsSet.Set_BsConst_TripComputer_Element
            OA_rp_CS_MemAbsSet_Set_BsConst_Compensation_Line_Slope_m: operation=rp_CS_MemAbsSet.Set_BsConst_Compensation_Line_Slope_m
            OA_rp_CS_MemAbsSet_Set_BsConst_Compensation_Line_Shift_b: operation=rp_CS_MemAbsSet.Set_BsConst_Compensation_Line_Shift_b
            OA_rp_CS_MemAbsSet_Set_BsConst_Lookup_Curve_HotSpot_Coef_X: operation=rp_CS_MemAbsSet.Set_BsConst_Lookup_Curve_HotSpot_Coef_X
            OA_rp_CS_MemAbsSet_Set_BsConst_Lookup_Curve_HotSpot_Coef_Y: operation=rp_CS_MemAbsSet.Set_BsConst_Lookup_Curve_HotSpot_Coef_Y
            OA_rp_CS_MemAbsSet_Set_BsConst_Temp_Threshold_Hysteresis_Derating: operation=rp_CS_MemAbsSet.Set_BsConst_Temp_Threshold_Hysteresis_Derating
            OA_rp_CS_MemAbsSet_Set_BsConst_Derating_Backlight_Disable: operation=rp_CS_MemAbsSet.Set_BsConst_Derating_Backlight_Disable
            OA_rp_CS_MemAbsSet_Set_BsConst_Temperature_Sensor_Conv: operation=rp_CS_MemAbsSet.Set_BsConst_Temperature_Sensor_Conv
            OA_rp_CS_MemAbsSet_Set_BsConst_PCB_Temperature_Sensor_Conv: operation=rp_CS_MemAbsSet.Set_BsConst_PCB_Temperature_Sensor_Conv
            OA_rp_CS_MemAbsSet_Set_BsConst_Display_Illum_Max_Level: operation=rp_CS_MemAbsSet.Set_BsConst_Display_Illum_Max_Level
            OA_rp_CS_MemAbsSet_Set_BsConst_PWM_boost_bypass_duty: operation=rp_CS_MemAbsSet.Set_BsConst_PWM_boost_bypass_duty
            OA_rp_CS_MemAbsSet_Set_BsConst_BsConst_Illumination_ReservedByte: operation=rp_CS_MemAbsSet.Set_BsConst_BsConst_Illumination_ReservedByte
            OA_rp_CS_MemAbsSet_Set_BsConst_Compensation_Line_Slope_m_SafeCopy1: operation=rp_CS_MemAbsSet.Set_BsConst_Compensation_Line_Slope_m_SafeCopy1
            OA_rp_CS_MemAbsSet_Set_BsConst_Compensation_Line_Shift_b_SafeCopy1: operation=rp_CS_MemAbsSet.Set_BsConst_Compensation_Line_Shift_b_SafeCopy1
            OA_rp_CS_MemAbsSet_Set_BsConst_Lookup_Curve_HotSpot_Coef_X_SafeCopy1: operation=rp_CS_MemAbsSet.Set_BsConst_Lookup_Curve_HotSpot_Coef_X_SafeCopy1
            OA_rp_CS_MemAbsSet_Set_BsConst_Lookup_Curve_HotSpot_Coef_Y_SafeCopy1: operation=rp_CS_MemAbsSet.Set_BsConst_Lookup_Curve_HotSpot_Coef_Y_SafeCopy1
            OA_rp_CS_MemAbsSet_Set_BsConst_Temp_Threshold_Hysteresis_Derating_SafeCopy1: operation=rp_CS_MemAbsSet.Set_BsConst_Temp_Threshold_Hysteresis_Derating_SafeCopy1
            OA_rp_CS_MemAbsSet_Set_BsConst_Derating_Backlight_Disable_SafeCopy1: operation=rp_CS_MemAbsSet.Set_BsConst_Derating_Backlight_Disable_SafeCopy1
            OA_rp_CS_MemAbsSet_Set_BsConst_Temperature_Sensor_Conv_SafeCopy1: operation=rp_CS_MemAbsSet.Set_BsConst_Temperature_Sensor_Conv_SafeCopy1
            OA_rp_CS_MemAbsSet_Set_BsConst_PCB_Temperature_Sensor_Conv_SafeCopy1: operation=rp_CS_MemAbsSet.Set_BsConst_PCB_Temperature_Sensor_Conv_SafeCopy1
            OA_rp_CS_MemAbsSet_Set_BsConst_Display_Illum_Max_Level_SafeCopy1: operation=rp_CS_MemAbsSet.Set_BsConst_Display_Illum_Max_Level_SafeCopy1
            OA_rp_CS_MemAbsSet_Set_BsConst_PWM_boost_bypass_duty_SafeCopy1: operation=rp_CS_MemAbsSet.Set_BsConst_PWM_boost_bypass_duty_SafeCopy1
            OA_rp_CS_MemAbsSet_Set_BsConst_BsConst_Illumination_ReservedByte_SafeCopy1: operation=rp_CS_MemAbsSet.Set_BsConst_BsConst_Illumination_ReservedByte_SafeCopy1
            OA_rp_CS_MemAbsSet_Set_BsConst_Compensation_Line_Slope_m_SafeCopy2: operation=rp_CS_MemAbsSet.Set_BsConst_Compensation_Line_Slope_m_SafeCopy2
            OA_rp_CS_MemAbsSet_Set_BsConst_Compensation_Line_Shift_b_SafeCopy2: operation=rp_CS_MemAbsSet.Set_BsConst_Compensation_Line_Shift_b_SafeCopy2
            OA_rp_CS_MemAbsSet_Set_BsConst_Lookup_Curve_HotSpot_Coef_X_SafeCopy2: operation=rp_CS_MemAbsSet.Set_BsConst_Lookup_Curve_HotSpot_Coef_X_SafeCopy2
            OA_rp_CS_MemAbsSet_Set_BsConst_Lookup_Curve_HotSpot_Coef_Y_SafeCopy2: operation=rp_CS_MemAbsSet.Set_BsConst_Lookup_Curve_HotSpot_Coef_Y_SafeCopy2
            OA_rp_CS_MemAbsSet_Set_BsConst_Temp_Threshold_Hysteresis_Derating_SafeCopy2: operation=rp_CS_MemAbsSet.Set_BsConst_Temp_Threshold_Hysteresis_Derating_SafeCopy2
            OA_rp_CS_MemAbsSet_Set_BsConst_Derating_Backlight_Disable_SafeCopy2: operation=rp_CS_MemAbsSet.Set_BsConst_Derating_Backlight_Disable_SafeCopy2
            OA_rp_CS_MemAbsSet_Set_BsConst_Temperature_Sensor_Conv_SafeCopy2: operation=rp_CS_MemAbsSet.Set_BsConst_Temperature_Sensor_Conv_SafeCopy2
            OA_rp_CS_MemAbsSet_Set_BsConst_PCB_Temperature_Sensor_Conv_SafeCopy2: operation=rp_CS_MemAbsSet.Set_BsConst_PCB_Temperature_Sensor_Conv_SafeCopy2
            OA_rp_CS_MemAbsSet_Set_BsConst_Display_Illum_Max_Level_SafeCopy2: operation=rp_CS_MemAbsSet.Set_BsConst_Display_Illum_Max_Level_SafeCopy2
            OA_rp_CS_MemAbsSet_Set_BsConst_PWM_boost_bypass_duty_SafeCopy2: operation=rp_CS_MemAbsSet.Set_BsConst_PWM_boost_bypass_duty_SafeCopy2
            OA_rp_CS_MemAbsSet_Set_BsConst_BsConst_Illumination_ReservedByte_SafeCopy2: operation=rp_CS_MemAbsSet.Set_BsConst_BsConst_Illumination_ReservedByte_SafeCopy2
            OA_rp_CS_MemAbsSet_Set_BsConst_Audio_Element: operation=rp_CS_MemAbsSet.Set_BsConst_Audio_Element
            OA_rp_CS_MemAbsSet_Set_BsConst_Warning_Element: operation=rp_CS_MemAbsSet.Set_BsConst_Warning_Element
            OA_rp_CS_MemAbsSet_Set_BsConst_RealTimeClock_Element: operation=rp_CS_MemAbsSet.Set_BsConst_RealTimeClock_Element
            OA_rp_CS_MemAbsSet_Set_BsConst_Communication_Element: operation=rp_CS_MemAbsSet.Set_BsConst_Communication_Element
            OA_rp_CS_MemAbsSet_Set_BsConst_Power_Element: operation=rp_CS_MemAbsSet.Set_BsConst_Power_Element
            OA_rp_CS_MemAbsSet_Set_BsConst_ServiceReminder_Element: operation=rp_CS_MemAbsSet.Set_BsConst_ServiceReminder_Element
            OA_rp_CS_MemAbsSet_Set_BsConst_EngOffTimer_Element: operation=rp_CS_MemAbsSet.Set_BsConst_EngOffTimer_Element
            OA_rp_CS_MemAbsSet_Set_BsCys_Certicificate_Element: operation=rp_CS_MemAbsSet.Set_BsCys_Certicificate_Element
            OA_rp_CS_MemAbsSet_Set_RefCys_Certicificate_Element: operation=rp_CS_MemAbsSet.Set_RefCys_Certicificate_Element
            OA_rp_CS_MemAbsSet_Set_RefCys_Certicificate1_Element: operation=rp_CS_MemAbsSet.Set_RefCys_Certicificate1_Element
            OA_rp_CS_MemAbsSet_Set_BsRt_Odometer_Element: operation=rp_CS_MemAbsSet.Set_BsRt_Odometer_Element
            OA_rp_CS_MemAbsSet_Set_BsRt_SpeedoGauge_Element: operation=rp_CS_MemAbsSet.Set_BsRt_SpeedoGauge_Element
            OA_rp_CS_MemAbsSet_Set_BsRt_TachoGauge_Element: operation=rp_CS_MemAbsSet.Set_BsRt_TachoGauge_Element
            OA_rp_CS_MemAbsSet_Set_BsRt_FuelGauge_Element: operation=rp_CS_MemAbsSet.Set_BsRt_FuelGauge_Element
            OA_rp_CS_MemAbsSet_Set_BsRt_TempGauge_Element: operation=rp_CS_MemAbsSet.Set_BsRt_TempGauge_Element
            OA_rp_CS_MemAbsSet_Set_BsRt_PowerGauge_Element: operation=rp_CS_MemAbsSet.Set_BsRt_PowerGauge_Element
            OA_rp_CS_MemAbsSet_Set_BsRt_OilGauge_Element: operation=rp_CS_MemAbsSet.Set_BsRt_OilGauge_Element
            OA_rp_CS_MemAbsSet_Set_BsRt_TripComputer_Element: operation=rp_CS_MemAbsSet.Set_BsRt_TripComputer_Element
            OA_rp_CS_MemAbsSet_Set_BsRt_Warning_Element: operation=rp_CS_MemAbsSet.Set_BsRt_Warning_Element
            OA_rp_CS_MemAbsSet_Set_BsRt_RealTimeClock_Element: operation=rp_CS_MemAbsSet.Set_BsRt_RealTimeClock_Element
            OA_rp_CS_MemAbsSet_Set_BsRt_Personalization_Element: operation=rp_CS_MemAbsSet.Set_BsRt_Personalization_Element
            OA_rp_CS_MemAbsSet_Set_BsRt_Illumination_Element: operation=rp_CS_MemAbsSet.Set_BsRt_Illumination_Element
            OA_rp_CS_MemAbsSet_Set_BsRt_CusDlt_Element: operation=rp_CS_MemAbsSet.Set_BsRt_CusDlt_Element
            OA_rp_CS_MemAbsSet_Set_BsReten_Odometer_Element: operation=rp_CS_MemAbsSet.Set_BsReten_Odometer_Element
            OA_rp_CS_MemAbsSet_Set_BsReten_Gauges_Element: operation=rp_CS_MemAbsSet.Set_BsReten_Gauges_Element
            OA_rp_CS_MemAbsSet_Set_BsReten_Tripcomputer_Element: operation=rp_CS_MemAbsSet.Set_BsReten_Tripcomputer_Element
            OA_rp_CS_MemAbsSet_Set_BsReten_Illumination_Element: operation=rp_CS_MemAbsSet.Set_BsReten_Illumination_Element
            OA_rp_CS_MemAbsSet_Set_BsReten_Audio_Element: operation=rp_CS_MemAbsSet.Set_BsReten_Audio_Element
            OA_rp_CS_MemAbsSet_Set_BsReten_Warning_Element: operation=rp_CS_MemAbsSet.Set_BsReten_Warning_Element
            OA_rp_CS_MemAbsSet_Set_BsReten_RealTimeClock_Element: operation=rp_CS_MemAbsSet.Set_BsReten_RealTimeClock_Element
            OA_rp_CS_MemAbsSet_Set_BsReten_Communication_Element: operation=rp_CS_MemAbsSet.Set_BsReten_Communication_Element
            OA_rp_CS_MemAbsSet_Set_BsReten_Personalization_Element: operation=rp_CS_MemAbsSet.Set_BsReten_Personalization_Element
            OA_rp_CS_MemAbsSet_Set_BsReten_VisDlt_Element: operation=rp_CS_MemAbsSet.Set_BsReten_VisDlt_Element
            OA_rp_CS_MemAbsSet_Set_BsReten_Power_Element: operation=rp_CS_MemAbsSet.Set_BsReten_Power_Element
            OA_rp_CS_MemAbsSet_Set_BsReten_Display_Element: operation=rp_CS_MemAbsSet.Set_BsReten_Display_Element
            OA_rp_CS_MemAbsSet_Set_BsDiag_ErrorRecord_Element: operation=rp_CS_MemAbsSet.Set_BsDiag_ErrorRecord_Element
            OA_rp_CS_MemAbsSet_Set_BsDiag_Dtc_Element: operation=rp_CS_MemAbsSet.Set_BsDiag_Dtc_Element
            OA_rp_CS_MemAbs_NvMWriteStatus_NvmWriteStatus: operation=rp_CS_MemAbs_NvMWriteStatus.NvmWriteStatus
        DltExt_SendLogMessage
        DltExt_SetCounterToDefault
        DltExt_SetLogsToDefault
  swc implementation IMPL_DltExt: programming-language=C, behavior=IB_DltExt
    code-descriptors:
      code CodeDescriptor
  application sw component type ComCallout
    provide port ppSR_E2EStatus: nonqueued-sender-com-spec{data-element=ABS0x102_Status, uses-end-to-end-protection=0, init-value=constant-reference=ComCalloutABS0x102_StatusValue0}, provided-interface=TI_ppSR_ComCallout
    behavior IB_ComCallout: port-api-option{enable-take-address=false, indirect-api=false, port=ppSR_E2EStatus}
      timing event TEComCallout_Impl_MainFunction: start-on-event=ComCallout_Impl_MainFunction, period=0.01
      runnable ComCallout_Impl_MainFunction: can-be-invoked-concurrently=true
        data-send-points:
          access DWA_ppSR_E2EStatus_ABS0x102_Status: accessed-variable=ppSR_E2EStatus.ABS0x102_Status
  constant specification ComCalloutABS0x102_StatusValue0: value-spec=ComCalloutABS0x102_StatusValue0:false
  swc implementation IMPL_ComCallout: programming-language=C, behavior=IB_ComCallout
    code-descriptors:
      code CodeDescriptor
  application sw component type DcmExt
    9 x provide port:
      pp_CS_DcmExt_Confirmation: server-com-spec{operation=DcmExt_Confirmation, queue-length=1}, provided-interface=TI_DcmExt_Confirmation
      pp_CS_DcmExt_Service_Iocontrol: server-com-spec{operation=DcmExt_Service_Iocontrol, queue-length=1}, provided-interface=TI_DcmExt_Service_Iocontrol
      pp_CS_DcmExt_Services_CndChk: server-com-spec{operation=DcmExt_Services_CndChk, queue-length=1}, provided-interface=TI_DcmExt_Services_CndChk
      pp_CS_DcmExt_Services_DataRead: server-com-spec{operation=DcmExt_Services_DataRead, queue-length=1}, provided-interface=TI_DcmExt_Services_DataRead
      pp_CS_DcmExt_Services_DataWrite: server-com-spec{operation=DcmExt_Services_DataWrite, queue-length=1}, provided-interface=TI_DcmExt_Services_DataWrite
      pp_CS_DcmExt_Services_LenChk: server-com-spec{operation=DcmExt_Services_LenChk, queue-length=1}, provided-interface=TI_DcmExt_Services_LenChk
      pp_CS_DcmExt_Services_RoutineResults: server-com-spec{operation=DcmExt_Services_RoutineResults, queue-length=1}, provided-interface=TI_DcmExt_Services_RoutineResults
      pp_CS_DcmExt_Services_RoutineStart: server-com-spec{operation=DcmExt_Services_RoutineStart, queue-length=1}, provided-interface=TI_DcmExt_Services_RoutineStart
      pp_CS_DcmExt_Services_RoutineStop: server-com-spec{operation=DcmExt_Services_RoutineStop, queue-length=1}, provided-interface=TI_DcmExt_Services_RoutineStop
    13 x require port:
      rp_CS_DID_App_DiagAction: required-interface=TI_DID_App_Diag_Action
      rp_CS_DID_DiagAction: required-interface=TI_DID_DiagAction
      rp_CS_DiagEntryStatus: required-interface=TI_DiagEntrySts
      rp_CS_MemAbsGet: required-interface=if_CS_MemAbsGet
      rp_CS_MemAbsSet: required-interface=if_CS_MemAbsSet
      rp_CS_RID_App_DiagAction: required-interface=TI_RID_App_Diag_Action
      rp_CS_RID_DiagAction: required-interface=TI_RID_DiagAction
      rp_CS_UpdateCdd_DID_DiagAction: required-interface=TI_UpdateCdd_GenericDIDRequestHandler
      rp_CS_UpdateCdd_RID_DiagAction: required-interface=TI_UpdateCdd_GenericRIDRequestHandler
      rp_CS_UpdateCdd_Service_0x34_Handler: required-interface=TI_UpdateCdd_GenericDownloadRequestHandler
      rp_CS_UpdateCdd_Service_0x36_Handler: required-interface=TI_UpdateCdd_GenericTransferDataHandler
      rp_CS_UpdateCdd_Service_0x37_Handler: required-interface=TI_UpdateCdd_GenericTransferExitHandler
      rp_SR_JobStatus: required-interface=if_SR_JobStatus
        required-com-specs:
          data-element=JobStatus_BsConst_Audio_Element, init-value=constant-reference=DcmExtJobStatus_BsConst_Audio_ElementValue0
          data-element=JobStatus_BsConst_BsConst_Illumination_ReservedByte, init-value=constant-reference=DcmExtJobStatus_BsConst_BsConst_Illumination_ReservedByteValue0
          data-element=JobStatus_BsConst_BsConst_Illumination_ReservedByte_SafeCopy1, init-value=constant-reference=DcmExtJobStatus_BsConst_BsConst_Illumination_ReservedByte_SafeCopy1Value0
          data-element=JobStatus_BsConst_BsConst_Illumination_ReservedByte_SafeCopy2, init-value=constant-reference=DcmExtJobStatus_BsConst_BsConst_Illumination_ReservedByte_SafeCopy2Value0
          data-element=JobStatus_BsConst_Communication_Element, init-value=constant-reference=DcmExtJobStatus_BsConst_Communication_ElementValue0
          data-element=JobStatus_BsConst_Compensation_Line_Shift_b, init-value=constant-reference=DcmExtJobStatus_BsConst_Compensation_Line_Shift_bValue0
          data-element=JobStatus_BsConst_Compensation_Line_Shift_b_SafeCopy1, init-value=constant-reference=DcmExtJobStatus_BsConst_Compensation_Line_Shift_b_SafeCopy1Value0
          data-element=JobStatus_BsConst_Compensation_Line_Shift_b_SafeCopy2, init-value=constant-reference=DcmExtJobStatus_BsConst_Compensation_Line_Shift_b_SafeCopy2Value0
          data-element=JobStatus_BsConst_Compensation_Line_Slope_m, init-value=constant-reference=DcmExtJobStatus_BsConst_Compensation_Line_Slope_mValue0
          data-element=JobStatus_BsConst_Compensation_Line_Slope_m_SafeCopy1, init-value=constant-reference=DcmExtJobStatus_BsConst_Compensation_Line_Slope_m_SafeCopy1Value0
          data-element=JobStatus_BsConst_Compensation_Line_Slope_m_SafeCopy2, init-value=constant-reference=DcmExtJobStatus_BsConst_Compensation_Line_Slope_m_SafeCopy2Value0
          data-element=JobStatus_BsConst_Derating_Backlight_Disable, init-value=constant-reference=DcmExtJobStatus_BsConst_Derating_Backlight_DisableValue0
          data-element=JobStatus_BsConst_Derating_Backlight_Disable_SafeCopy1, init-value=constant-reference=DcmExtJobStatus_BsConst_Derating_Backlight_Disable_SafeCopy1Value0
          data-element=JobStatus_BsConst_Derating_Backlight_Disable_SafeCopy2, init-value=constant-reference=DcmExtJobStatus_BsConst_Derating_Backlight_Disable_SafeCopy2Value0
          data-element=JobStatus_BsConst_Display_Illum_Max_Level, init-value=constant-reference=DcmExtJobStatus_BsConst_Display_Illum_Max_LevelValue0
          data-element=JobStatus_BsConst_Display_Illum_Max_Level_SafeCopy1, init-value=constant-reference=DcmExtJobStatus_BsConst_Display_Illum_Max_Level_SafeCopy1Value0
          data-element=JobStatus_BsConst_Display_Illum_Max_Level_SafeCopy2, init-value=constant-reference=DcmExtJobStatus_BsConst_Display_Illum_Max_Level_SafeCopy2Value0
          data-element=JobStatus_BsConst_EngOffTimer_Element, init-value=constant-reference=DcmExtJobStatus_BsConst_EngOffTimer_ElementValue0
          data-element=JobStatus_BsConst_FuelGauge_Element, init-value=constant-reference=DcmExtJobStatus_BsConst_FuelGauge_ElementValue0
          data-element=JobStatus_BsConst_Lookup_Curve_HotSpot_Coef_X, init-value=constant-reference=DcmExtJobStatus_BsConst_Lookup_Curve_HotSpot_Coef_XValue0
          data-element=JobStatus_BsConst_Lookup_Curve_HotSpot_Coef_X_SafeCopy1, init-value=constant-reference=DcmExtJobStatus_BsConst_Lookup_Curve_HotSpot_Coef_X_SafeCopy1Value0
          data-element=JobStatus_BsConst_Lookup_Curve_HotSpot_Coef_X_SafeCopy2, init-value=constant-reference=DcmExtJobStatus_BsConst_Lookup_Curve_HotSpot_Coef_X_SafeCopy2Value0
          data-element=JobStatus_BsConst_Lookup_Curve_HotSpot_Coef_Y, init-value=constant-reference=DcmExtJobStatus_BsConst_Lookup_Curve_HotSpot_Coef_YValue0
          data-element=JobStatus_BsConst_Lookup_Curve_HotSpot_Coef_Y_SafeCopy1, init-value=constant-reference=DcmExtJobStatus_BsConst_Lookup_Curve_HotSpot_Coef_Y_SafeCopy1Value0
          data-element=JobStatus_BsConst_Lookup_Curve_HotSpot_Coef_Y_SafeCopy2, init-value=constant-reference=DcmExtJobStatus_BsConst_Lookup_Curve_HotSpot_Coef_Y_SafeCopy2Value0
          data-element=JobStatus_BsConst_OilGauge_Element, init-value=constant-reference=DcmExtJobStatus_BsConst_OilGauge_ElementValue0
          data-element=JobStatus_BsConst_PCB_Temperature_Sensor_Conv, init-value=constant-reference=DcmExtJobStatus_BsConst_PCB_Temperature_Sensor_ConvValue0
          data-element=JobStatus_BsConst_PCB_Temperature_Sensor_Conv_SafeCopy1, init-value=constant-reference=DcmExtJobStatus_BsConst_PCB_Temperature_Sensor_Conv_SafeCopy1Value0
          data-element=JobStatus_BsConst_PCB_Temperature_Sensor_Conv_SafeCopy2, init-value=constant-reference=DcmExtJobStatus_BsConst_PCB_Temperature_Sensor_Conv_SafeCopy2Value0
          data-element=JobStatus_BsConst_PWM_boost_bypass_duty, init-value=constant-reference=DcmExtJobStatus_BsConst_PWM_boost_bypass_dutyValue0
          data-element=JobStatus_BsConst_PWM_boost_bypass_duty_SafeCopy1, init-value=constant-reference=DcmExtJobStatus_BsConst_PWM_boost_bypass_duty_SafeCopy1Value0
          data-element=JobStatus_BsConst_PWM_boost_bypass_duty_SafeCopy2, init-value=constant-reference=DcmExtJobStatus_BsConst_PWM_boost_bypass_duty_SafeCopy2Value0
          data-element=JobStatus_BsConst_PowerGauge_Element, init-value=constant-reference=DcmExtJobStatus_BsConst_PowerGauge_ElementValue0
          data-element=JobStatus_BsConst_Power_Element, init-value=constant-reference=DcmExtJobStatus_BsConst_Power_ElementValue0
          data-element=JobStatus_BsConst_RealTimeClock_Element, init-value=constant-reference=DcmExtJobStatus_BsConst_RealTimeClock_ElementValue0
          data-element=JobStatus_BsConst_ServiceReminder_Element, init-value=constant-reference=DcmExtJobStatus_BsConst_ServiceReminder_ElementValue0
          data-element=JobStatus_BsConst_SpeedoGauge_Element, init-value=constant-reference=DcmExtJobStatus_BsConst_SpeedoGauge_ElementValue0
          data-element=JobStatus_BsConst_TachoGauge_Element, init-value=constant-reference=DcmExtJobStatus_BsConst_TachoGauge_ElementValue0
          data-element=JobStatus_BsConst_TempGauge_Element, init-value=constant-reference=DcmExtJobStatus_BsConst_TempGauge_ElementValue0
          data-element=JobStatus_BsConst_Temp_Threshold_Hysteresis_Derating, init-value=constant-reference=DcmExtJobStatus_BsConst_Temp_Threshold_Hysteresis_DeratingValue0
          data-element=JobStatus_BsConst_Temp_Threshold_Hysteresis_Derating_SafeCopy1, init-value=constant-reference=DcmExtJobStatus_BsConst_Temp_Threshold_Hysteresis_Derating_SafeCopy1Value0
          data-element=JobStatus_BsConst_Temp_Threshold_Hysteresis_Derating_SafeCopy2, init-value=constant-reference=DcmExtJobStatus_BsConst_Temp_Threshold_Hysteresis_Derating_SafeCopy2Value0
          data-element=JobStatus_BsConst_Temperature_Sensor_Conv, init-value=constant-reference=DcmExtJobStatus_BsConst_Temperature_Sensor_ConvValue0
          data-element=JobStatus_BsConst_Temperature_Sensor_Conv_SafeCopy1, init-value=constant-reference=DcmExtJobStatus_BsConst_Temperature_Sensor_Conv_SafeCopy1Value0
          data-element=JobStatus_BsConst_Temperature_Sensor_Conv_SafeCopy2, init-value=constant-reference=DcmExtJobStatus_BsConst_Temperature_Sensor_Conv_SafeCopy2Value0
          data-element=JobStatus_BsConst_TripComputer_Element, init-value=constant-reference=DcmExtJobStatus_BsConst_TripComputer_ElementValue0
          data-element=JobStatus_BsConst_Warning_Element, init-value=constant-reference=DcmExtJobStatus_BsConst_Warning_ElementValue0
          data-element=JobStatus_BsCys_Certicificate_Element, init-value=constant-reference=DcmExtJobStatus_BsCys_Certicificate_ElementValue0
          data-element=JobStatus_BsDiag_Dtc_Element, init-value=constant-reference=DcmExtJobStatus_BsDiag_Dtc_ElementValue0
          data-element=JobStatus_BsDiag_ErrorRecord_Element, init-value=constant-reference=DcmExtJobStatus_BsDiag_ErrorRecord_ElementValue0
          data-element=JobStatus_BsReten_Audio_Element, init-value=constant-reference=DcmExtJobStatus_BsReten_Audio_ElementValue0
          data-element=JobStatus_BsReten_Communication_Element, init-value=constant-reference=DcmExtJobStatus_BsReten_Communication_ElementValue0
          data-element=JobStatus_BsReten_Display_Element, init-value=constant-reference=DcmExtJobStatus_BsReten_Display_ElementValue0
          data-element=JobStatus_BsReten_Gauges_Element, init-value=constant-reference=DcmExtJobStatus_BsReten_Gauges_ElementValue0
          data-element=JobStatus_BsReten_Illumination_Element, init-value=constant-reference=DcmExtJobStatus_BsReten_Illumination_ElementValue0
          data-element=JobStatus_BsReten_Odometer_Element, init-value=constant-reference=DcmExtJobStatus_BsReten_Odometer_ElementValue0
          data-element=JobStatus_BsReten_Personalization_Element, init-value=constant-reference=DcmExtJobStatus_BsReten_Personalization_ElementValue0
          data-element=JobStatus_BsReten_Power_Element, init-value=constant-reference=DcmExtJobStatus_BsReten_Power_ElementValue0
          data-element=JobStatus_BsReten_RealTimeClock_Element, init-value=constant-reference=DcmExtJobStatus_BsReten_RealTimeClock_ElementValue0
          data-element=JobStatus_BsReten_Tripcomputer_Element, init-value=constant-reference=DcmExtJobStatus_BsReten_Tripcomputer_ElementValue0
          data-element=JobStatus_BsReten_VisDlt_Element, init-value=constant-reference=DcmExtJobStatus_BsReten_VisDlt_ElementValue0
          data-element=JobStatus_BsReten_Warning_Element, init-value=constant-reference=DcmExtJobStatus_BsReten_Warning_ElementValue0
          data-element=JobStatus_BsRt_CusDlt_Element, init-value=constant-reference=DcmExtJobStatus_BsRt_CusDlt_ElementValue0
          data-element=JobStatus_BsRt_FuelGauge_Element, init-value=constant-reference=DcmExtJobStatus_BsRt_FuelGauge_ElementValue0
          data-element=JobStatus_BsRt_Illumination_Element, init-value=constant-reference=DcmExtJobStatus_BsRt_Illumination_ElementValue0
          data-element=JobStatus_BsRt_Odometer_Element, init-value=constant-reference=DcmExtJobStatus_BsRt_Odometer_ElementValue0
          data-element=JobStatus_BsRt_OilGauge_Element, init-value=constant-reference=DcmExtJobStatus_BsRt_OilGauge_ElementValue0
          data-element=JobStatus_BsRt_Personalization_Element, init-value=constant-reference=DcmExtJobStatus_BsRt_Personalization_ElementValue0
          data-element=JobStatus_BsRt_PowerGauge_Element, init-value=constant-reference=DcmExtJobStatus_BsRt_PowerGauge_ElementValue0
          data-element=JobStatus_BsRt_RealTimeClock_Element, init-value=constant-reference=DcmExtJobStatus_BsRt_RealTimeClock_ElementValue0
          data-element=JobStatus_BsRt_SpeedoGauge_Element, init-value=constant-reference=DcmExtJobStatus_BsRt_SpeedoGauge_ElementValue0
          data-element=JobStatus_BsRt_TachoGauge_Element, init-value=constant-reference=DcmExtJobStatus_BsRt_TachoGauge_ElementValue0
          data-element=JobStatus_BsRt_TempGauge_Element, init-value=constant-reference=DcmExtJobStatus_BsRt_TempGauge_ElementValue0
          data-element=JobStatus_BsRt_TripComputer_Element, init-value=constant-reference=DcmExtJobStatus_BsRt_TripComputer_ElementValue0
          data-element=JobStatus_BsRt_Warning_Element, init-value=constant-reference=DcmExtJobStatus_BsRt_Warning_ElementValue0
          data-element=JobStatus_BsShare_AssemblyManufacturingDate, init-value=constant-reference=DcmExtJobStatus_BsShare_AssemblyManufacturingDateValue0
          data-element=JobStatus_BsShare_AssemblyPlantNumber, init-value=constant-reference=DcmExtJobStatus_BsShare_AssemblyPlantNumberValue0
          data-element=JobStatus_BsShare_EcuPartNumber_Element, init-value=constant-reference=DcmExtJobStatus_BsShare_EcuPartNumber_ElementValue0
          data-element=JobStatus_BsShare_HWModification, init-value=constant-reference=DcmExtJobStatus_BsShare_HWModificationValue0
          data-element=JobStatus_BsShare_PCBSerialNumber, init-value=constant-reference=DcmExtJobStatus_BsShare_PCBSerialNumberValue0
          data-element=JobStatus_BsShare_ProductSerialNumber, init-value=constant-reference=DcmExtJobStatus_BsShare_ProductSerialNumberValue0
          data-element=JobStatus_BsShare_SMTManufacturingDate, init-value=constant-reference=DcmExtJobStatus_BsShare_SMTManufacturingDateValue0
          data-element=JobStatus_BsShare_SMTPlantNumber, init-value=constant-reference=DcmExtJobStatus_BsShare_SMTPlantNumberValue0
          data-element=JobStatus_BsShare_SwUpdFotaFinPrint_Element, init-value=constant-reference=DcmExtJobStatus_BsShare_SwUpdFotaFinPrint_ElementValue0
          data-element=JobStatus_BsShare_SwUpdFotaMode_Element, init-value=constant-reference=DcmExtJobStatus_BsShare_SwUpdFotaMode_ElementValue0
          data-element=JobStatus_BsShare_SwUpdFotaStatus_Element, init-value=constant-reference=DcmExtJobStatus_BsShare_SwUpdFotaStatus_ElementValue0
          data-element=JobStatus_BsShare_SwUpdFotadecrypt_Element, init-value=constant-reference=DcmExtJobStatus_BsShare_SwUpdFotadecrypt_ElementValue0
          data-element=JobStatus_BsShare_SwUpdReflash_Element, init-value=constant-reference=DcmExtJobStatus_BsShare_SwUpdReflash_ElementValue0
          data-element=JobStatus_BsShare_VehicleConfig_Element, init-value=constant-reference=DcmExtJobStatus_BsShare_VehicleConfig_ElementValue0
          data-element=JobStatus_BsShare_VisMeet_EOLEntry_Element, init-value=constant-reference=DcmExtJobStatus_BsShare_VisMeet_EOLEntry_ElementValue0
          data-element=JobStatus_BsShare_VisMeet_Element, init-value=constant-reference=DcmExtJobStatus_BsShare_VisMeet_ElementValue0
          data-element=JobStatus_BsShare_VisteonPCBPartNumber, init-value=constant-reference=DcmExtJobStatus_BsShare_VisteonPCBPartNumberValue0
          data-element=JobStatus_BsShare_VisteonPartNumber, init-value=constant-reference=DcmExtJobStatus_BsShare_VisteonPartNumberValue0
          data-element=JobStatus_RefCys_Certicificate1_Element, init-value=constant-reference=DcmExtJobStatus_RefCys_Certicificate1_ElementValue0
          data-element=JobStatus_RefCys_Certicificate_Element, init-value=constant-reference=DcmExtJobStatus_RefCys_Certicificate_ElementValue0
    behavior IB_DcmExt
      9 x operation invoked event:
        OIE_pp_CS_DcmExt_Confirmation_DcmExt_ConfirmationTrigByDcmExt_Confirmation: start-on-event=DcmExt_Confirmation, operation=pp_CS_DcmExt_Confirmation.DcmExt_Confirmation
        OIE_pp_CS_DcmExt_Service_Iocontrol_DcmExt_Service_IocontrolTrigByDcmExt_Service_Iocontrol: start-on-event=DcmExt_Service_Iocontrol, operation=pp_CS_DcmExt_Service_Iocontrol.DcmExt_Service_Iocontrol
        OIE_pp_CS_DcmExt_Services_CndChk_DcmExt_Services_CndChkTrigByDcmExt_Services_CndChk: start-on-event=DcmExt_Services_CndChk, operation=pp_CS_DcmExt_Services_CndChk.DcmExt_Services_CndChk
        OIE_pp_CS_DcmExt_Services_DataRead_DcmExt_Services_DataReadTrigByDcmExt_Services_DataRead: start-on-event=DcmExt_Services_DataRead, operation=pp_CS_DcmExt_Services_DataRead.DcmExt_Services_DataRead
        OIE_pp_CS_DcmExt_Services_DataWrite_DcmExt_Services_DataWriteTrigByDcmExt_Services_DataWrite: start-on-event=DcmExt_Services_DataWrite, operation=pp_CS_DcmExt_Services_DataWrite.DcmExt_Services_DataWrite
        OIE_pp_CS_DcmExt_Services_LenChk_DcmExt_Services_LenChkTrigByDcmExt_Services_LenChk: start-on-event=DcmExt_Services_LenChk, operation=pp_CS_DcmExt_Services_LenChk.DcmExt_Services_LenChk
        OIE_pp_CS_DcmExt_Services_RoutineResults_DcmExt_Services_RoutineResultsTrigByDcmExt_Services_RoutineResults: start-on-event=DcmExt_Services_RoutineResults, operation=pp_CS_DcmExt_Services_RoutineResults.DcmExt_Services_RoutineResults
        OIE_pp_CS_DcmExt_Services_RoutineStart_DcmExt_Services_RoutineStartTrigByDcmExt_Services_RoutineStart: start-on-event=DcmExt_Services_RoutineStart, operation=pp_CS_DcmExt_Services_RoutineStart.DcmExt_Services_RoutineStart
        OIE_pp_CS_DcmExt_Services_RoutineStop_DcmExt_Services_RoutineStopTrigByDcmExt_Services_RoutineStop: start-on-event=DcmExt_Services_RoutineStop, operation=pp_CS_DcmExt_Services_RoutineStop.DcmExt_Services_RoutineStop
      timing event TEDcmExt_MainFunction: start-on-event=DcmExt_MainFunction, period=0.01
      port-api-options:
        enable-take-address=false, indirect-api=false, port=pp_CS_DcmExt_Confirmation
        enable-take-address=false, indirect-api=false, port=pp_CS_DcmExt_Service_Iocontrol
        enable-take-address=false, indirect-api=false, port=pp_CS_DcmExt_Services_CndChk
        enable-take-address=false, indirect-api=false, port=pp_CS_DcmExt_Services_DataRead
        enable-take-address=false, indirect-api=false, port=pp_CS_DcmExt_Services_DataWrite
        enable-take-address=false, indirect-api=false, port=pp_CS_DcmExt_Services_LenChk
        enable-take-address=false, indirect-api=false, port=pp_CS_DcmExt_Services_RoutineResults
        enable-take-address=false, indirect-api=false, port=pp_CS_DcmExt_Services_RoutineStart
        enable-take-address=false, indirect-api=false, port=pp_CS_DcmExt_Services_RoutineStop
        enable-take-address=false, indirect-api=false, port=rp_CS_DID_App_DiagAction
        enable-take-address=false, indirect-api=false, port=rp_CS_DID_DiagAction
        enable-take-address=false, indirect-api=false, port=rp_CS_DiagEntryStatus
        enable-take-address=false, indirect-api=false, port=DcmExt/rp_CS_MemAbsGet
        enable-take-address=false, indirect-api=false, port=DcmExt/rp_CS_MemAbsSet
        enable-take-address=false, indirect-api=false, port=rp_CS_RID_App_DiagAction
        enable-take-address=false, indirect-api=false, port=rp_CS_RID_DiagAction
        enable-take-address=false, indirect-api=false, port=rp_CS_UpdateCdd_DID_DiagAction
        enable-take-address=false, indirect-api=false, port=rp_CS_UpdateCdd_RID_DiagAction
        enable-take-address=false, indirect-api=false, port=rp_CS_UpdateCdd_Service_0x34_Handler
        enable-take-address=false, indirect-api=false, port=rp_CS_UpdateCdd_Service_0x36_Handler
        enable-take-address=false, indirect-api=false, port=rp_CS_UpdateCdd_Service_0x37_Handler
        enable-take-address=false, indirect-api=false, port=DcmExt/rp_SR_JobStatus
